VERSION ""

NS_ :

BS_:

BU_: WCM4 WCM3 WCM2 WCM VPM VLM VKM VICM VECM VDM VCU_RTOS_ETH VCU_ENTRY_ETH VCU_AGVM_ETH VCU UVM UPM TIM TEST_TOOL_1 TCP_ETH TCP TCM TCCM SRR_SRR_ETH SRR_SRR SRR_SLR_ETH SRR_SLR SRR_RR SRR_RF_ETH SRR_RF SRR_LR_CR SRR_LF_ETH SRR_LF SIB SDM SCL SBZA_R SBZA_L SBM SAM_RR SAM_RF SAM_LR SAM_LF SAM_BH SADS RadioLow_ETH RadioLow RSI_RTOS_ETH RSI RDCM PTM PLCM PFCM PDR_ETH PDR PCM PA ODS2 ODS NVM MTCM_R MTCM_L MSM_RR MSM_P MSM_LR MSM_D MSB2 MSB1 MRCM_R MRCM_L MFC LRR_RR_ETH LRR_LR_ETH LRR_CF_ETH LRR LRL_CF_ETH LIB_48V LIB1 IPC_INT IPC_GP IPC ICS_Info ICCM HVAC_FP_R HVAC_FP_F HUD_CAN HDLM FPI_RTOS_ETH FPI FOPM FCM_LC FCM EPSb EPS_1 EPSRAb EPSRAa EPS EOCM_HC_Superset EOCM_HCP2 EOCM ELM ECP_X1 ECP_S2 ECP_S ECP_MC ECP_H3 ECP_H2 ECP_H1 ECP_E ECM EBCM DMS DEFC DCM CSM_ETH CSM_AV CSM CGM_OTA_ETH CGM BSM_MH BSM_HEV BSM BCM ARS ARB APA AOS AMP ALC AHS AHL_AFL ADIMb ADIMa ACP2_MCU

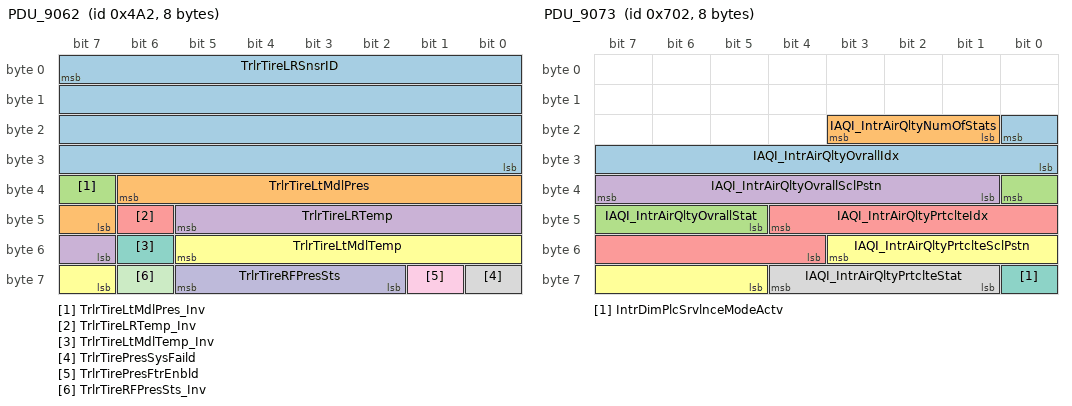
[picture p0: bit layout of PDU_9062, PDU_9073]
BO_ 1186 PDU_9062: 8 CGM
 SG_ TrlrTireLRSnsrID : 7|32@0+ (1,0) [0|4.29497e+009] "" CSM,CSM_AV,VCU
 SG_ TrlrTireLtMdlPres : 38|8@0+ (4,0) [0|1020] "kPaG" VKM,CSM,CSM_AV,VCU
 SG_ TrlrTireLtMdlPres_Inv : 39|1@0+ (1,0) [0|1] "" VKM,CSM,CSM_AV,VCU
 SG_ TrlrTireLRTemp : 45|7@0+ (1,-20) [-20|107] "degC" CSM,CSM_AV,VCU
 SG_ TrlrTireLRTemp_Inv : 46|1@0+ (1,0) [0|1] "" CSM,CSM_AV,VCU
 SG_ TrlrTireLtMdlTemp : 53|7@0+ (1,-20) [-20|107] "degC" CSM,CSM_AV,VCU
 SG_ TrlrTireLtMdlTemp_Inv : 54|1@0+ (1,0) [0|1] "" CSM,CSM_AV,VCU
 SG_ TrlrTirePresSysFaild : 56|1@0+ (1,0) [0|1] "" CSM,CSM_AV,VCU
 SG_ TrlrTirePresFtrEnbld : 57|1@0+ (1,0) [0|1] "" CSM,CSM_AV,VCU
 SG_ TrlrTireRFPresSts : 61|4@0+ (1,0) [0|8] "" VKM,CSM,CSM_AV,VCU
 SG_ TrlrTireRFPresSts_Inv : 62|1@0+ (1,0) [0|1] "" VKM,CSM,CSM_AV,VCU

BO_ 1889 PDU_9063: 8 CGM
 SG_ WlkAwyLckCstAvlFlg1 : 0|1@0+ (1,0) [0|1] "" RadioLow,CSM,CSM_AV,VCU
 SG_ VehLctrLghtsCstAvlFlg7 : 1|1@0+ (1,0) [0|1] "" RadioLow,CSM,CSM_AV,VCU
 SG_ VehLctrLghtsCstAvlFlg6 : 2|1@0+ (1,0) [0|1] "" RadioLow,CSM,CSM_AV,VCU
 SG_ VehLctrLghtsCstAvlFlg5 : 3|1@0+ (1,0) [0|1] "" RadioLow,CSM,CSM_AV,VCU
 SG_ VehLctrLghtsCstAvlFlg4 : 4|1@0+ (1,0) [0|1] "" RadioLow,CSM,CSM_AV,VCU
 SG_ VehLctrLghtsCstAvlFlg3 : 5|1@0+ (1,0) [0|1] "" RadioLow,CSM,CSM_AV,VCU
 SG_ VehLctrLghtsCstAvlFlg2 : 6|1@0+ (1,0) [0|1] "" RadioLow,CSM,CSM_AV,VCU
 SG_ VehLctrLghtsCstAvlFlg1 : 7|1@0+ (1,0) [0|1] "" RadioLow,CSM,CSM_AV,VCU
 SG_ AmbtLgtGblPrxmtyEnCstAvlFlg2 : 8|1@0+ (1,0) [0|1] "" VCU
 SG_ AmbtLgtGblPrxmtyEnCstAvlFlg1 : 9|1@0+ (1,0) [0|1] "" VCU
 SG_ WlkAwyLckCstAvlFlg7 : 10|1@0+ (1,0) [0|1] "" RadioLow,CSM,CSM_AV,VCU
 SG_ WlkAwyLckCstAvlFlg6 : 11|1@0+ (1,0) [0|1] "" RadioLow,CSM,CSM_AV,VCU
 SG_ WlkAwyLckCstAvlFlg5 : 12|1@0+ (1,0) [0|1] "" RadioLow,CSM,CSM_AV,VCU
 SG_ WlkAwyLckCstAvlFlg4 : 13|1@0+ (1,0) [0|1] "" RadioLow,CSM,CSM_AV,VCU
 SG_ WlkAwyLckCstAvlFlg3 : 14|1@0+ (1,0) [0|1] "" RadioLow,CSM,CSM_AV,VCU
 SG_ WlkAwyLckCstAvlFlg2 : 15|1@0+ (1,0) [0|1] "" RadioLow,CSM,CSM_AV,VCU
 SG_ Aux1AmbtColrCtlCstAvlFlg33 : 16|1@0+ (1,0) [0|1] "" VCU
 SG_ Aux1AmbtColrCtlCstAvlFlg32 : 17|1@0+ (1,0) [0|1] "" VCU
 SG_ AmbtLgtGblPrxmtyEnCstSetAval : 18|1@0+ (1,0) [0|1] "" VCU
 SG_ AmbtLgtGblPrxmtyEnCstAvlFlg7 : 19|1@0+ (1,0) [0|1] "" VCU
 SG_ AmbtLgtGblPrxmtyEnCstAvlFlg6 : 20|1@0+ (1,0) [0|1] "" VCU
 SG_ AmbtLgtGblPrxmtyEnCstAvlFlg5 : 21|1@0+ (1,0) [0|1] "" VCU
 SG_ AmbtLgtGblPrxmtyEnCstAvlFlg4 : 22|1@0+ (1,0) [0|1] "" VCU
 SG_ AmbtLgtGblPrxmtyEnCstAvlFlg3 : 23|1@0+ (1,0) [0|1] "" VCU
 SG_ Aux1AmbtColrCtlCstAvlFlg41 : 24|1@0+ (1,0) [0|1] "" VCU
 SG_ Aux1AmbtColrCtlCstAvlFlg40 : 25|1@0+ (1,0) [0|1] "" VCU
 SG_ Aux1AmbtColrCtlCstAvlFlg39 : 26|1@0+ (1,0) [0|1] "" VCU
 SG_ Aux1AmbtColrCtlCstAvlFlg38 : 27|1@0+ (1,0) [0|1] "" VCU
 SG_ Aux1AmbtColrCtlCstAvlFlg37 : 28|1@0+ (1,0) [0|1] "" VCU
 SG_ Aux1AmbtColrCtlCstAvlFlg36 : 29|1@0+ (1,0) [0|1] "" VCU
 SG_ Aux1AmbtColrCtlCstAvlFlg35 : 30|1@0+ (1,0) [0|1] "" VCU
 SG_ Aux1AmbtColrCtlCstAvlFlg34 : 31|1@0+ (1,0) [0|1] "" VCU
 SG_ Aux1AmbtColrCtlCstAvlFlg49 : 32|1@0+ (1,0) [0|1] "" VCU
 SG_ Aux1AmbtColrCtlCstAvlFlg48 : 33|1@0+ (1,0) [0|1] "" VCU
 SG_ Aux1AmbtColrCtlCstAvlFlg47 : 34|1@0+ (1,0) [0|1] "" VCU
 SG_ Aux1AmbtColrCtlCstAvlFlg46 : 35|1@0+ (1,0) [0|1] "" VCU
 SG_ Aux1AmbtColrCtlCstAvlFlg45 : 36|1@0+ (1,0) [0|1] "" VCU
 SG_ Aux1AmbtColrCtlCstAvlFlg44 : 37|1@0+ (1,0) [0|1] "" VCU
 SG_ Aux1AmbtColrCtlCstAvlFlg43 : 38|1@0+ (1,0) [0|1] "" VCU
 SG_ Aux1AmbtColrCtlCstAvlFlg42 : 39|1@0+ (1,0) [0|1] "" VCU
 SG_ Aux1AmbtColrCtlCstAvlFlg57 : 40|1@0+ (1,0) [0|1] "" VCU
 SG_ Aux1AmbtColrCtlCstAvlFlg56 : 41|1@0+ (1,0) [0|1] "" VCU
 SG_ Aux1AmbtColrCtlCstAvlFlg55 : 42|1@0+ (1,0) [0|1] "" VCU
 SG_ Aux1AmbtColrCtlCstAvlFlg54 : 43|1@0+ (1,0) [0|1] "" VCU
 SG_ Aux1AmbtColrCtlCstAvlFlg53 : 44|1@0+ (1,0) [0|1] "" VCU
 SG_ Aux1AmbtColrCtlCstAvlFlg52 : 45|1@0+ (1,0) [0|1] "" VCU
 SG_ Aux1AmbtColrCtlCstAvlFlg51 : 46|1@0+ (1,0) [0|1] "" VCU
 SG_ Aux1AmbtColrCtlCstAvlFlg50 : 47|1@0+ (1,0) [0|1] "" VCU
 SG_ Aux1AmbtColrCtlCstAvlFlg65 : 48|1@0+ (1,0) [0|1] "" VCU
 SG_ Aux1AmbtColrCtlCstAvlFlg64 : 49|1@0+ (1,0) [0|1] "" VCU
 SG_ Aux1AmbtColrCtlCstAvlFlg63 : 50|1@0+ (1,0) [0|1] "" VCU
 SG_ Aux1AmbtColrCtlCstAvlFlg62 : 51|1@0+ (1,0) [0|1] "" VCU
 SG_ Aux1AmbtColrCtlCstAvlFlg61 : 52|1@0+ (1,0) [0|1] "" VCU
 SG_ Aux1AmbtColrCtlCstAvlFlg60 : 53|1@0+ (1,0) [0|1] "" VCU
 SG_ Aux1AmbtColrCtlCstAvlFlg59 : 54|1@0+ (1,0) [0|1] "" VCU
 SG_ Aux1AmbtColrCtlCstAvlFlg58 : 55|1@0+ (1,0) [0|1] "" VCU
 SG_ Aux1AmbtColrCtlCstAvlFlg73 : 56|1@0+ (1,0) [0|1] "" VCU
 SG_ Aux1AmbtColrCtlCstAvlFlg72 : 57|1@0+ (1,0) [0|1] "" VCU
 SG_ Aux1AmbtColrCtlCstAvlFlg71 : 58|1@0+ (1,0) [0|1] "" VCU
 SG_ Aux1AmbtColrCtlCstAvlFlg70 : 59|1@0+ (1,0) [0|1] "" VCU
 SG_ Aux1AmbtColrCtlCstAvlFlg69 : 60|1@0+ (1,0) [0|1] "" VCU
 SG_ Aux1AmbtColrCtlCstAvlFlg68 : 61|1@0+ (1,0) [0|1] "" VCU
 SG_ Aux1AmbtColrCtlCstAvlFlg67 : 62|1@0+ (1,0) [0|1] "" VCU
 SG_ Aux1AmbtColrCtlCstAvlFlg66 : 63|1@0+ (1,0) [0|1] "" VCU

BO_ 1810 PDU_9064: 2 CGM
 SG_ VehIdNmDig1 : 7|8@0+ (1,0) [0|255] "" FPI,RSI,RadioLow,TCP,CSM,CSM_AV,VCU

BO_ 1880 PDU_9065: 8 CGM
 SG_ TrlrTireLtMdlSnsrID : 7|32@0+ (1,0) [0|4.29497e+009] "" CSM,CSM_AV,VCU
 SG_ TrlrTireRFSnsrID : 39|32@0+ (1,0) [0|4.29497e+009] "" CSM,CSM_AV,VCU

BO_ 1185 PDU_9066: 8 CGM
 SG_ TrlrTireRRSnsrID : 7|32@0+ (1,0) [0|4.29497e+009] "" CSM,CSM_AV,VCU
 SG_ TrlrTireRtMdlSnsrID : 39|32@0+ (1,0) [0|4.29497e+009] "" CSM,CSM_AV,VCU

BO_ 1881 PDU_9067: 8 CGM
 SG_ TrlrTireRFPres : 6|8@0+ (4,0) [0|1020] "kPaG" VKM,CSM,CSM_AV,VCU
 SG_ TrlrTireRFPres_Inv : 7|1@0+ (1,0) [0|1] "" VKM,CSM,CSM_AV,VCU
 SG_ TrlrTireRRPres : 13|8@0+ (4,0) [0|1020] "kPaG" VKM,CSM,CSM_AV,VCU
 SG_ TrlrTireRRPres_Inv : 14|1@0+ (1,0) [0|1] "" VKM,CSM,CSM_AV,VCU
 SG_ TrlrTireRtMdlPres : 20|8@0+ (4,0) [0|1020] "kPaG" VKM,CSM,CSM_AV,VCU
 SG_ TrlrTireRtMdlPres_Inv : 21|1@0+ (1,0) [0|1] "" VKM,CSM,CSM_AV,VCU
 SG_ TrlrTireRFTemp : 27|7@0+ (1,-20) [-20|107] "degC" CSM,CSM_AV,VCU
 SG_ TrlrTireRFTemp_Inv : 28|1@0+ (1,0) [0|1] "" CSM,CSM_AV,VCU
 SG_ TrlrTireRRTemp : 35|7@0+ (1,-20) [-20|107] "degC" CSM,CSM_AV,VCU
 SG_ TrlrTireRRTemp_Inv : 36|1@0+ (1,0) [0|1] "" CSM,CSM_AV,VCU
 SG_ TrlrTireRtMdlTemp : 43|7@0+ (1,-20) [-20|107] "degC" CSM,CSM_AV,VCU
 SG_ TrlrTireRtMdlTemp_Inv : 44|1@0+ (1,0) [0|1] "" CSM,CSM_AV,VCU
 SG_ TrlrTireRRPresSts : 51|4@0+ (1,0) [0|8] "" VKM,CSM,CSM_AV,VCU
 SG_ TrlrTireRRPresSts_Inv : 52|1@0+ (1,0) [0|1] "" VKM,CSM,CSM_AV,VCU
 SG_ Aux1AmbtColrCtlCstAvlFlg86 : 56|1@0+ (1,0) [0|1] "" VCU
 SG_ Aux1AmbtColrCtlCstAvlFlg85 : 57|1@0+ (1,0) [0|1] "" VCU
 SG_ Aux1AmbtColrCtlCstAvlFlg84 : 58|1@0+ (1,0) [0|1] "" VCU
 SG_ TrlrTireRtMdlPresSts : 62|4@0+ (1,0) [0|8] "" VKM,CSM,CSM_AV,VCU
 SG_ TrlrTireRtMdlPresSts_Inv : 63|1@0+ (1,0) [0|1] "" VKM,CSM,CSM_AV,VCU

BO_ 1184 PDU_9068: 8 CGM
 SG_ VCCLS_CrgLmpHtchAval : 0|1@0+ (1,0) [0|1] "" VCU
 SG_ VCCLS_CrgLmpCurrSeltnVal : 2|2@0+ (1,0) [0|2] "" VCU
 SG_ VCCLS_CrgLmpAval : 3|1@0+ (1,0) [0|1] "" VCU
 SG_ VCCLS_CrgBedLmpCurrSeltnVal : 5|2@0+ (1,0) [0|2] "" VCU
 SG_ VCCLS_CrgBedLmpAval : 6|1@0+ (1,0) [0|1] "" VCU
 SG_ VCCLS_AllCrgLmpUsrCtlAllwd : 7|1@0+ (1,0) [0|1] "" VCU
 SG_ VCDLS_DomeDftCurrSeltnVal : 9|2@0+ (1,0) [0|2] "" VCU
 SG_ VCDLS_DomeDftAval : 10|1@0+ (1,0) [0|1] "" VCU
 SG_ VCCLS_CrgMirLmpCurrSeltnVal : 12|2@0+ (1,0) [0|2] "" VCU
 SG_ VCCLS_CrgMirLmpAval : 13|1@0+ (1,0) [0|1] "" VCU
 SG_ VCCLS_CrgLmpHtchCurrSeltnVal : 15|2@0+ (1,0) [0|2] "" VCU
 SG_ VCCSLS_CtlAval : 16|1@0+ (1,0) [0|1] "" VCU
 SG_ VCAHBS_UsrCtlAllwd : 17|1@0+ (1,0) [0|1] "" VCU
 SG_ VCAHBS_CurrSeltnVal : 19|2@0+ (1,0) [0|2] "" VCU
 SG_ VCAHBS_CtlAval : 20|1@0+ (1,0) [0|1] "" VCU
 SG_ VCDLS_DomeLgtCurrSeltnVal : 22|2@0+ (1,0) [0|2] "" VCU
 SG_ VCDLS_DomeLgtAval : 23|1@0+ (1,0) [0|1] "" VCU
 SG_ VCFLRS_CtlAval : 24|1@0+ (1,0) [0|1] "" VCU
 SG_ VCFLFS_UsrCtlAllwd : 25|1@0+ (1,0) [0|1] "" VCU
 SG_ VCFLFS_CurrSeltnVal : 27|2@0+ (1,0) [0|2] "" VCU
 SG_ VCFLFS_CtlAval : 28|1@0+ (1,0) [0|1] "" VCU
 SG_ VCCSLS_MsmtchIndOn : 29|1@0+ (1,0) [0|1] "" VCU
 SG_ VCCSLS_CurrSeltnVal : 31|2@0+ (1,0) [0|2] "" VCU
 SG_ RrBlw2Cmd : 33|10@0+ (0.09765,0) [0|99.8959] "%" VCU
 SG_ VCPWLS_CurrSeltnVal : 35|2@0+ (1,0) [0|2] "" VCU
 SG_ VCPWLS_CtlAval : 36|1@0+ (1,0) [0|1] "" VCU
 SG_ VCFLRS_UsrCtlAllwd : 37|1@0+ (1,0) [0|1] "" VCU
 SG_ VCFLRS_CurrSeltnVal : 39|2@0+ (1,0) [0|2] "" VCU
 SG_ CbnAirClnFltrtnCstCurrSetVal : 49|3@0+ (1,0) [0|2] "" VCU
 SG_ AutoNckScrfCstCurrSetVal : 52|3@0+ (1,0) [0|3] "" VCU
 SG_ AutoAirOtltAmgCstCurrSetVal : 55|3@0+ (1,0) [0|2] "" VCU
 SG_ FrtClsrAccssVirtCtlAval : 58|1@0+ (1,0) [0|1] "" VCU
 SG_ FrtClsrAccssVirtCtlAllwd : 59|1@0+ (1,0) [0|1] "" VCU
 SG_ DlvryModeWrnIndReq : 62|3@0+ (1,0) [0|4] "" VCU

BO_ 1412 PDU_9069: 8 CGM
 SG_ IHVSLR_HtdCushBckLvl2 : 0|1@0+ (1,0) [0|1] "" HVAC_FP_R,VCU
 SG_ IHVSLR_HtdCushBckLvl1 : 1|1@0+ (1,0) [0|1] "" HVAC_FP_R,VCU
 SG_ IHVSLR_HtdCushBckAuto : 2|1@0+ (1,0) [0|1] "" HVAC_FP_R,VCU
 SG_ IHVSLR_HtdBckMd : 3|1@0+ (1,0) [0|1] "" HVAC_FP_R,VCU
 SG_ IHVSLR_HtdBckLvl3 : 4|1@0+ (1,0) [0|1] "" HVAC_FP_R,VCU
 SG_ IHVSLR_HtdBckLvl2 : 5|1@0+ (1,0) [0|1] "" HVAC_FP_R,VCU
 SG_ IHVSLR_HtdBckLvl1 : 6|1@0+ (1,0) [0|1] "" HVAC_FP_R,VCU
 SG_ IHVSLR_HtdBckAuto : 7|1@0+ (1,0) [0|1] "" HVAC_FP_R,VCU
 SG_ IHVSRR_HtdBckAuto : 8|1@0+ (1,0) [0|1] "" HVAC_FP_R,VCU
 SG_ IHVSLR_VntMd : 9|1@0+ (1,0) [0|1] "" HVAC_FP_R,VCU
 SG_ IHVSLR_VntLvl3 : 10|1@0+ (1,0) [0|1] "" HVAC_FP_R,VCU
 SG_ IHVSLR_VntLvl2 : 11|1@0+ (1,0) [0|1] "" HVAC_FP_R,VCU
 SG_ IHVSLR_VntLvl1 : 12|1@0+ (1,0) [0|1] "" HVAC_FP_R,VCU
 SG_ IHVSLR_VntAuto : 13|1@0+ (1,0) [0|1] "" HVAC_FP_R,VCU
 SG_ IHVSLR_HtdCushBckMd : 14|1@0+ (1,0) [0|1] "" HVAC_FP_R,VCU
 SG_ IHVSLR_HtdCushBckLvl3 : 15|1@0+ (1,0) [0|1] "" HVAC_FP_R,VCU
 SG_ IHVSRR_HtdCushBckLvl3 : 16|1@0+ (1,0) [0|1] "" HVAC_FP_R,VCU
 SG_ IHVSRR_HtdCushBckLvl2 : 17|1@0+ (1,0) [0|1] "" HVAC_FP_R,VCU
 SG_ IHVSRR_HtdCushBckLvl1 : 18|1@0+ (1,0) [0|1] "" HVAC_FP_R,VCU
 SG_ IHVSRR_HtdCushBckAuto : 19|1@0+ (1,0) [0|1] "" HVAC_FP_R,VCU
 SG_ IHVSRR_HtdBckMd : 20|1@0+ (1,0) [0|1] "" HVAC_FP_R,VCU
 SG_ IHVSRR_HtdBckLvl3 : 21|1@0+ (1,0) [0|1] "" HVAC_FP_R,VCU
 SG_ IHVSRR_HtdBckLvl2 : 22|1@0+ (1,0) [0|1] "" HVAC_FP_R,VCU
 SG_ IHVSRR_HtdBckLvl1 : 23|1@0+ (1,0) [0|1] "" HVAC_FP_R,VCU
 SG_ BatSvrMdSevLvl : 25|8@0+ (1,0) [0|255] "" RadioLow,TCP,CSM,CSM_AV,VCU
 SG_ IHVSRR_VntMd : 26|1@0+ (1,0) [0|1] "" HVAC_FP_R,VCU
 SG_ IHVSRR_VntLvl3 : 27|1@0+ (1,0) [0|1] "" HVAC_FP_R,VCU
 SG_ IHVSRR_VntLvl2 : 28|1@0+ (1,0) [0|1] "" HVAC_FP_R,VCU
 SG_ IHVSRR_VntLvl1 : 29|1@0+ (1,0) [0|1] "" HVAC_FP_R,VCU
 SG_ IHVSRR_VntAuto : 30|1@0+ (1,0) [0|1] "" HVAC_FP_R,VCU
 SG_ IHVSRR_HtdCushBckMd : 31|1@0+ (1,0) [0|1] "" HVAC_FP_R,VCU
 SG_ ClmCtlCbnAirCondCustLdEstd : 33|7@0+ (1,0) [0|127] "%" IPC,IPC_INT,VCU
 SG_ IndAirDstFL : 42|4@0+ (1,0) [0|9] "" HVAC_FP_F,HVAC_FP_R,RadioLow,CSM,CSM_AV,IPC,IPC_INT,VCU
 SG_ DrHndlLFAuthReqd : 48|1@0+ (1,0) [0|1] "" VKM
 SG_ AirDflctrIndReq : 50|2@0+ (1,0) [0|2] "" IPC,IPC_INT,VCU
 SG_ IndAirDstFR : 54|4@0+ (1,0) [0|9] "" HVAC_FP_F,HVAC_FP_R,RadioLow,CSM,CSM_AV,VCU
 SG_ HVACUsrCtlIntrctnDispReqd : 59|1@0+ (1,0) [0|1] "" RadioLow,CSM,CSM_AV,VCU
 SG_ FrtClsrRelAuthReqd : 60|1@0+ (1,0) [0|1] "" VKM
 SG_ DrHndlRRAuthReqd : 61|1@0+ (1,0) [0|1] "" VKM
 SG_ DrHndlRFAuthReqd : 62|1@0+ (1,0) [0|1] "" VKM
 SG_ DrHndlLRAuthReqd : 63|1@0+ (1,0) [0|1] "" VKM

BO_ 1413 PDU_9070: 8 CGM
 SG_ IndTmpStngLvlFR : 0|7@0+ (1,0) [0|127] "" HVAC_FP_F,RadioLow,CSM,CSM_AV,VCU
 SG_ IndTmpStngLvlFL : 7|7@0+ (1,0) [0|127] "" HVAC_FP_F,RadioLow,TCP,CSM,CSM_AV,VCU
 SG_ IndTmpStngLvlRL : 9|7@0+ (1,0) [0|127] "" HVAC_FP_F,HVAC_FP_R,RadioLow,CSM,CSM_AV,VCU
 SG_ IndTmpStngLvlRR : 18|7@0+ (1,0) [0|127] "" HVAC_FP_F,HVAC_FP_R,RadioLow,CSM,CSM_AV,VCU
 SG_ IndAirDstRL : 27|4@0+ (1,0) [0|8] "" HVAC_FP_F,HVAC_FP_R,RadioLow,CSM,CSM_AV,VCU
 SG_ IndBlwStngLvlFrt : 35|4@0+ (1,0) [0|15] "" HVAC_FP_F,RadioLow,CSM,CSM_AV,VCU
 SG_ IndAirDstRR : 39|4@0+ (1,0) [0|8] "" HVAC_FP_F,HVAC_FP_R,RadioLow,CSM,CSM_AV,VCU
 SG_ IndBlwStngStRr : 41|2@0+ (1,0) [0|2] "" HVAC_FP_F,HVAC_FP_R,RadioLow,CSM,CSM_AV,VCU
 SG_ IndBlwStngStFrt : 43|2@0+ (1,0) [0|2] "" HVAC_FP_F,RadioLow,CSM,CSM_AV,VCU
 SG_ IndBlwStngLvlRr : 47|4@0+ (1,0) [0|15] "" HVAC_FP_F,HVAC_FP_R,RadioLow,CSM,CSM_AV,VCU
 SG_ IndHtdFrtWshldSet : 48|1@0+ (1,0) [0|1] "" HVAC_FP_F,RadioLow,CSM,CSM_AV,VCU
 SG_ IndFrtHVAC_On : 49|1@0+ (1,0) [0|1] "" HVAC_FP_F,RadioLow,CSM,CSM_AV,VCU
 SG_ IndRecircStng : 51|2@0+ (1,0) [0|2] "" HVAC_FP_F,RadioLow,CSM,CSM_AV,VCU
 SG_ IndCompStng : 53|2@0+ (1,0) [0|3] "" HVAC_FP_F,RadioLow,CSM,CSM_AV,IPC,IPC_INT,VCU
 SG_ IndSYNC_Rr : 59|1@0+ (1,0) [0|1] "" HVAC_FP_F,HVAC_FP_R,RadioLow,CSM,CSM_AV,VCU
 SG_ IndSYNC_All : 60|1@0+ (1,0) [0|1] "" HVAC_FP_F,HVAC_FP_R,RadioLow,CSM,CSM_AV,VCU
 SG_ IndRrWndDfgStng : 61|1@0+ (1,0) [0|1] "" HVAC_FP_F,RadioLow,CSM,CSM_AV,IPC,IPC_INT,VCU
 SG_ IndRrHVAC_On : 62|1@0+ (1,0) [0|1] "" HVAC_FP_F,HVAC_FP_R,RadioLow,CSM,CSM_AV,VCU
 SG_ IndRrHVAC_Lckd : 63|1@0+ (1,0) [0|1] "" HVAC_FP_F,HVAC_FP_R,RadioLow,CSM,CSM_AV,VCU

BO_ 1414 PDU_9071: 8 CGM
 SG_ IndTmpStngStRL : 1|3@0+ (1,0) [0|4] "" HVAC_FP_F,HVAC_FP_R,RadioLow,CSM,CSM_AV,VCU
 SG_ IndTmpStngStFR : 4|3@0+ (1,0) [0|4] "" HVAC_FP_F,RadioLow,CSM,CSM_AV,VCU
 SG_ IndTmpStngStFL : 7|3@0+ (1,0) [0|4] "" HVAC_FP_F,RadioLow,TCP,CSM,CSM_AV,VCU
 SG_ PwrRrClsrCstCurrSetVal : 8|3@0+ (1,0) [0|7] "" RadioLow,VKM,CSM,CSM_AV,VCU
 SG_ PFASndSeltnCstCurrSetVal : 11|3@0+ (1,0) [0|7] "" CSM,CSM_AV,VCU
 SG_ IndTmpStngStRR : 14|3@0+ (1,0) [0|4] "" HVAC_FP_F,HVAC_FP_R,RadioLow,CSM,CSM_AV,VCU
 SG_ ManlPrkLmpChmEvtSt : 17|2@0+ (1,0) [0|2] "" IPC,IPC_INT,VCU
 SG_ LDCLDlydLkChmEvSt : 19|2@0+ (1,0) [0|2] "" IPC,IPC_INT,VCU
 SG_ KeyInRmdrChmEvntSt : 21|2@0+ (1,0) [0|2] "" IPC,IPC_INT,VCU
 SG_ PwrRrClsrNtfnChmEvntStat : 25|2@0+ (1,0) [0|2] "" CSM,CSM_AV,IPC,IPC_INT,VCU
 SG_ PwrRrClsrNormOpChmEvntStat : 27|2@0+ (1,0) [0|2] "" CSM,CSM_AV,IPC,IPC_INT,VCU
 SG_ OneSidedPrkLmpActvnChmEvtSt : 29|2@0+ (1,0) [0|2] "" IPC,IPC_INT,VCU
 SG_ NoRtDetWrngChmEvSt : 31|2@0+ (1,0) [0|2] "" IPC,IPC_INT,VCU
 SG_ RetainedACCpwrStatus : 32|1@0+ (1,0) [0|1] "" TCP
 SG_ PMMiRAPStatus : 33|1@0+ (1,0) [0|1] "" WCM,WCM2,WCM3,WCM4
 SG_ ShfttoPrkChmEvntSt : 35|2@0+ (1,0) [0|2] "" IPC,IPC_INT,VCU
 SG_ RemLtInVhWrngChmEvSt : 37|2@0+ (1,0) [0|2] "" IPC,IPC_INT,VCU
 SG_ PwrRrClsrObstclChmEvntStat : 39|2@0+ (1,0) [0|2] "" CSM,CSM_AV,IPC,IPC_INT,VCU
 SG_ PFASndSeltnCstSetAval : 40|1@0+ (1,0) [0|1] "" CSM,CSM_AV,VCU
 SG_ PFASndSeltnCstAvlFlg7 : 41|1@0+ (1,0) [0|1] "" CSM,CSM_AV,VCU
 SG_ PFASndSeltnCstAvlFlg6 : 42|1@0+ (1,0) [0|1] "" CSM,CSM_AV,VCU
 SG_ PFASndSeltnCstAvlFlg5 : 43|1@0+ (1,0) [0|1] "" CSM,CSM_AV,VCU
 SG_ PFASndSeltnCstAvlFlg4 : 44|1@0+ (1,0) [0|1] "" CSM,CSM_AV,VCU
 SG_ PFASndSeltnCstAvlFlg3 : 45|1@0+ (1,0) [0|1] "" CSM,CSM_AV,VCU
 SG_ PFASndSeltnCstAvlFlg2 : 46|1@0+ (1,0) [0|1] "" CSM,CSM_AV,VCU
 SG_ PFASndSeltnCstAvlFlg1 : 47|1@0+ (1,0) [0|1] "" CSM,CSM_AV,VCU
 SG_ PwrRrClsrCstSetAval : 48|1@0+ (1,0) [0|1] "" RadioLow,CSM,CSM_AV,VCU
 SG_ PwrRrClsrCstAvlFlg7 : 49|1@0+ (1,0) [0|1] "" RadioLow,CSM,CSM_AV,VCU
 SG_ PwrRrClsrCstAvlFlg6 : 50|1@0+ (1,0) [0|1] "" RadioLow,CSM,CSM_AV,VCU
 SG_ PwrRrClsrCstAvlFlg5 : 51|1@0+ (1,0) [0|1] "" RadioLow,CSM,CSM_AV,VCU
 SG_ PwrRrClsrCstAvlFlg4 : 52|1@0+ (1,0) [0|1] "" RadioLow,CSM,CSM_AV,VCU
 SG_ PwrRrClsrCstAvlFlg3 : 53|1@0+ (1,0) [0|1] "" RadioLow,CSM,CSM_AV,VCU
 SG_ PwrRrClsrCstAvlFlg2 : 54|1@0+ (1,0) [0|1] "" RadioLow,CSM,CSM_AV,VCU
 SG_ PwrRrClsrCstAvlFlg1 : 55|1@0+ (1,0) [0|1] "" RadioLow,CSM,CSM_AV,VCU
 SG_ StBltShfIntlkCstAvlFlg7 : 56|1@0+ (1,0) [0|1] "" RadioLow,CSM,CSM_AV,VCU
 SG_ StBltShfIntlkCstAvlFlg6 : 57|1@0+ (1,0) [0|1] "" RadioLow,CSM,CSM_AV,VCU
 SG_ StBltShfIntlkCstAvlFlg5 : 58|1@0+ (1,0) [0|1] "" RadioLow,CSM,CSM_AV,VCU
 SG_ StBltShfIntlkCstAvlFlg4 : 59|1@0+ (1,0) [0|1] "" RadioLow,CSM,CSM_AV,VCU
 SG_ StBltShfIntlkCstAvlFlg3 : 60|1@0+ (1,0) [0|1] "" RadioLow,CSM,CSM_AV,VCU
 SG_ StBltShfIntlkCstAvlFlg2 : 61|1@0+ (1,0) [0|1] "" RadioLow,CSM,CSM_AV,VCU
 SG_ StBltShfIntlkCstAvlFlg1 : 62|1@0+ (1,0) [0|1] "" RadioLow,CSM,CSM_AV,VCU
 SG_ RrClsrRelAuthReqd : 63|1@0+ (1,0) [0|1] "" VKM

BO_ 1272 PDU_9072: 8 CGM
 SG_ IndInzrStat : 2|3@0+ (1,0) [0|4] "" HVAC_FP_F,RadioLow,CSM,CSM_AV,VCU
 SG_ ConThftAlrmTrg : 7|5@0+ (1,0) [0|20] "" TCP,VKM
 SG_ ClmCtlBatSvrIndOn : 8|1@0+ (1,0) [0|1] "" IPC,IPC_INT,VCU
 SG_ AutoLgtsInActvIndOn : 9|1@0+ (1,0) [0|1] "" CSM,CSM_AV,IPC,IPC_INT,VCU
 SG_ AutoLgtsActvIndOn : 10|1@0+ (1,0) [0|1] "" CSM,CSM_AV,IPC,IPC_INT,VCU
 SG_ ACCmpsrOprtng : 11|1@0+ (1,0) [0|1] "" TCP
 SG_ HtdStrgWhlInd_HVAC_FP_F : 13|2@0+ (1,0) [0|3] "" HVAC_FP_F
 SG_ HtdFrntWSSt : 15|2@0+ (1,0) [0|2] "" IPC,IPC_INT,VCU
 SG_ ConThftSrvcIO : 16|1@0+ (1,0) [0|1] "" TCP,CSM,CSM_AV,IPC,IPC_INT,VCU
 SG_ ConThftAttmpdIO : 17|1@0+ (1,0) [0|1] "" TCP,CSM,CSM_AV,IPC,IPC_INT,VCU
 SG_ CnvtBkWndNotNormzIO : 18|1@0+ (1,0) [0|1] "" IPC,IPC_INT,VCU
 SG_ CmpSftTopMotBfrOpTrnkIO : 19|1@0+ (1,0) [0|1] "" CSM,CSM_AV,IPC,IPC_INT,VCU
 SG_ CmbdDrHndlActvRF : 20|1@0+ (1,0) [0|1] "" CSM,CSM_AV,VCU
 SG_ CmbdDrHndlActvLF : 21|1@0+ (1,0) [0|1] "" CSM,CSM_AV,VCU
 SG_ DrIntHndlActnStatLF : 24|1@0+ (1,0) [0|1] "" RadioLow,CSM,CSM_AV,VCU
 SG_ DrExtHndlActnStatRR : 25|1@0+ (1,0) [0|1] "" RadioLow,CSM,CSM_AV,VCU
 SG_ DrExtHndlActnStatRF : 26|1@0+ (1,0) [0|1] "" RadioLow,CSM,CSM_AV,VCU
 SG_ DrExtHndlActnStatLR : 27|1@0+ (1,0) [0|1] "" RadioLow,CSM,CSM_AV,VCU
 SG_ DrExtHndlActnStatLF : 28|1@0+ (1,0) [0|1] "" RadioLow,CSM,CSM_AV,VCU
 SG_ DlydAccTmrActv : 29|1@0+ (1,0) [0|1] "" WCM,WCM2,WCM3,WCM4
 SG_ CrgLghtEnbldIO : 30|1@0+ (1,0) [0|1] "" IPC,IPC_INT,VCU
 SG_ CrgLghtDsbldIO : 31|1@0+ (1,0) [0|1] "" IPC,IPC_INT,VCU
 SG_ FrtClmAppFltDtnActv : 32|1@0+ (1,0) [0|1] "" RadioLow,CSM,CSM_AV,VCU
 SG_ FobProgMdStatCmplt : 33|1@0+ (1,0) [0|1] "" IPC,IPC_INT,VCU
 SG_ FobPrevLrndIndOn : 34|1@0+ (1,0) [0|1] "" IPC,IPC_INT,VCU
 SG_ FobPogLimRchdIndOn : 35|1@0+ (1,0) [0|1] "" IPC,IPC_INT,VCU
 SG_ EntrFobProgIndOn : 36|1@0+ (1,0) [0|1] "" IPC,IPC_INT,VCU
 SG_ DrIntHndlActnStatRR : 37|1@0+ (1,0) [0|1] "" RadioLow,CSM,CSM_AV,VCU
 SG_ DrIntHndlActnStatRF : 38|1@0+ (1,0) [0|1] "" RadioLow,CSM,CSM_AV,VCU
 SG_ DrIntHndlActnStatLR : 39|1@0+ (1,0) [0|1] "" RadioLow,CSM,CSM_AV,VCU
 SG_ HtdFrtWshldUnvIndOn : 40|1@0+ (1,0) [0|1] "" IPC,IPC_INT,VCU
 SG_ HiBmIO : 43|1@0+ (1,0) [0|1] "" CSM,CSM_AV,IPC,IPC_INT,VCU
 SG_ HazSwAtvIO : 44|1@0+ (1,0) [0|1] "" TCP,CSM,CSM_AV,IPC,IPC_INT,VCU
 SG_ HVAC_StngsCtrlAvlbl : 45|1@0+ (1,0) [0|1] "" HVAC_FP_F,HVAC_FP_R,RadioLow,CSM,CSM_AV,VCU
 SG_ FrtSnshdNormzRqrdIO : 46|1@0+ (1,0) [0|1] "" IPC,IPC_INT,VCU
 SG_ FrtCmptServIndOn : 47|1@0+ (1,0) [0|1] "" IPC,IPC_INT,VCU
 SG_ IntrSnsDsbld : 48|1@0+ (1,0) [0|1] "" IPC,IPC_INT,VCU
 SG_ InrTlgtOpnIndOn : 49|1@0+ (1,0) [0|1] "" IPC,IPC_INT,VCU
 SG_ IndTmpUnts : 50|1@0+ (1,0) [0|1] "" HVAC_FP_F,HVAC_FP_R,RadioLow,CSM,CSM_AV,VCU
 SG_ IndIntrAirQltyDispActv : 52|1@0+ (1,0) [0|1] "" RadioLow,CSM,CSM_AV,VCU
 SG_ KeyInWrnIO : 63|1@0+ (1,0) [0|1] "" VKM,IPC,IPC_INT,VCU

BO_ 1794 PDU_9073: 8 CGM
 SG_ IAQI_IntrAirQltyOvrallIdx : 16|9@0+ (1,0) [0|511] "" RadioLow,CSM,CSM_AV,VCU
 SG_ IAQI_IntrAirQltyNumOfStats : 19|3@0+ (1,2) [2|9] "" RadioLow,CSM,CSM_AV,VCU
 SG_ IAQI_IntrAirQltyOvrallStat : 32|4@0+ (1,0) [0|9] "" RadioLow,CSM,CSM_AV,VCU
 SG_ IAQI_IntrAirQltyOvrallSclPstn : 39|7@0+ (1,0) [0|127] "" RadioLow,CSM,CSM_AV,VCU
 SG_ IAQI_IntrAirQltyPrtclteIdx : 44|9@0+ (1,0) [0|511] "" RadioLow,CSM,CSM_AV,VCU
 SG_ IAQI_IntrAirQltyPrtclteSclPstn : 51|7@0+ (1,0) [0|127] "" RadioLow,CSM,CSM_AV,VCU
 SG_ IntrDimPlcSrvlnceModeActv : 56|1@0+ (1,0) [0|1] "" VCU
 SG_ IAQI_IntrAirQltyPrtclteStat : 60|4@0+ (1,0) [0|9] "" RadioLow,CSM,CSM_AV,VCU

BO_ 1271 PDU_9074: 8 CGM
 SG_ TDRCADD_LKAstAlrtsEvnts : 0|1@0+ (1,0) [0|1] "" RadioLow,TCP,CSM,CSM_AV,VCU
 SG_ TDRCADD_LDWEvnts : 1|1@0+ (1,0) [0|1] "" RadioLow,TCP,CSM,CSM_AV,VCU
 SG_ TDRCADD_FCMBrEvts : 2|1@0+ (1,0) [0|1] "" RadioLow,TCP,CSM,CSM_AV,VCU
 SG_ TDRCADD_FCImntAlrts : 3|1@0+ (1,0) [0|1] "" RadioLow,TCP,CSM,CSM_AV,VCU
 SG_ TDRCADD_FCHdwyAlrt : 4|1@0+ (1,0) [0|1] "" RadioLow,TCP,CSM,CSM_AV,VCU
 SG_ TDRCADD_DrwDrvAlrt : 5|1@0+ (1,0) [0|1] "" RadioLow,TCP,CSM,CSM_AV,VCU
 SG_ TDRCADD_DistDrvn : 6|1@0+ (1,0) [0|1] "" RadioLow,TCP,CSM,CSM_AV,VCU
 SG_ TDRCADD_ABSAtvEvt : 7|1@0+ (1,0) [0|1] "" RadioLow,TCP,CSM,CSM_AV,VCU
 SG_ TDRCADD_WOTEvnts : 8|1@0+ (1,0) [0|1] "" RadioLow,TCP,CSM,CSM_AV,VCU
 SG_ TDRCADD_UnbckldDistDrvn : 9|1@0+ (1,0) [0|1] "" RadioLow,TCP,CSM,CSM_AV,VCU
 SG_ TDRCADD_TrCtrlEvnts : 10|1@0+ (1,0) [0|1] "" RadioLow,TCP,CSM,CSM_AV,VCU
 SG_ TDRCADD_StCtrlEvnts : 11|1@0+ (1,0) [0|1] "" RadioLow,TCP,CSM,CSM_AV,VCU
 SG_ TDRCADD_RCMBrEvts : 12|1@0+ (1,0) [0|1] "" RadioLow,TCP,CSM,CSM_AV,VCU
 SG_ TDRCADD_OvrSpdDistDrvn : 13|1@0+ (1,0) [0|1] "" RadioLow,TCP,CSM,CSM_AV,VCU
 SG_ TDRCADD_OvSpdEvnt : 14|1@0+ (1,0) [0|1] "" RadioLow,TCP,CSM,CSM_AV,VCU
 SG_ TDRCADD_MaxSpd : 15|1@0+ (1,0) [0|1] "" RadioLow,TCP,CSM,CSM_AV,VCU
 SG_ RemCtrlFobNumForProg : 18|4@0+ (1,0) [0|15] "" CSM,CSM_AV,IPC,IPC_INT,VCU
 SG_ LstKyFbFnctnReq : 23|5@0+ (1,0) [0|30] "" RadioLow,CSM,CSM_AV,VCU
 SG_ SnrfPstnSts : 26|3@0+ (1,0) [0|4] "" AMP,TCP,VKM
 SG_ TeenDrvRsp : 30|4@0+ (1,0) [0|9] "" RadioLow,TCP,CSM,CSM_AV,VCU
 SG_ NghtSchmAtv : 32|1@0+ (1,0) [0|1] "" FPI,MFC,RSI,RadioLow,TCP,CSM,CSM_AV,IPC,IPC_INT,VCU
 SG_ TireLkDtnEnblSts : 34|2@0+ (1,0) [0|2] "" TCP,VCU
 SG_ RrClsrLckSts : 36|2@0+ (1,0) [0|2] "" TCP
 SG_ StrtModeElecSeltnIndReq : 39|3@0+ (1,0) [0|4] "" IPC,IPC_INT,VCU
 SG_ RrDrUnlckIO : 40|1@0+ (1,0) [0|1] "" IPC,IPC_INT,VCU
 SG_ RnSnsOffIO : 41|1@0+ (1,0) [0|1] "" CSM,CSM_AV,IPC,IPC_INT,VCU
 SG_ RnSnsActIO : 42|1@0+ (1,0) [0|1] "" CSM,CSM_AV,IPC,IPC_INT,VCU
 SG_ RmtPRNDLDispFltIndOn : 43|1@0+ (1,0) [0|1] "" IPC,IPC_INT,VCU
 SG_ RmtCtlFobBatLoIndOn : 44|1@0+ (1,0) [0|1] "" VKM,IPC,IPC_INT,VCU
 SG_ PwrLftgtUnvIndOn : 45|1@0+ (1,0) [0|1] "" IPC,IPC_INT,VCU
 SG_ PwrLftgtOffIndOn : 46|1@0+ (1,0) [0|1] "" IPC,IPC_INT,VCU
 SG_ PrkLmpIO : 47|1@0+ (1,0) [0|1] "" CSM,CSM_AV,IPC,IPC_INT,VCU
 SG_ ShftrLckdBcklDrvrStBltIndOn : 48|1@0+ (1,0) [0|1] "" IPC,IPC_INT,VCU
 SG_ ServPwrLftgtIndOn : 49|1@0+ (1,0) [0|1] "" IPC,IPC_INT,VCU
 SG_ ServKylsStSysIO : 50|1@0+ (1,0) [0|1] "" TCP,IPC,IPC_INT,VCU
 SG_ ServHtdStrgWhlIndOn : 51|1@0+ (1,0) [0|1] "" IPC,IPC_INT,VCU
 SG_ ServHdlmpsIndOn : 52|1@0+ (1,0) [0|1] "" IPC,IPC_INT,VCU
 SG_ ServDrLtchSysIO : 53|1@0+ (1,0) [0|1] "" IPC,IPC_INT,VCU
 SG_ RrStRmndrIndOn : 54|1@0+ (1,0) [0|1] "" IPC,IPC_INT,VCU
 SG_ RrSnshdNormzRqrdIO : 55|1@0+ (1,0) [0|1] "" IPC,IPC_INT,VCU
 SG_ MechShftrLckdHldBrkToOvrrdIndOn : 56|1@0+ (1,0) [0|1] "" IPC,IPC_INT,VCU
 SG_ HdOpnShftrLckdOvrrdCmpltIndOn : 57|1@0+ (1,0) [0|1] "" IPC,IPC_INT,VCU
 SG_ TeenDrvFtrAvl : 59|1@0+ (1,0) [0|1] "" RadioLow,TCP,CSM,CSM_AV,VCU
 SG_ StNtLtchdThrdRowIO : 60|1@0+ (1,0) [0|1] "" IPC,IPC_INT,VCU
 SG_ SnrfNormzRqrdIO : 61|1@0+ (1,0) [0|1] "" TCP,IPC,IPC_INT,VCU
 SG_ ShftrUnlckdBrktoShfIndOn : 62|1@0+ (1,0) [0|1] "" IPC,IPC_INT,VCU
 SG_ ShftrLckdBcklPsngrStBltIndOn : 63|1@0+ (1,0) [0|1] "" IPC,IPC_INT,VCU

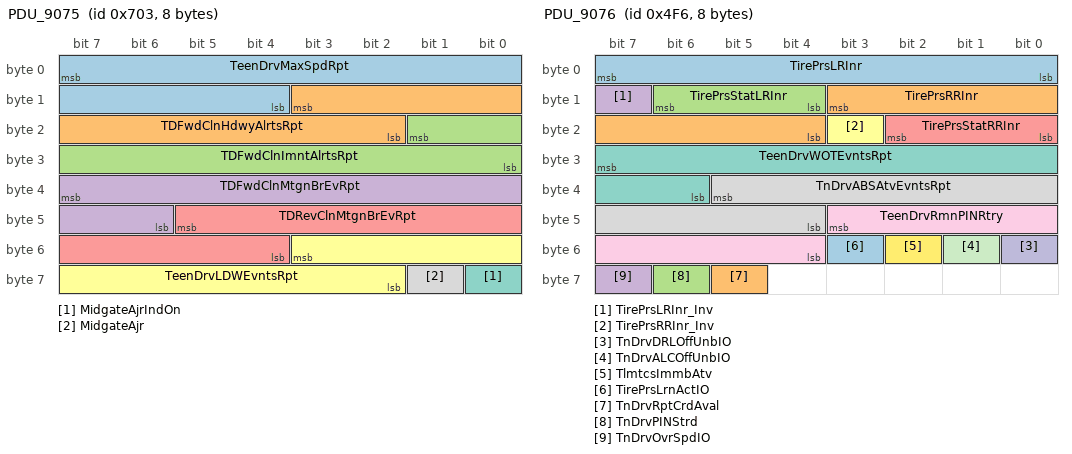
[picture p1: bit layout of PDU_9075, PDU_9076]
BO_ 1795 PDU_9075: 8 CGM
 SG_ TeenDrvMaxSpdRpt : 7|12@0+ (0.0625,0) [0|255.938] "km/h" RadioLow,TCP,CSM,CSM_AV,VCU
 SG_ TDFwdClnHdwyAlrtsRpt : 11|10@0+ (1,0) [0|1023] "Counts" RadioLow,TCP,CSM,CSM_AV,VCU
 SG_ TDFwdClnImntAlrtsRpt : 17|10@0+ (1,0) [0|1023] "Counts" RadioLow,TCP,CSM,CSM_AV,VCU
 SG_ TDFwdClnMtgnBrEvRpt : 39|10@0+ (1,0) [0|1023] "Counts" RadioLow,TCP,CSM,CSM_AV,VCU
 SG_ TDRevClnMtgnBrEvRpt : 45|10@0+ (1,0) [0|1023] "Counts" RadioLow,TCP,CSM,CSM_AV,VCU
 SG_ TeenDrvLDWEvntsRpt : 51|10@0+ (1,0) [0|1023] "Counts" RadioLow,TCP,CSM,CSM_AV,VCU
 SG_ MidgateAjrIndOn : 56|1@0+ (1,0) [0|1] "" IPC,IPC_INT,VCU
 SG_ MidgateAjr : 57|1@0+ (1,0) [0|1] "" IPC,IPC_INT,VCU

BO_ 1270 PDU_9076: 8 CGM
 SG_ TirePrsLRInr : 7|8@0+ (4,0) [0|1020] "kPaG" TCP,CSM,CSM_AV,IPC,IPC_INT,VCU
 SG_ TirePrsRRInr : 11|8@0+ (4,0) [0|1020] "kPaG" TCP,CSM,CSM_AV,IPC,IPC_INT,VCU
 SG_ TirePrsStatLRInr : 14|3@0+ (1,0) [0|5] "" TCP,CSM,CSM_AV,IPC,IPC_INT,VCU
 SG_ TirePrsLRInr_Inv : 15|1@0+ (1,0) [0|1] "" TCP,CSM,CSM_AV,IPC,IPC_INT,VCU
 SG_ TirePrsStatRRInr : 18|3@0+ (1,0) [0|5] "" TCP,CSM,CSM_AV,IPC,IPC_INT,VCU
 SG_ TirePrsRRInr_Inv : 19|1@0+ (1,0) [0|1] "" TCP,CSM,CSM_AV,IPC,IPC_INT,VCU
 SG_ TeenDrvWOTEvntsRpt : 31|10@0+ (1,0) [0|1023] "Counts" RadioLow,TCP,CSM,CSM_AV,VCU
 SG_ TnDrvABSAtvEvntsRpt : 37|10@0+ (1,0) [0|1023] "Counts" RadioLow,TCP,CSM,CSM_AV,VCU
 SG_ TeenDrvRmnPINRtry : 43|8@0+ (1,0) [0|255] "msec" RadioLow,CSM,CSM_AV,VCU
 SG_ TnDrvDRLOffUnbIO : 48|1@0+ (1,0) [0|1] "" TCP,IPC,IPC_INT,VCU
 SG_ TnDrvALCOffUnbIO : 49|1@0+ (1,0) [0|1] "" TCP,IPC,IPC_INT,VCU
 SG_ TlmtcsImmbAtv : 50|1@0+ (1,0) [0|1] "" TCP
 SG_ TirePrsLrnActIO : 51|1@0+ (1,0) [0|1] "" CSM,CSM_AV,IPC,IPC_INT,VCU
 SG_ TnDrvRptCrdAval : 61|1@0+ (1,0) [0|1] "" RadioLow,CSM,CSM_AV,VCU
 SG_ TnDrvPINStrd : 62|1@0+ (1,0) [0|1] "" RadioLow,TCP,CSM,CSM_AV,VCU
 SG_ TnDrvOvrSpdIO : 63|1@0+ (1,0) [0|1] "" TCP,IPC,IPC_INT,VCU

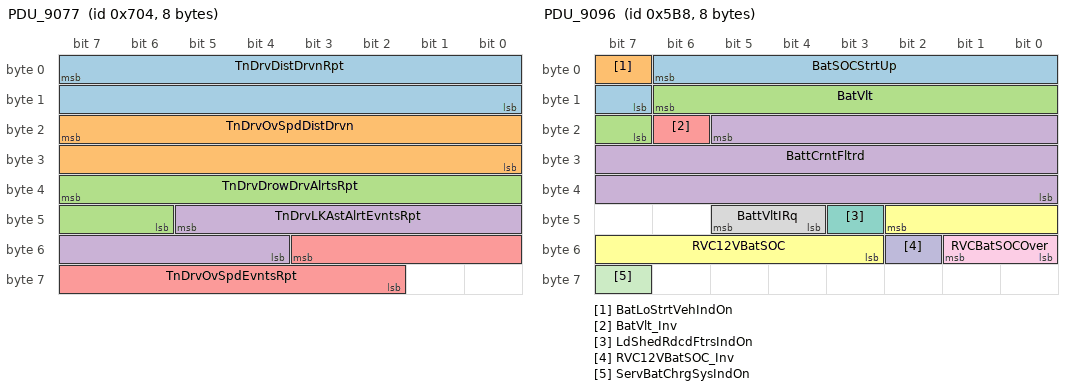
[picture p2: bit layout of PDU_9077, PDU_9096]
BO_ 1796 PDU_9077: 8 CGM
 SG_ TnDrvDistDrvnRpt : 7|16@0+ (1,0) [0|65535] "km" RadioLow,TCP,CSM,CSM_AV,VCU
 SG_ TnDrvOvSpdDistDrvn : 23|16@0+ (1,0) [0|65535] "km" RadioLow,TCP,CSM,CSM_AV,VCU
 SG_ TnDrvDrowDrvAlrtsRpt : 39|10@0+ (1,0) [0|1023] "Counts" RadioLow,TCP,CSM,CSM_AV,VCU
 SG_ TnDrvLKAstAlrtEvntsRpt : 45|10@0+ (1,0) [0|1023] "" RadioLow,TCP,CSM,CSM_AV,VCU
 SG_ TnDrvOvSpdEvntsRpt : 51|10@0+ (1,0) [0|1023] "Counts" RadioLow,TCP,CSM,CSM_AV,VCU

BO_ 1269 PDU_9078: 8 CGM
 SG_ TnDrvUnbckldDistDrvn : 7|16@0+ (1,0) [0|65535] "km" RadioLow,TCP,CSM,CSM_AV,VCU
 SG_ TnDrvStblCtrlEvntsRpt : 23|10@0+ (1,0) [0|1023] "Counts" RadioLow,TCP,CSM,CSM_AV,VCU
 SG_ TnDrvTrCtrlEvntsRpt : 29|10@0+ (1,0) [0|1023] "Counts" RadioLow,TCP,CSM,CSM_AV,VCU
 SG_ ValetMdResponse : 32|2@0+ (1,0) [0|3] "" RadioLow,TCP,CSM,CSM_AV,VCU
 SG_ VTDDrvIndReq : 35|3@0+ (1,0) [0|6] "" IPC,IPC_INT,VCU
 SG_ TrnspModeActvIndOn : 40|1@0+ (1,0) [0|1] "" IPC,IPC_INT,VCU
 SG_ TrlrLtngSeqStat : 41|1@0+ (1,0) [0|1] "" RadioLow,TCP,CSM,CSM_AV,VCU
 SG_ TrPrsMntrSysFld : 42|1@0+ (1,0) [0|1] "" RadioLow,CSM,CSM_AV,IPC,IPC_INT,VCU
 SG_ TPMTrLrnMdCmplt : 43|1@0+ (1,0) [0|1] "" RadioLow,CSM,CSM_AV,IPC,IPC_INT,VCU
 SG_ TrPrsMntrTrLdStat : 45|2@0+ (1,0) [0|3] "" RadioLow,CSM,CSM_AV,IPC,IPC_INT,VCU
 SG_ ValetModeActive : 46|1@0+ (1,0) [0|1] "" PDR,RadioLow,TCP,CSM,CSM_AV,IPC,IPC_INT,VCU
 SG_ WndNormzRF : 48|1@0+ (1,0) [0|1] "" CSM,CSM_AV,VCU
 SG_ WndNormzLR : 49|1@0+ (1,0) [0|1] "" CSM,CSM_AV,VCU
 SG_ WndNormzLF : 50|1@0+ (1,0) [0|1] "" CSM,CSM_AV,VCU
 SG_ VTDDrvMsgIO : 51|1@0+ (1,0) [0|1] "" IPC,IPC_INT,VCU
 SG_ TxLrnFldIO : 52|1@0+ (1,0) [0|1] "" IPC,IPC_INT,VCU
 SG_ TxBkUpLctIO : 53|1@0+ (1,0) [0|1] "" IPC,IPC_INT,VCU
 SG_ TurnWprIntIO : 54|1@0+ (1,0) [0|1] "" CSM,CSM_AV,IPC,IPC_INT,VCU
 SG_ TrnspModeInactiveIndOn : 55|1@0+ (1,0) [0|1] "" IPC,IPC_INT,VCU
 SG_ InfoAnm1Req : 57|2@0+ (1,0) [0|2] "" VCU
 SG_ BlkhdDrAjr : 58|1@0+ (1,0) [0|1] "" IPC,IPC_INT,VCU
 SG_ WndNtNrmzdIORR : 59|1@0+ (1,0) [0|1] "" IPC,IPC_INT,VCU
 SG_ WndNtNrmzdIOLR : 60|1@0+ (1,0) [0|1] "" IPC,IPC_INT,VCU
 SG_ WndNtNrmzdIODrv : 61|1@0+ (1,0) [0|1] "" IPC,IPC_INT,VCU
 SG_ WndNtNrmzdIOCoDrv : 62|1@0+ (1,0) [0|1] "" IPC,IPC_INT,VCU
 SG_ WndNormzRR : 63|1@0+ (1,0) [0|1] "" CSM,CSM_AV,VCU

BO_ 1492 PDU_9079: 8 CGM
 SG_ ACCCSV_Aux1Colr : 0|7@0+ (1,0) [0|127] "" RadioLow,CSM,CSM_AV,VCU
 SG_ ACCCSV_Aux1Brghtns : 3|3@0+ (1,0) [0|7] "" RadioLow,CSM,CSM_AV,VCU
 SG_ ACCCSV_Aux1Anm : 7|4@0+ (1,0) [0|15] "" RadioLow,CSM,CSM_AV,VCU
 SG_ ACCCSV_IntrAnm : 9|4@0+ (1,0) [0|15] "" RadioLow,CSM,CSM_AV,VCU
 SG_ ACCCSV_IntrColr : 18|7@0+ (1,0) [0|127] "" RadioLow,CSM,CSM_AV,VCU
 SG_ ACCCSV_IntrBrghtns : 21|3@0+ (1,0) [0|7] "" RadioLow,CSM,CSM_AV,VCU
 SG_ AutDrvLckCstCurSetVal : 24|3@0+ (1,0) [0|7] "" RadioLow,CSM,CSM_AV,VCU
 SG_ AirQltySnsCstCrStVal : 27|3@0+ (1,0) [0|7] "" RadioLow,CSM,CSM_AV,VCU
 SG_ AutoAirDstCstCrStVal : 34|3@0+ (1,0) [0|7] "" RadioLow,CSM,CSM_AV,VCU
 SG_ AutMirFldCstCurSetVal : 37|3@0+ (1,0) [0|7] "" RadioLow,CSM,CSM_AV,VCU
 SG_ AutoFanCstCrStVal : 41|3@0+ (1,0) [0|7] "" RadioLow,CSM,CSM_AV,VCU
 SG_ AutoDfgCstCrStVal : 44|3@0+ (1,0) [0|7] "" RadioLow,CSM,CSM_AV,VCU
 SG_ AutoCoolStCstCrStVal : 47|3@0+ (1,0) [0|7] "" RadioLow,CSM,CSM_AV,VCU
 SG_ AirQltySnsCstStAvl : 48|1@0+ (1,0) [0|1] "" RadioLow,CSM,CSM_AV,VCU
 SG_ AutoRrWpCstCurSetVal : 51|3@0+ (1,0) [0|7] "" RadioLow,CSM,CSM_AV,VCU
 SG_ AutoHtdStCstCrStVal : 54|3@0+ (1,0) [0|7] "" RadioLow,CSM,CSM_AV,VCU
 SG_ AutoRrWpCstStAvl : 56|1@0+ (1,0) [0|1] "" RadioLow,CSM,CSM_AV,VCU
 SG_ AutoHtdStCstStAvl : 57|1@0+ (1,0) [0|1] "" RadioLow,CSM,CSM_AV,VCU
 SG_ AutoFanCstStAvl : 58|1@0+ (1,0) [0|1] "" RadioLow,CSM,CSM_AV,VCU
 SG_ AutoDfgCstStAvl : 59|1@0+ (1,0) [0|1] "" RadioLow,CSM,CSM_AV,VCU
 SG_ AutoCoolStCstStAvl : 60|1@0+ (1,0) [0|1] "" RadioLow,CSM,CSM_AV,VCU
 SG_ AutoAirDstCstStAvl : 61|1@0+ (1,0) [0|1] "" RadioLow,CSM,CSM_AV,VCU
 SG_ AutMirFldCstStAvl : 62|1@0+ (1,0) [0|1] "" RadioLow,CSM,CSM_AV,VCU
 SG_ AutDrvLckCstStAvl : 63|1@0+ (1,0) [0|1] "" RadioLow,CSM,CSM_AV,VCU

BO_ 1493 PDU_9080: 8 CGM
 SG_ RmtReFlshElecPwrRdnes : 7|8@0+ (0.025,0) [0|6.375] "AmpHr" RadioLow,TCP,CSM,CSM_AV,VCU
 SG_ PlltnCtrlCstCrStVal : 9|3@0+ (1,0) [0|7] "" RadioLow,CSM,CSM_AV,VCU
 SG_ OpDrAtLOCstCurSetVal : 12|3@0+ (1,0) [0|7] "" RadioLow,CSM,CSM_AV,VCU
 SG_ LDCLCstCurSetVal : 15|3@0+ (1,0) [0|7] "" RadioLow,CSM,CSM_AV,VCU
 SG_ RemLftVehRmndrCstCurSetVal : 16|3@0+ (1,0) [0|7] "" RadioLow,CSM,CSM_AV,VCU
 SG_ RemInVehRmndrCstCurSetVal : 19|3@0+ (1,0) [0|7] "" RadioLow,CSM,CSM_AV,VCU
 SG_ PsvUnlckCstCurSetVal : 22|3@0+ (1,0) [0|7] "" RadioLow,CSM,CSM_AV,VCU
 SG_ RlkRtUlkDrCstCrSetVal : 26|3@0+ (1,0) [0|7] "" RadioLow,CSM,CSM_AV,VCU
 SG_ RevTltMirCstCurSetVal : 29|3@0+ (1,0) [0|7] "" RadioLow,CSM,CSM_AV,VCU
 SG_ RmtStrtHtdStCstCrStVal : 33|3@0+ (1,0) [0|7] "" RadioLow,CSM,CSM_AV,VCU
 SG_ RmtStrtCoolStCstCrStVal : 36|3@0+ (1,0) [0|7] "" RadioLow,CSM,CSM_AV,VCU
 SG_ RmtSnrfOpCstCurrSetVal : 39|3@0+ (1,0) [0|7] "" RadioLow,VKM,CSM,CSM_AV,VCU
 SG_ RrAirHandlingDrActrPwrReq : 40|2@0+ (1,0) [0|2] "" HVAC_FP_R,VCU
 SG_ RnSnsCstCurSetVal : 43|3@0+ (1,0) [0|7] "" RadioLow,CSM,CSM_AV,VCU
 SG_ RmtWndOpCstCurSetVal : 46|3@0+ (1,0) [0|7] "" RadioLow,VKM,CSM,CSM_AV,VCU
 SG_ RevTltMirCstStAvl : 48|1@0+ (1,0) [0|1] "" RadioLow,CSM,CSM_AV,VCU
 SG_ RemLftVehRmndrCstStAvl : 49|1@0+ (1,0) [0|1] "" RadioLow,CSM,CSM_AV,VCU
 SG_ RemInVehRmndrCstStAvl : 50|1@0+ (1,0) [0|1] "" RadioLow,CSM,CSM_AV,VCU
 SG_ PsvUnlckCstStAvl : 51|1@0+ (1,0) [0|1] "" RadioLow,CSM,CSM_AV,VCU
 SG_ PlltnCtrlCstStAvl : 52|1@0+ (1,0) [0|1] "" RadioLow,CSM,CSM_AV,VCU
 SG_ OpDrAtLOCstStAvl : 53|1@0+ (1,0) [0|1] "" RadioLow,CSM,CSM_AV,VCU
 SG_ LDCLCstStAvl : 54|1@0+ (1,0) [0|1] "" RadioLow,CSM,CSM_AV,VCU
 SG_ RnSnsCstStAvl : 58|1@0+ (1,0) [0|1] "" RadioLow,CSM,CSM_AV,VCU
 SG_ RmtWndOpCstStAvl : 59|1@0+ (1,0) [0|1] "" RadioLow,CSM,CSM_AV,VCU
 SG_ RmtStrtHtdStCstStAvl : 60|1@0+ (1,0) [0|1] "" RadioLow,CSM,CSM_AV,VCU
 SG_ RmtStrtCoolStCstStAvl : 61|1@0+ (1,0) [0|1] "" RadioLow,CSM,CSM_AV,VCU
 SG_ RmtSnrfOpCstSetAval : 62|1@0+ (1,0) [0|1] "" RadioLow,CSM,CSM_AV,VCU
 SG_ RlkRtUlkDrCstStAvl : 63|1@0+ (1,0) [0|1] "" RadioLow,CSM,CSM_AV,VCU

BO_ 1494 PDU_9081: 8 CGM
 SG_ TDOSWCCSV_DspVal : 4|12@0+ (0.0625,0) [0|255.938] "km/h" RadioLow,TCP,CSM,CSM_AV,VCU
 SG_ TDOSWCCSV_CrSetVal : 7|3@0+ (1,0) [0|7] "" RadioLow,TCP,CSM,CSM_AV,IPC,IPC_INT,VCU
 SG_ TDSLCCSV_CrSetVal : 8|3@0+ (1,0) [0|7] "" RadioLow,TCP,CSM,CSM_AV,VCU
 SG_ TDSLCCSV_DspVal : 21|8@0+ (2,0) [0|510] "km/h" RadioLow,TCP,CSM,CSM_AV,VCU
 SG_ RrStRmndrEnblDsblCstCurrSetVal : 26|3@0+ (1,0) [0|7] "" RadioLow,CSM,CSM_AV,VCU
 SG_ RrDfgStUpCstCrStVal : 29|3@0+ (1,0) [0|7] "" RadioLow,CSM,CSM_AV,VCU
 SG_ RtUlkLtFbCstCurSetVal : 33|3@0+ (1,0) [0|7] "" RadioLow,CSM,CSM_AV,VCU
 SG_ RtLkFdbkCstCurSetVal : 36|3@0+ (1,0) [0|7] "" RadioLow,CSM,CSM_AV,VCU
 SG_ RrZnStUpCstCrStVal : 39|3@0+ (1,0) [0|7] "" RadioLow,CSM,CSM_AV,VCU
 SG_ WlkAwyLckCstCurSetVal : 40|3@0+ (1,0) [0|7] "" RadioLow,CSM,CSM_AV,VCU
 SG_ VehLctrLghtsCstCurSetVal : 43|3@0+ (1,0) [0|7] "" RadioLow,CSM,CSM_AV,VCU
 SG_ SelUlkCstCurSetVal : 46|3@0+ (1,0) [0|7] "" RadioLow,VKM,CSM,CSM_AV,VCU
 SG_ SelUlkCstStAvl : 48|1@0+ (1,0) [0|1] "" RadioLow,CSM,CSM_AV,VCU
 SG_ RtUlkLtFbCstStAvl : 49|1@0+ (1,0) [0|1] "" RadioLow,CSM,CSM_AV,VCU
 SG_ RtLkFdbkCstStAvl : 50|1@0+ (1,0) [0|1] "" RadioLow,CSM,CSM_AV,VCU
 SG_ RrZnStUpCstStAvl : 51|1@0+ (1,0) [0|1] "" RadioLow,CSM,CSM_AV,VCU
 SG_ RrStRmndrEnblDsblCstSetAval : 52|1@0+ (1,0) [0|1] "" RadioLow,CSM,CSM_AV,VCU
 SG_ RrDfgStUpCstStAvl : 53|1@0+ (1,0) [0|1] "" RadioLow,CSM,CSM_AV,VCU
 SG_ WlkAwyLckCstStAvl : 60|1@0+ (1,0) [0|1] "" RadioLow,CSM,CSM_AV,VCU
 SG_ VehLctrLghtsCstStAvl : 61|1@0+ (1,0) [0|1] "" RadioLow,CSM,CSM_AV,VCU
 SG_ TnDrvSpdLmtCstStAvl : 62|1@0+ (1,0) [0|1] "" RadioLow,TCP,CSM,CSM_AV,VCU
 SG_ TnDrvOvSpdWrnCstStAvl : 63|1@0+ (1,0) [0|1] "" RadioLow,TCP,CSM,CSM_AV,VCU

BO_ 1495 PDU_9082: 8 CGM
 SG_ IHVSLF_HtdCushBckLvl2 : 0|1@0+ (1,0) [0|1] "" HVAC_FP_F,IPC,IPC_INT,VCU
 SG_ IHVSLF_HtdCushBckLvl1 : 1|1@0+ (1,0) [0|1] "" HVAC_FP_F,IPC,IPC_INT,VCU
 SG_ IHVSLF_HtdCushBckAuto : 2|1@0+ (1,0) [0|1] "" HVAC_FP_F,IPC,IPC_INT,VCU
 SG_ IHVSLF_HtdBckMd : 3|1@0+ (1,0) [0|1] "" HVAC_FP_F,IPC,IPC_INT,VCU
 SG_ IHVSLF_HtdBckLvl3 : 4|1@0+ (1,0) [0|1] "" HVAC_FP_F,IPC,IPC_INT,VCU
 SG_ IHVSLF_HtdBckLvl2 : 5|1@0+ (1,0) [0|1] "" HVAC_FP_F,IPC,IPC_INT,VCU
 SG_ IHVSLF_HtdBckLvl1 : 6|1@0+ (1,0) [0|1] "" HVAC_FP_F,IPC,IPC_INT,VCU
 SG_ IHVSLF_HtdBckAuto : 7|1@0+ (1,0) [0|1] "" HVAC_FP_F,IPC,IPC_INT,VCU
 SG_ IHVSRF_HtdBckAuto : 8|1@0+ (1,0) [0|1] "" HVAC_FP_F,IPC,IPC_INT,VCU
 SG_ IHVSLF_VntMd : 9|1@0+ (1,0) [0|1] "" HVAC_FP_F,IPC,IPC_INT,VCU
 SG_ IHVSLF_VntLvl3 : 10|1@0+ (1,0) [0|1] "" HVAC_FP_F,IPC,IPC_INT,VCU
 SG_ IHVSLF_VntLvl2 : 11|1@0+ (1,0) [0|1] "" HVAC_FP_F,IPC,IPC_INT,VCU
 SG_ IHVSLF_VntLvl1 : 12|1@0+ (1,0) [0|1] "" HVAC_FP_F,IPC,IPC_INT,VCU
 SG_ IHVSLF_VntAuto : 13|1@0+ (1,0) [0|1] "" HVAC_FP_F,IPC,IPC_INT,VCU
 SG_ IHVSLF_HtdCushBckMd : 14|1@0+ (1,0) [0|1] "" HVAC_FP_F,IPC,IPC_INT,VCU
 SG_ IHVSLF_HtdCushBckLvl3 : 15|1@0+ (1,0) [0|1] "" HVAC_FP_F,IPC,IPC_INT,VCU
 SG_ IHVSRF_HtdCushBckLvl3 : 16|1@0+ (1,0) [0|1] "" HVAC_FP_F,IPC,IPC_INT,VCU
 SG_ IHVSRF_HtdCushBckLvl2 : 17|1@0+ (1,0) [0|1] "" HVAC_FP_F,IPC,IPC_INT,VCU
 SG_ IHVSRF_HtdCushBckLvl1 : 18|1@0+ (1,0) [0|1] "" HVAC_FP_F,IPC,IPC_INT,VCU
 SG_ IHVSRF_HtdCushBckAuto : 19|1@0+ (1,0) [0|1] "" HVAC_FP_F,IPC,IPC_INT,VCU
 SG_ IHVSRF_HtdBckMd : 20|1@0+ (1,0) [0|1] "" HVAC_FP_F,IPC,IPC_INT,VCU
 SG_ IHVSRF_HtdBckLvl3 : 21|1@0+ (1,0) [0|1] "" HVAC_FP_F,IPC,IPC_INT,VCU
 SG_ IHVSRF_HtdBckLvl2 : 22|1@0+ (1,0) [0|1] "" HVAC_FP_F,IPC,IPC_INT,VCU
 SG_ IHVSRF_HtdBckLvl1 : 23|1@0+ (1,0) [0|1] "" HVAC_FP_F,IPC,IPC_INT,VCU
 SG_ IntDimSeldClrTypStVal : 25|5@0+ (1,0) [0|31] "" RadioLow,CSM,CSM_AV,VCU
 SG_ IHVSRF_VntMd : 26|1@0+ (1,0) [0|1] "" HVAC_FP_F,IPC,IPC_INT,VCU
 SG_ IHVSRF_VntLvl3 : 27|1@0+ (1,0) [0|1] "" HVAC_FP_F,IPC,IPC_INT,VCU
 SG_ IHVSRF_VntLvl2 : 28|1@0+ (1,0) [0|1] "" HVAC_FP_F,IPC,IPC_INT,VCU
 SG_ IHVSRF_VntLvl1 : 29|1@0+ (1,0) [0|1] "" HVAC_FP_F,IPC,IPC_INT,VCU
 SG_ IHVSRF_VntAuto : 30|1@0+ (1,0) [0|1] "" HVAC_FP_F,IPC,IPC_INT,VCU
 SG_ IHVSRF_HtdCushBckMd : 31|1@0+ (1,0) [0|1] "" HVAC_FP_F,IPC,IPC_INT,VCU
 SG_ AutUnlckCstCurSetVal : 32|3@0+ (1,0) [0|7] "" RadioLow,CSM,CSM_AV,VCU
 SG_ IntDimSeldAnmTypStVal : 36|4@0+ (1,0) [0|15] "" RadioLow,CSM,CSM_AV,VCU
 SG_ ExtLghtCstCurSetVal : 42|3@0+ (1,0) [0|7] "" RadioLow,CSM,CSM_AV,VCU
 SG_ DaytimeTlLghtsCstCurSetVal : 45|3@0+ (1,0) [0|7] "" RadioLow,CSM,CSM_AV,VCU
 SG_ CurbVwFtrActvReq : 49|2@0+ (1,0) [0|2] "" CSM,CSM_AV,VCU
 SG_ IonzrCtrlCstCrStVal : 52|3@0+ (1,0) [0|7] "" RadioLow,CSM,CSM_AV,VCU
 SG_ HFRCCstCurSetVal : 55|3@0+ (1,0) [0|7] "" RadioLow,CSM,CSM_AV,VCU
 SG_ IonzrCtrlCstStAvl : 58|1@0+ (1,0) [0|1] "" RadioLow,CSM,CSM_AV,VCU
 SG_ HFRCCstStAvl : 59|1@0+ (1,0) [0|1] "" RadioLow,CSM,CSM_AV,VCU
 SG_ ExtLghtCstStAvl : 60|1@0+ (1,0) [0|1] "" RadioLow,CSM,CSM_AV,VCU
 SG_ DaytimeTlLghtsCstStAvl : 61|1@0+ (1,0) [0|1] "" RadioLow,CSM,CSM_AV,VCU
 SG_ CrsCntCncRq : 62|1@0+ (1,0) [0|1] "" CSM,CSM_AV,VCU
 SG_ AutUnlckCstStAvl : 63|1@0+ (1,0) [0|1] "" RadioLow,CSM,CSM_AV,VCU

BO_ 1177 PDU_9090: 8 CGM
 SG_ PCOSN_NtfnEvntSyncCnt : 5|8@0+ (1,0) [0|255] "" TCP
 SG_ PCOSN_NtfnDrvrStBltSts : 7|2@0+ (1,0) [0|3] "" TCP
 SG_ PCOSN_NtfnImpDeltVelTxSts : 8|2@0+ (1,0) [0|2] "" TCP
 SG_ PCOSN_NtfnFrstPsngrStOccpSts : 11|3@0+ (1,0) [0|3] "" TCP
 SG_ PCOSN_NtfnFrstPsngrStBltSts : 13|2@0+ (1,0) [0|3] "" TCP
 SG_ PCOSN_NtfnImpMaxLatDeltVel : 22|8@0- (1,0) [-128|127] "kph" TCP
 SG_ PCOSN_NtfnImpMaxLongDeltVel : 30|8@0- (1,0) [-128|127] "kph" TCP
 SG_ PCOSN_NtfnSecRowLtStOccpSts : 32|2@0+ (1,0) [0|3] "" TCP
 SG_ PCOSN_NtfnSecRowLtStBltSts : 34|2@0+ (1,0) [0|3] "" TCP
 SG_ PCOSN_NtfnSecRowCntrStOccpSts : 36|2@0+ (1,0) [0|3] "" TCP
 SG_ PCOSN_NtfnSecRowCntrStBltSts : 38|2@0+ (1,0) [0|3] "" TCP
 SG_ PCOSN_NtfnThrdRowCntrStOccpSts : 40|2@0+ (1,0) [0|3] "" TCP
 SG_ PCOSN_NtfnThrdRowCntrStBltSts : 42|2@0+ (1,0) [0|3] "" TCP
 SG_ PCOSN_NtfnSecRowRtStOccpSts : 44|2@0+ (1,0) [0|3] "" TCP
 SG_ PCOSN_NtfnSecRowRtStBltSts : 46|2@0+ (1,0) [0|3] "" TCP
 SG_ PCOSN_NtfnThrdRowRtStOccpSts : 48|2@0+ (1,0) [0|3] "" TCP
 SG_ PCOSN_NtfnThrdRowRtStBltSts : 50|2@0+ (1,0) [0|3] "" TCP
 SG_ PCOSN_NtfnThrdRowLtStOccpSts : 52|2@0+ (1,0) [0|3] "" TCP
 SG_ PCOSN_NtfnThrdRowLtStBltSts : 54|2@0+ (1,0) [0|3] "" TCP
 SG_ PCOSN_NtfnFrstRowCntrStOccpSts : 58|2@0+ (1,0) [0|3] "" TCP
 SG_ PCOSN_NtfnFrstRowCntrStBtSts : 60|2@0+ (1,0) [0|3] "" TCP
 SG_ PCOSN_NtfnDrvrStOccpSts : 62|2@0+ (1,0) [0|3] "" TCP

BO_ 1500 PDU_9094: 8 CGM
 SG_ DM1Unavailable : 0|1@0+ (1,0) [0|1] "" CSM,CSM_AV,IPC,IPC_INT,VCU
 SG_ DM1Status : 1|1@0+ (1,0) [0|1] "" AMP,PDR,CSM,CSM_AV,IPC,IPC_INT,VCU
 SG_ DM1Pending : 2|1@0+ (1,0) [0|1] "" CSM,CSM_AV,IPC,IPC_INT,VCU
 SG_ DM1Name : 7|5@0+ (1,0) [0|25] "" AMP,PDR,CSM,CSM_AV,IPC,IPC_INT,VCU
 SG_ DM2Unavailable : 8|1@0+ (1,0) [0|1] "" CSM,CSM_AV,IPC,IPC_INT,VCU
 SG_ DM2Status : 9|1@0+ (1,0) [0|1] "" AMP,PDR,CSM,CSM_AV,IPC,IPC_INT,VCU
 SG_ DM2Pending : 10|1@0+ (1,0) [0|1] "" CSM,CSM_AV,IPC,IPC_INT,VCU
 SG_ DM2Name : 15|5@0+ (1,0) [0|25] "" AMP,PDR,CSM,CSM_AV,IPC,IPC_INT,VCU
 SG_ DM3Unavailable : 16|1@0+ (1,0) [0|1] "" CSM,CSM_AV,IPC,IPC_INT,VCU
 SG_ DM3Status : 17|1@0+ (1,0) [0|1] "" AMP,PDR,CSM,CSM_AV,IPC,IPC_INT,VCU
 SG_ DM3Pending : 18|1@0+ (1,0) [0|1] "" CSM,CSM_AV,IPC,IPC_INT,VCU
 SG_ DM3Name : 23|5@0+ (1,0) [0|25] "" AMP,PDR,CSM,CSM_AV,IPC,IPC_INT,VCU
 SG_ DM4Unavailable : 24|1@0+ (1,0) [0|1] "" CSM,CSM_AV,IPC,IPC_INT,VCU
 SG_ DM4Status : 25|1@0+ (1,0) [0|1] "" AMP,PDR,CSM,CSM_AV,IPC,IPC_INT,VCU
 SG_ DM4Pending : 26|1@0+ (1,0) [0|1] "" CSM,CSM_AV,IPC,IPC_INT,VCU
 SG_ DM4Name : 31|5@0+ (1,0) [0|25] "" AMP,PDR,CSM,CSM_AV,IPC,IPC_INT,VCU
 SG_ DM5Unavailable : 32|1@0+ (1,0) [0|1] "" CSM,CSM_AV,IPC,IPC_INT,VCU
 SG_ DM5Status : 33|1@0+ (1,0) [0|1] "" AMP,PDR,CSM,CSM_AV,IPC,IPC_INT,VCU
 SG_ DM5Pending : 34|1@0+ (1,0) [0|1] "" CSM,CSM_AV,IPC,IPC_INT,VCU
 SG_ DM5Name : 39|5@0+ (1,0) [0|25] "" AMP,PDR,CSM,CSM_AV,IPC,IPC_INT,VCU
 SG_ DM6Unavailable : 40|1@0+ (1,0) [0|1] "" CSM,CSM_AV,IPC,IPC_INT,VCU
 SG_ DM6Status : 41|1@0+ (1,0) [0|1] "" AMP,PDR,CSM,CSM_AV,IPC,IPC_INT,VCU
 SG_ DM6Pending : 42|1@0+ (1,0) [0|1] "" CSM,CSM_AV,IPC,IPC_INT,VCU
 SG_ DM6Name : 47|5@0+ (1,0) [0|25] "" AMP,PDR,CSM,CSM_AV,IPC,IPC_INT,VCU
 SG_ DM7Unavailable : 48|1@0+ (1,0) [0|1] "" CSM,CSM_AV,IPC,IPC_INT,VCU
 SG_ DM7Status : 49|1@0+ (1,0) [0|1] "" AMP,PDR,CSM,CSM_AV,IPC,IPC_INT,VCU
 SG_ DM7Pending : 50|1@0+ (1,0) [0|1] "" CSM,CSM_AV,IPC,IPC_INT,VCU
 SG_ DM7Name : 55|5@0+ (1,0) [0|25] "" AMP,PDR,CSM,CSM_AV,IPC,IPC_INT,VCU
 SG_ DM8Unavailable : 56|1@0+ (1,0) [0|1] "" CSM,CSM_AV,IPC,IPC_INT,VCU
 SG_ DM8Status : 57|1@0+ (1,0) [0|1] "" AMP,PDR,CSM,CSM_AV,IPC,IPC_INT,VCU
 SG_ DM8Pending : 58|1@0+ (1,0) [0|1] "" CSM,CSM_AV,IPC,IPC_INT,VCU
 SG_ DM8Name : 63|5@0+ (1,0) [0|25] "" AMP,PDR,CSM,CSM_AV,IPC,IPC_INT,VCU

BO_ 1464 PDU_9096: 8 CGM
 SG_ BatSOCStrtUp : 6|8@0+ (0.5,0) [0|127.5] "%" TCP,CSM,CSM_AV,VCU
 SG_ BatLoStrtVehIndOn : 7|1@0+ (1,0) [0|1] "" TCP,IPC,IPC_INT,VCU
 SG_ BatVlt : 14|8@0+ (0.1,3) [3|28.5] "volts" PDR,TCP,VKM,CSM,CSM_AV,IPC,IPC_INT,VCU
 SG_ BattCrntFltrd : 21|22@0- (0.001,0) [-2097.15|2097.15] "Amps" TCP,CSM,CSM_AV,VCU
 SG_ BatVlt_Inv : 22|1@0+ (1,0) [0|1] "" PDR,TCP,CSM,CSM_AV,IPC,IPC_INT,VCU
 SG_ RVC12VBatSOC : 42|8@0+ (0.5,0) [0|127.5] "%" TCP,VKM,CSM,CSM_AV,VCU
 SG_ LdShedRdcdFtrsIndOn : 43|1@0+ (1,0) [0|1] "" IPC,IPC_INT,VCU
 SG_ BattVltIRq : 45|2@0+ (1,0) [0|3] "" TCP,CSM,CSM_AV,IPC,IPC_INT,VCU
 SG_ RVCBatSOCOver : 49|2@0+ (1,0) [0|3] "" CSM,CSM_AV,VCU
 SG_ RVC12VBatSOC_Inv : 50|1@0+ (1,0) [0|1] "" TCP,CSM,CSM_AV,VCU
 SG_ ServBatChrgSysIndOn : 63|1@0+ (1,0) [0|1] "" TCP,IPC,IPC_INT,VCU

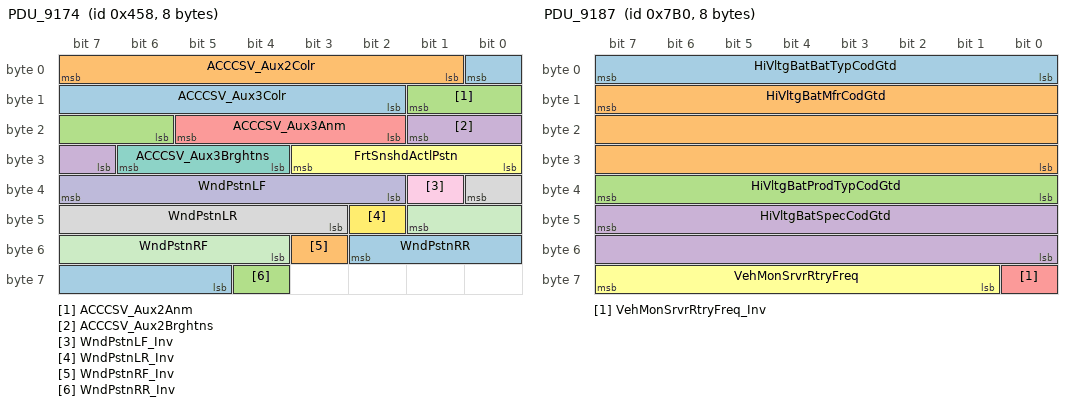
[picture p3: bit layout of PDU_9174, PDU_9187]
BO_ 1112 PDU_9174: 8 CGM
 SG_ ACCCSV_Aux3Colr : 0|7@0+ (1,0) [0|127] "" VCU
 SG_ ACCCSV_Aux2Colr : 7|7@0+ (1,0) [0|127] "" VCU
 SG_ ACCCSV_Aux2Anm : 9|4@0+ (1,0) [0|15] "" VCU
 SG_ ACCCSV_Aux2Brghtns : 17|3@0+ (1,0) [0|4] "" VCU
 SG_ ACCCSV_Aux3Anm : 21|4@0+ (1,0) [0|15] "" VCU
 SG_ FrtSnshdActlPstn : 27|4@0+ (1,0) [0|12] "" VCU
 SG_ ACCCSV_Aux3Brghtns : 30|3@0+ (1,0) [0|4] "" VCU
 SG_ WndPstnLR : 32|6@0+ (1.5873,0) [0|100] "%" VCU
 SG_ WndPstnLF_Inv : 33|1@0+ (1,0) [0|1] "" VCU
 SG_ WndPstnLF : 39|6@0+ (1.5873,0) [0|100] "%" VCU
 SG_ WndPstnRF : 41|6@0+ (1.5873,0) [0|100] "%" VCU
 SG_ WndPstnLR_Inv : 42|1@0+ (1,0) [0|1] "" VCU
 SG_ WndPstnRR : 50|6@0+ (1.5873,0) [0|100] "%" VCU
 SG_ WndPstnRF_Inv : 51|1@0+ (1,0) [0|1] "" VCU
 SG_ WndPstnRR_Inv : 60|1@0+ (1,0) [0|1] "" VCU

BO_ 1968 PDU_9187: 8 CGM
 SG_ HiVltgBatBatTypCodGtd : 7|8@0+ (1,0) [0|255] "" TCP
 SG_ HiVltgBatMfrCodGtd : 15|24@0+ (1,0) [0|16777215] "" TCP
 SG_ HiVltgBatProdTypCodGtd : 39|8@0+ (1,0) [0|255] "" TCP
 SG_ HiVltgBatSpecCodGtd : 47|16@0+ (1,0) [0|65535] "" TCP
 SG_ VehMonSrvrRtryFreq_Inv : 56|1@0+ (1,0) [0|1] "" TCP
 SG_ VehMonSrvrRtryFreq : 63|7@0+ (1,0) [0|127] "Seconds" TCP

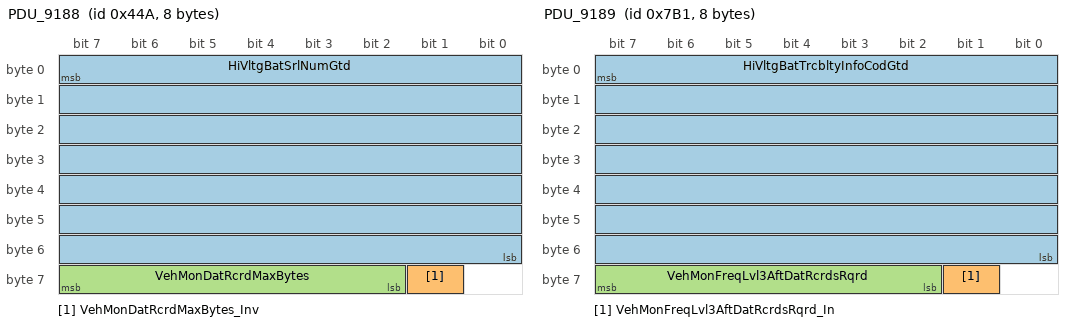
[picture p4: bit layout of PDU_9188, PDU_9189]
BO_ 1098 PDU_9188: 8 CGM
 SG_ HiVltgBatSrlNumGtd : 7|56@0+ (1,0) [0|7.205759403792794e+16] "" TCP
 SG_ VehMonDatRcrdMaxBytes_Inv : 57|1@0+ (1,0) [0|1] "" TCP
 SG_ VehMonDatRcrdMaxBytes : 63|6@0+ (50,0) [0|3150] "" TCP

BO_ 1969 PDU_9189: 8 CGM
 SG_ HiVltgBatTrcbltyInfoCodGtd : 7|56@0+ (1,0) [0|7.205759403792794e+16] "" TCP
 SG_ VehMonFreqLvl3AftDatRcrdsRqrd_In : 57|1@0+ (1,0) [0|1] "" TCP
 SG_ VehMonFreqLvl3AftDatRcrdsRqrd : 63|6@0+ (1,0) [0|63] "Seconds" TCP

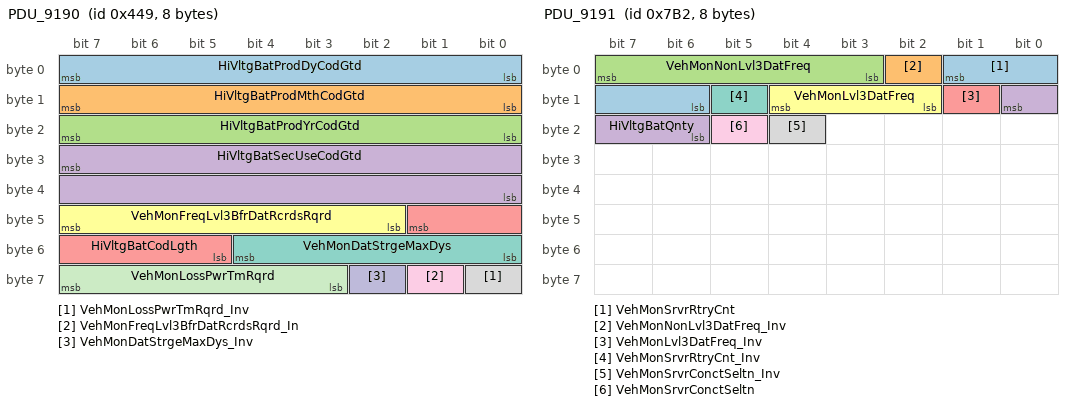
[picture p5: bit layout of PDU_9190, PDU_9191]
BO_ 1097 PDU_9190: 8 CGM
 SG_ HiVltgBatProdDyCodGtd : 7|8@0+ (1,0) [0|255] "" TCP
 SG_ HiVltgBatProdMthCodGtd : 15|8@0+ (1,0) [0|255] "" TCP
 SG_ HiVltgBatProdYrCodGtd : 23|8@0+ (1,0) [0|255] "" TCP
 SG_ HiVltgBatSecUseCodGtd : 31|16@0+ (1,0) [0|65535] "" TCP
 SG_ HiVltgBatCodLgth : 41|5@0+ (1,0) [0|31] "" TCP
 SG_ VehMonFreqLvl3BfrDatRcrdsRqrd : 47|6@0+ (1,0) [0|63] "Seconds" TCP
 SG_ VehMonDatStrgeMaxDys : 52|5@0+ (1,0) [0|31] "" TCP
 SG_ VehMonLossPwrTmRqrd_Inv : 56|1@0+ (1,0) [0|1] "" TCP
 SG_ VehMonFreqLvl3BfrDatRcrdsRqrd_In : 57|1@0+ (1,0) [0|1] "" TCP
 SG_ VehMonDatStrgeMaxDys_Inv : 58|1@0+ (1,0) [0|1] "" TCP
 SG_ VehMonLossPwrTmRqrd : 63|5@0+ (1,0) [0|31] "Minutes" TCP

BO_ 1970 PDU_9191: 8 CGM
 SG_ VehMonSrvrRtryCnt : 1|4@0+ (1,0) [0|15] "" TCP
 SG_ VehMonNonLvl3DatFreq_Inv : 2|1@0+ (1,0) [0|1] "" TCP
 SG_ VehMonNonLvl3DatFreq : 7|5@0+ (1,0) [0|31] "Seconds" TCP
 SG_ HiVltgBatQnty : 8|3@0+ (1,0) [0|7] "" TCP
 SG_ VehMonLvl3DatFreq_Inv : 9|1@0+ (1,0) [0|1] "" TCP
 SG_ VehMonLvl3DatFreq : 12|3@0+ (1,0) [0|7] "Seconds" TCP
 SG_ VehMonSrvrRtryCnt_Inv : 13|1@0+ (1,0) [0|1] "" TCP
 SG_ VehMonSrvrConctSeltn_Inv : 20|1@0+ (1,0) [0|1] "" TCP
 SG_ VehMonSrvrConctSeltn : 21|1@0+ (1,0) [0|1] "" TCP

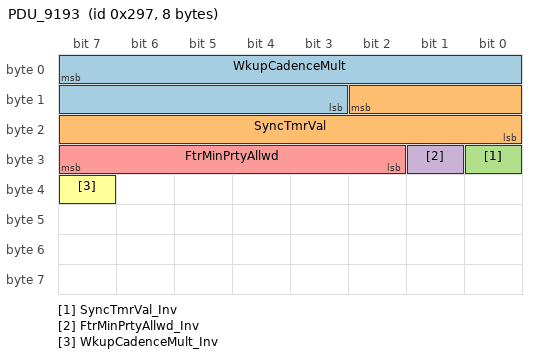
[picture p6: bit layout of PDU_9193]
BO_ 663 PDU_9193: 8 CGM
 SG_ WkupCadenceMult : 7|13@0+ (1,0) [0|8191] "min" VCU
 SG_ SyncTmrVal : 10|11@0+ (1,0) [0|2047] "Sec" VCU
 SG_ SyncTmrVal_Inv : 24|1@0+ (1,0) [0|1] "" VCU
 SG_ FtrMinPrtyAllwd_Inv : 25|1@0+ (1,0) [0|1] "" FPI,RSI,VCU
 SG_ FtrMinPrtyAllwd : 31|6@0+ (1,0) [0|63] "" FPI,RSI,VCU
 SG_ WkupCadenceMult_Inv : 39|1@0+ (1,0) [0|1] "" VCU

BA_DEF_ SG_  "SignalType" STRING ;
BA_DEF_ SG_  "SignalLongName" STRING ;
BA_DEF_ BO_  "GenMsgCycleTime" INT 0 10000;
BA_DEF_ BO_  "GenMsgSendType" ENUM "cyclicX","spontanX","cyclicIfActiveX","spontanWithDelay","cyclicAndSpontanX","cyclicAndSpontanWithDelay","spontanWithRepetition","cyclicIfActiveAndSpontanWD";
BA_DEF_DEF_  "SignalType" "";
BA_DEF_DEF_  "SignalLongName" "";
BA_DEF_DEF_  "GenMsgCycleTime" 0;
BA_DEF_DEF_  "GenMsgSendType" "cyclicX";
BA_ "GenMsgCycleTime" BO_ 1186 1000;
BA_ "GenMsgCycleTime" BO_ 1889 1000;
BA_ "GenMsgCycleTime" BO_ 1810 1000;
BA_ "GenMsgCycleTime" BO_ 1880 1000;
BA_ "GenMsgCycleTime" BO_ 1185 1000;
BA_ "GenMsgCycleTime" BO_ 1881 1000;
BA_ "GenMsgCycleTime" BO_ 1184 1000;
BA_ "GenMsgCycleTime" BO_ 1412 1000;
BA_ "GenMsgCycleTime" BO_ 1413 1000;
BA_ "GenMsgCycleTime" BO_ 1414 1000;
BA_ "GenMsgCycleTime" BO_ 1272 1000;
BA_ "GenMsgCycleTime" BO_ 1794 1000;
BA_ "GenMsgCycleTime" BO_ 1271 1000;
BA_ "GenMsgCycleTime" BO_ 1795 1000;
BA_ "GenMsgCycleTime" BO_ 1270 1000;
BA_ "GenMsgCycleTime" BO_ 1796 1000;
BA_ "GenMsgCycleTime" BO_ 1269 1000;
BA_ "GenMsgCycleTime" BO_ 1492 1000;
BA_ "GenMsgCycleTime" BO_ 1493 1000;
BA_ "GenMsgCycleTime" BO_ 1494 1000;
BA_ "GenMsgCycleTime" BO_ 1495 1000;
BA_ "GenMsgCycleTime" BO_ 1177 1000;
BA_ "GenMsgCycleTime" BO_ 1500 1000;
BA_ "GenMsgCycleTime" BO_ 1464 1000;
BA_ "GenMsgCycleTime" BO_ 1112 1000;
BA_ "GenMsgCycleTime" BO_ 1968 1000;
BA_ "GenMsgCycleTime" BO_ 1098 1000;
BA_ "GenMsgCycleTime" BO_ 1969 1000;
BA_ "GenMsgCycleTime" BO_ 1097 1000;
BA_ "GenMsgCycleTime" BO_ 1970 1000;
BA_ "GenMsgCycleTime" BO_ 663 100;
BA_ "SignalLongName" SG_ 1186 TrlrTireLRSnsrID "Trailer Tire Left Rear Sensor Identifier";
BA_ "SignalLongName" SG_ 1186 TrlrTireLtMdlPres "Trailer Tire Left Middle Pressure";
BA_ "SignalType" SG_ 1186 TrlrTireLtMdlPres_Inv "ENM";
BA_ "SignalLongName" SG_ 1186 TrlrTireLtMdlPres_Inv "Trailer Tire Left Middle Pressure Invalid";
BA_ "SignalLongName" SG_ 1186 TrlrTireLRTemp "Trailer Tire Left Rear Temperature";
BA_ "SignalType" SG_ 1186 TrlrTireLRTemp_Inv "ENM";
BA_ "SignalLongName" SG_ 1186 TrlrTireLRTemp_Inv "Trailer Tire Left Rear Temperature Invalid";
BA_ "SignalLongName" SG_ 1186 TrlrTireLtMdlTemp "Trailer Tire Left Middle Temperature";
BA_ "SignalType" SG_ 1186 TrlrTireLtMdlTemp_Inv "ENM";
BA_ "SignalLongName" SG_ 1186 TrlrTireLtMdlTemp_Inv "Trailer Tire Left Middle Temperature Invalid";
BA_ "SignalType" SG_ 1186 TrlrTirePresSysFaild "ENM";
BA_ "SignalLongName" SG_ 1186 TrlrTirePresSysFaild "Trailer Tire Pressure System Failed";
BA_ "SignalType" SG_ 1186 TrlrTirePresFtrEnbld "ENM";
BA_ "SignalLongName" SG_ 1186 TrlrTirePresFtrEnbld "Trailer Tire Pressure Feature Enabled";
BA_ "SignalType" SG_ 1186 TrlrTireRFPresSts "ENM";
BA_ "SignalLongName" SG_ 1186 TrlrTireRFPresSts "Trailer Tire Right Front Pressure Status";
BA_ "SignalType" SG_ 1186 TrlrTireRFPresSts_Inv "ENM";
BA_ "SignalLongName" SG_ 1186 TrlrTireRFPresSts_Inv "Trailer Tire Right Front Pressure Status Invalid";
BA_ "SignalType" SG_ 1889 WlkAwyLckCstAvlFlg1 "ENM";
BA_ "SignalLongName" SG_ 1889 WlkAwyLckCstAvlFlg1 "WalkAwayLockingCustomizationAvailabilityFlag1";
BA_ "SignalType" SG_ 1889 VehLctrLghtsCstAvlFlg7 "ENM";
BA_ "SignalLongName" SG_ 1889 VehLctrLghtsCstAvlFlg7 "VehicleLocatorLightsCustomizationAvailabilityFlag7";
BA_ "SignalType" SG_ 1889 VehLctrLghtsCstAvlFlg6 "ENM";
BA_ "SignalLongName" SG_ 1889 VehLctrLghtsCstAvlFlg6 "VehicleLocatorLightsCustomizationAvailabilityFlag6";
BA_ "SignalType" SG_ 1889 VehLctrLghtsCstAvlFlg5 "ENM";
BA_ "SignalLongName" SG_ 1889 VehLctrLghtsCstAvlFlg5 "VehicleLocatorLightsCustomizationAvailabilityFlag5";
BA_ "SignalType" SG_ 1889 VehLctrLghtsCstAvlFlg4 "ENM";
BA_ "SignalLongName" SG_ 1889 VehLctrLghtsCstAvlFlg4 "VehicleLocatorLightsCustomizationAvailabilityFlag4";
BA_ "SignalType" SG_ 1889 VehLctrLghtsCstAvlFlg3 "ENM";
BA_ "SignalLongName" SG_ 1889 VehLctrLghtsCstAvlFlg3 "VehicleLocatorLightsCustomizationAvailabilityFlag3";
BA_ "SignalType" SG_ 1889 VehLctrLghtsCstAvlFlg2 "ENM";
BA_ "SignalLongName" SG_ 1889 VehLctrLghtsCstAvlFlg2 "VehicleLocatorLightsCustomizationAvailabilityFlag2";
BA_ "SignalType" SG_ 1889 VehLctrLghtsCstAvlFlg1 "ENM";
BA_ "SignalLongName" SG_ 1889 VehLctrLghtsCstAvlFlg1 "VehicleLocatorLightsCustomizationAvailabilityFlag1";
BA_ "SignalType" SG_ 1889 AmbtLgtGblPrxmtyEnCstAvlFlg2 "ENM";
BA_ "SignalLongName" SG_ 1889 AmbtLgtGblPrxmtyEnCstAvlFlg2 "Ambient Light Global Proximity Enable Customization Availability Flag 2";
BA_ "SignalType" SG_ 1889 AmbtLgtGblPrxmtyEnCstAvlFlg1 "ENM";
BA_ "SignalLongName" SG_ 1889 AmbtLgtGblPrxmtyEnCstAvlFlg1 "Ambient Light Global Proximity Enable Customization Availability Flag 1";
BA_ "SignalType" SG_ 1889 WlkAwyLckCstAvlFlg7 "ENM";
BA_ "SignalLongName" SG_ 1889 WlkAwyLckCstAvlFlg7 "WalkAwayLockingCustomizationAvailabilityFlag7";
BA_ "SignalType" SG_ 1889 WlkAwyLckCstAvlFlg6 "ENM";
BA_ "SignalLongName" SG_ 1889 WlkAwyLckCstAvlFlg6 "WalkAwayLockingCustomizationAvailabilityFlag6";
BA_ "SignalType" SG_ 1889 WlkAwyLckCstAvlFlg5 "ENM";
BA_ "SignalLongName" SG_ 1889 WlkAwyLckCstAvlFlg5 "WalkAwayLockingCustomizationAvailabilityFlag5";
BA_ "SignalType" SG_ 1889 WlkAwyLckCstAvlFlg4 "ENM";
BA_ "SignalLongName" SG_ 1889 WlkAwyLckCstAvlFlg4 "WalkAwayLockingCustomizationAvailabilityFlag4";
BA_ "SignalType" SG_ 1889 WlkAwyLckCstAvlFlg3 "ENM";
BA_ "SignalLongName" SG_ 1889 WlkAwyLckCstAvlFlg3 "WalkAwayLockingCustomizationAvailabilityFlag3";
BA_ "SignalType" SG_ 1889 WlkAwyLckCstAvlFlg2 "ENM";
BA_ "SignalLongName" SG_ 1889 WlkAwyLckCstAvlFlg2 "WalkAwayLockingCustomizationAvailabilityFlag2";
BA_ "SignalType" SG_ 1889 Aux1AmbtColrCtlCstAvlFlg33 "ENM";
BA_ "SignalLongName" SG_ 1889 Aux1AmbtColrCtlCstAvlFlg33 "Auxiliary 1 Ambient Color Control Customization Availability Flag 33";
BA_ "SignalType" SG_ 1889 Aux1AmbtColrCtlCstAvlFlg32 "ENM";
BA_ "SignalLongName" SG_ 1889 Aux1AmbtColrCtlCstAvlFlg32 "Auxiliary 1 Ambient Color Control Customization Availability Flag 32";
BA_ "SignalType" SG_ 1889 AmbtLgtGblPrxmtyEnCstSetAval "ENM";
BA_ "SignalLongName" SG_ 1889 AmbtLgtGblPrxmtyEnCstSetAval "Ambient Light Global Proximity Enable Customization Setting Available";
BA_ "SignalType" SG_ 1889 AmbtLgtGblPrxmtyEnCstAvlFlg7 "ENM";
BA_ "SignalLongName" SG_ 1889 AmbtLgtGblPrxmtyEnCstAvlFlg7 "Ambient Light Global Proximity Enable Customization Availability Flag 7";
BA_ "SignalType" SG_ 1889 AmbtLgtGblPrxmtyEnCstAvlFlg6 "ENM";
BA_ "SignalLongName" SG_ 1889 AmbtLgtGblPrxmtyEnCstAvlFlg6 "Ambient Light Global Proximity Enable Customization Availability Flag 6";
BA_ "SignalType" SG_ 1889 AmbtLgtGblPrxmtyEnCstAvlFlg5 "ENM";
BA_ "SignalLongName" SG_ 1889 AmbtLgtGblPrxmtyEnCstAvlFlg5 "Ambient Light Global Proximity Enable Customization Availability Flag 5";
BA_ "SignalType" SG_ 1889 AmbtLgtGblPrxmtyEnCstAvlFlg4 "ENM";
BA_ "SignalLongName" SG_ 1889 AmbtLgtGblPrxmtyEnCstAvlFlg4 "Ambient Light Global Proximity Enable Customization Availability Flag 4";
BA_ "SignalType" SG_ 1889 AmbtLgtGblPrxmtyEnCstAvlFlg3 "ENM";
BA_ "SignalLongName" SG_ 1889 AmbtLgtGblPrxmtyEnCstAvlFlg3 "Ambient Light Global Proximity Enable Customization Availability Flag 3";
BA_ "SignalType" SG_ 1889 Aux1AmbtColrCtlCstAvlFlg41 "ENM";
BA_ "SignalLongName" SG_ 1889 Aux1AmbtColrCtlCstAvlFlg41 "Auxiliary 1 Ambient Color Control Customization Availability Flag 41";
BA_ "SignalType" SG_ 1889 Aux1AmbtColrCtlCstAvlFlg40 "ENM";
BA_ "SignalLongName" SG_ 1889 Aux1AmbtColrCtlCstAvlFlg40 "Auxiliary 1 Ambient Color Control Customization Availability Flag 40";
BA_ "SignalType" SG_ 1889 Aux1AmbtColrCtlCstAvlFlg39 "ENM";
BA_ "SignalLongName" SG_ 1889 Aux1AmbtColrCtlCstAvlFlg39 "Auxiliary 1 Ambient Color Control Customization Availability Flag 39";
BA_ "SignalType" SG_ 1889 Aux1AmbtColrCtlCstAvlFlg38 "ENM";
BA_ "SignalLongName" SG_ 1889 Aux1AmbtColrCtlCstAvlFlg38 "Auxiliary 1 Ambient Color Control Customization Availability Flag 38";
BA_ "SignalType" SG_ 1889 Aux1AmbtColrCtlCstAvlFlg37 "ENM";
BA_ "SignalLongName" SG_ 1889 Aux1AmbtColrCtlCstAvlFlg37 "Auxiliary 1 Ambient Color Control Customization Availability Flag 37";
BA_ "SignalType" SG_ 1889 Aux1AmbtColrCtlCstAvlFlg36 "ENM";
BA_ "SignalLongName" SG_ 1889 Aux1AmbtColrCtlCstAvlFlg36 "Auxiliary 1 Ambient Color Control Customization Availability Flag 36";
BA_ "SignalType" SG_ 1889 Aux1AmbtColrCtlCstAvlFlg35 "ENM";
BA_ "SignalLongName" SG_ 1889 Aux1AmbtColrCtlCstAvlFlg35 "Auxiliary 1 Ambient Color Control Customization Availability Flag 35";
BA_ "SignalType" SG_ 1889 Aux1AmbtColrCtlCstAvlFlg34 "ENM";
BA_ "SignalLongName" SG_ 1889 Aux1AmbtColrCtlCstAvlFlg34 "Auxiliary 1 Ambient Color Control Customization Availability Flag 34";
BA_ "SignalType" SG_ 1889 Aux1AmbtColrCtlCstAvlFlg49 "ENM";
BA_ "SignalLongName" SG_ 1889 Aux1AmbtColrCtlCstAvlFlg49 "Auxiliary 1 Ambient Color Control Customization Availability Flag 49";
BA_ "SignalType" SG_ 1889 Aux1AmbtColrCtlCstAvlFlg48 "ENM";
BA_ "SignalLongName" SG_ 1889 Aux1AmbtColrCtlCstAvlFlg48 "Auxiliary 1 Ambient Color Control Customization Availability Flag 48";
BA_ "SignalType" SG_ 1889 Aux1AmbtColrCtlCstAvlFlg47 "ENM";
BA_ "SignalLongName" SG_ 1889 Aux1AmbtColrCtlCstAvlFlg47 "Auxiliary 1 Ambient Color Control Customization Availability Flag 47";
BA_ "SignalType" SG_ 1889 Aux1AmbtColrCtlCstAvlFlg46 "ENM";
BA_ "SignalLongName" SG_ 1889 Aux1AmbtColrCtlCstAvlFlg46 "Auxiliary 1 Ambient Color Control Customization Availability Flag 46";
BA_ "SignalType" SG_ 1889 Aux1AmbtColrCtlCstAvlFlg45 "ENM";
BA_ "SignalLongName" SG_ 1889 Aux1AmbtColrCtlCstAvlFlg45 "Auxiliary 1 Ambient Color Control Customization Availability Flag 45";
BA_ "SignalType" SG_ 1889 Aux1AmbtColrCtlCstAvlFlg44 "ENM";
BA_ "SignalLongName" SG_ 1889 Aux1AmbtColrCtlCstAvlFlg44 "Auxiliary 1 Ambient Color Control Customization Availability Flag 44";
BA_ "SignalType" SG_ 1889 Aux1AmbtColrCtlCstAvlFlg43 "ENM";
BA_ "SignalLongName" SG_ 1889 Aux1AmbtColrCtlCstAvlFlg43 "Auxiliary 1 Ambient Color Control Customization Availability Flag 43";
BA_ "SignalType" SG_ 1889 Aux1AmbtColrCtlCstAvlFlg42 "ENM";
BA_ "SignalLongName" SG_ 1889 Aux1AmbtColrCtlCstAvlFlg42 "Auxiliary 1 Ambient Color Control Customization Availability Flag 42";
BA_ "SignalType" SG_ 1889 Aux1AmbtColrCtlCstAvlFlg57 "ENM";
BA_ "SignalLongName" SG_ 1889 Aux1AmbtColrCtlCstAvlFlg57 "Auxiliary 1 Ambient Color Control Customization Availability Flag 57";
BA_ "SignalType" SG_ 1889 Aux1AmbtColrCtlCstAvlFlg56 "ENM";
BA_ "SignalLongName" SG_ 1889 Aux1AmbtColrCtlCstAvlFlg56 "Auxiliary 1 Ambient Color Control Customization Availability Flag 56";
BA_ "SignalType" SG_ 1889 Aux1AmbtColrCtlCstAvlFlg55 "ENM";
BA_ "SignalLongName" SG_ 1889 Aux1AmbtColrCtlCstAvlFlg55 "Auxiliary 1 Ambient Color Control Customization Availability Flag 55";
BA_ "SignalType" SG_ 1889 Aux1AmbtColrCtlCstAvlFlg54 "ENM";
BA_ "SignalLongName" SG_ 1889 Aux1AmbtColrCtlCstAvlFlg54 "Auxiliary 1 Ambient Color Control Customization Availability Flag 54";
BA_ "SignalType" SG_ 1889 Aux1AmbtColrCtlCstAvlFlg53 "ENM";
BA_ "SignalLongName" SG_ 1889 Aux1AmbtColrCtlCstAvlFlg53 "Auxiliary 1 Ambient Color Control Customization Availability Flag 53";
BA_ "SignalType" SG_ 1889 Aux1AmbtColrCtlCstAvlFlg52 "ENM";
BA_ "SignalLongName" SG_ 1889 Aux1AmbtColrCtlCstAvlFlg52 "Auxiliary 1 Ambient Color Control Customization Availability Flag 52";
BA_ "SignalType" SG_ 1889 Aux1AmbtColrCtlCstAvlFlg51 "ENM";
BA_ "SignalLongName" SG_ 1889 Aux1AmbtColrCtlCstAvlFlg51 "Auxiliary 1 Ambient Color Control Customization Availability Flag 51";
BA_ "SignalType" SG_ 1889 Aux1AmbtColrCtlCstAvlFlg50 "ENM";
BA_ "SignalLongName" SG_ 1889 Aux1AmbtColrCtlCstAvlFlg50 "Auxiliary 1 Ambient Color Control Customization Availability Flag 50";
BA_ "SignalType" SG_ 1889 Aux1AmbtColrCtlCstAvlFlg65 "ENM";
BA_ "SignalLongName" SG_ 1889 Aux1AmbtColrCtlCstAvlFlg65 "Auxiliary 1 Ambient Color Control Customization Availability Flag 65";
BA_ "SignalType" SG_ 1889 Aux1AmbtColrCtlCstAvlFlg64 "ENM";
BA_ "SignalLongName" SG_ 1889 Aux1AmbtColrCtlCstAvlFlg64 "Auxiliary 1 Ambient Color Control Customization Availability Flag 64";
BA_ "SignalType" SG_ 1889 Aux1AmbtColrCtlCstAvlFlg63 "ENM";
BA_ "SignalLongName" SG_ 1889 Aux1AmbtColrCtlCstAvlFlg63 "Auxiliary 1 Ambient Color Control Customization Availability Flag 63";
BA_ "SignalType" SG_ 1889 Aux1AmbtColrCtlCstAvlFlg62 "ENM";
BA_ "SignalLongName" SG_ 1889 Aux1AmbtColrCtlCstAvlFlg62 "Auxiliary 1 Ambient Color Control Customization Availability Flag 62";
BA_ "SignalType" SG_ 1889 Aux1AmbtColrCtlCstAvlFlg61 "ENM";
BA_ "SignalLongName" SG_ 1889 Aux1AmbtColrCtlCstAvlFlg61 "Auxiliary 1 Ambient Color Control Customization Availability Flag 61";
BA_ "SignalType" SG_ 1889 Aux1AmbtColrCtlCstAvlFlg60 "ENM";
BA_ "SignalLongName" SG_ 1889 Aux1AmbtColrCtlCstAvlFlg60 "Auxiliary 1 Ambient Color Control Customization Availability Flag 60";
BA_ "SignalType" SG_ 1889 Aux1AmbtColrCtlCstAvlFlg59 "ENM";
BA_ "SignalLongName" SG_ 1889 Aux1AmbtColrCtlCstAvlFlg59 "Auxiliary 1 Ambient Color Control Customization Availability Flag 59";
BA_ "SignalType" SG_ 1889 Aux1AmbtColrCtlCstAvlFlg58 "ENM";
BA_ "SignalLongName" SG_ 1889 Aux1AmbtColrCtlCstAvlFlg58 "Auxiliary 1 Ambient Color Control Customization Availability Flag 58";
BA_ "SignalType" SG_ 1889 Aux1AmbtColrCtlCstAvlFlg73 "ENM";
BA_ "SignalLongName" SG_ 1889 Aux1AmbtColrCtlCstAvlFlg73 "Auxiliary 1 Ambient Color Control Customization Availability Flag 73";
BA_ "SignalType" SG_ 1889 Aux1AmbtColrCtlCstAvlFlg72 "ENM";
BA_ "SignalLongName" SG_ 1889 Aux1AmbtColrCtlCstAvlFlg72 "Auxiliary 1 Ambient Color Control Customization Availability Flag 72";
BA_ "SignalType" SG_ 1889 Aux1AmbtColrCtlCstAvlFlg71 "ENM";
BA_ "SignalLongName" SG_ 1889 Aux1AmbtColrCtlCstAvlFlg71 "Auxiliary 1 Ambient Color Control Customization Availability Flag 71";
BA_ "SignalType" SG_ 1889 Aux1AmbtColrCtlCstAvlFlg70 "ENM";
BA_ "SignalLongName" SG_ 1889 Aux1AmbtColrCtlCstAvlFlg70 "Auxiliary 1 Ambient Color Control Customization Availability Flag 70";
BA_ "SignalType" SG_ 1889 Aux1AmbtColrCtlCstAvlFlg69 "ENM";
BA_ "SignalLongName" SG_ 1889 Aux1AmbtColrCtlCstAvlFlg69 "Auxiliary 1 Ambient Color Control Customization Availability Flag 69";
BA_ "SignalType" SG_ 1889 Aux1AmbtColrCtlCstAvlFlg68 "ENM";
BA_ "SignalLongName" SG_ 1889 Aux1AmbtColrCtlCstAvlFlg68 "Auxiliary 1 Ambient Color Control Customization Availability Flag 68";
BA_ "SignalType" SG_ 1889 Aux1AmbtColrCtlCstAvlFlg67 "ENM";
BA_ "SignalLongName" SG_ 1889 Aux1AmbtColrCtlCstAvlFlg67 "Auxiliary 1 Ambient Color Control Customization Availability Flag 67";
BA_ "SignalType" SG_ 1889 Aux1AmbtColrCtlCstAvlFlg66 "ENM";
BA_ "SignalLongName" SG_ 1889 Aux1AmbtColrCtlCstAvlFlg66 "Auxiliary 1 Ambient Color Control Customization Availability Flag 66";
BA_ "SignalLongName" SG_ 1810 VehIdNmDig1 "Vehicle Identification Number Digit 1";
BA_ "SignalLongName" SG_ 1880 TrlrTireLtMdlSnsrID "Trailer Tire Left Middle Sensor Identifier";
BA_ "SignalLongName" SG_ 1880 TrlrTireRFSnsrID "Trailer Tire Right Front Sensor Identifier";
BA_ "SignalLongName" SG_ 1185 TrlrTireRRSnsrID "Trailer Tire Right Rear Sensor Identifier";
BA_ "SignalLongName" SG_ 1185 TrlrTireRtMdlSnsrID "Trailer Tire Right Middle Sensor Identifier";
BA_ "SignalLongName" SG_ 1881 TrlrTireRFPres "Trailer Tire Right Front Pressure";
BA_ "SignalType" SG_ 1881 TrlrTireRFPres_Inv "ENM";
BA_ "SignalLongName" SG_ 1881 TrlrTireRFPres_Inv "Trailer Tire Right Front Pressure Invalid";
BA_ "SignalLongName" SG_ 1881 TrlrTireRRPres "Trailer Tire Right Rear Pressure";
BA_ "SignalType" SG_ 1881 TrlrTireRRPres_Inv "ENM";
BA_ "SignalLongName" SG_ 1881 TrlrTireRRPres_Inv "Trailer Tire Right Rear Pressure Invalid";
BA_ "SignalLongName" SG_ 1881 TrlrTireRtMdlPres "Trailer Tire Right Middle Pressure";
BA_ "SignalType" SG_ 1881 TrlrTireRtMdlPres_Inv "ENM";
BA_ "SignalLongName" SG_ 1881 TrlrTireRtMdlPres_Inv "Trailer Tire Right Middle Pressure Invalid";
BA_ "SignalLongName" SG_ 1881 TrlrTireRFTemp "Trailer Tire Right Front Temperature";
BA_ "SignalType" SG_ 1881 TrlrTireRFTemp_Inv "ENM";
BA_ "SignalLongName" SG_ 1881 TrlrTireRFTemp_Inv "Trailer Tire Right Front Temperature Invalid";
BA_ "SignalLongName" SG_ 1881 TrlrTireRRTemp "Trailer Tire Right Rear Temperature";
BA_ "SignalType" SG_ 1881 TrlrTireRRTemp_Inv "ENM";
BA_ "SignalLongName" SG_ 1881 TrlrTireRRTemp_Inv "Trailer Tire Right Rear Temperature Invalid";
BA_ "SignalLongName" SG_ 1881 TrlrTireRtMdlTemp "Trailer Tire Right Middle Temperature";
BA_ "SignalType" SG_ 1881 TrlrTireRtMdlTemp_Inv "ENM";
BA_ "SignalLongName" SG_ 1881 TrlrTireRtMdlTemp_Inv "Trailer Tire Right Middle Temperature Invalid";
BA_ "SignalType" SG_ 1881 TrlrTireRRPresSts "ENM";
BA_ "SignalLongName" SG_ 1881 TrlrTireRRPresSts "Trailer Tire Right Rear Pressure Status";
BA_ "SignalType" SG_ 1881 TrlrTireRRPresSts_Inv "ENM";
BA_ "SignalLongName" SG_ 1881 TrlrTireRRPresSts_Inv "Trailer Tire Right Rear Pressure Status Invalid";
BA_ "SignalType" SG_ 1881 Aux1AmbtColrCtlCstAvlFlg86 "ENM";
BA_ "SignalLongName" SG_ 1881 Aux1AmbtColrCtlCstAvlFlg86 "Auxiliary 1 Ambient Color Control Customization Availability Flag 86";
BA_ "SignalType" SG_ 1881 Aux1AmbtColrCtlCstAvlFlg85 "ENM";
BA_ "SignalLongName" SG_ 1881 Aux1AmbtColrCtlCstAvlFlg85 "Auxiliary 1 Ambient Color Control Customization Availability Flag 85";
BA_ "SignalType" SG_ 1881 Aux1AmbtColrCtlCstAvlFlg84 "ENM";
BA_ "SignalLongName" SG_ 1881 Aux1AmbtColrCtlCstAvlFlg84 "Auxiliary 1 Ambient Color Control Customization Availability Flag 84";
BA_ "SignalType" SG_ 1881 TrlrTireRtMdlPresSts "ENM";
BA_ "SignalLongName" SG_ 1881 TrlrTireRtMdlPresSts "Trailer Tire Right Middle Pressure Status";
BA_ "SignalType" SG_ 1881 TrlrTireRtMdlPresSts_Inv "ENM";
BA_ "SignalLongName" SG_ 1881 TrlrTireRtMdlPresSts_Inv "Trailer Tire Right Middle Pressure Status Invalid";
BA_ "SignalType" SG_ 1184 VCCLS_CrgLmpHtchAval "ENM";
BA_ "SignalLongName" SG_ 1184 VCCLS_CrgLmpHtchAval "Virtual Control Cargo Lamp Status : Cargo Lamp Hitch Available";
BA_ "SignalType" SG_ 1184 VCCLS_CrgLmpCurrSeltnVal "ENM";
BA_ "SignalLongName" SG_ 1184 VCCLS_CrgLmpCurrSeltnVal "Virtual Control Cargo Lamp Status : Cargo Lamp Current Selection Value";
BA_ "SignalType" SG_ 1184 VCCLS_CrgLmpAval "ENM";
BA_ "SignalLongName" SG_ 1184 VCCLS_CrgLmpAval "Virtual Control Cargo Lamp Status : Cargo Lamp Available";
BA_ "SignalType" SG_ 1184 VCCLS_CrgBedLmpCurrSeltnVal "ENM";
BA_ "SignalLongName" SG_ 1184 VCCLS_CrgBedLmpCurrSeltnVal "Virtual Control Cargo Lamp Status : Cargo Bed Lamp Current Selection Value";
BA_ "SignalType" SG_ 1184 VCCLS_CrgBedLmpAval "ENM";
BA_ "SignalLongName" SG_ 1184 VCCLS_CrgBedLmpAval "Virtual Control Cargo Lamp Status : Cargo Bed Lamp Available";
BA_ "SignalType" SG_ 1184 VCCLS_AllCrgLmpUsrCtlAllwd "ENM";
BA_ "SignalLongName" SG_ 1184 VCCLS_AllCrgLmpUsrCtlAllwd "Virtual Control Cargo Lamp Status : All Cargo Lamps User Control Allowed";
BA_ "SignalType" SG_ 1184 VCDLS_DomeDftCurrSeltnVal "ENM";
BA_ "SignalLongName" SG_ 1184 VCDLS_DomeDftCurrSeltnVal "Virtual Control Dome Light Status : Dome Defeat Current Selection Value";
BA_ "SignalType" SG_ 1184 VCDLS_DomeDftAval "ENM";
BA_ "SignalLongName" SG_ 1184 VCDLS_DomeDftAval "Virtual Control Dome Light Status : Dome Defeat Available";
BA_ "SignalType" SG_ 1184 VCCLS_CrgMirLmpCurrSeltnVal "ENM";
BA_ "SignalLongName" SG_ 1184 VCCLS_CrgMirLmpCurrSeltnVal "Virtual Control Cargo Lamp Status : Cargo Mirrors Lamp Current Selection Value";
BA_ "SignalType" SG_ 1184 VCCLS_CrgMirLmpAval "ENM";
BA_ "SignalLongName" SG_ 1184 VCCLS_CrgMirLmpAval "Virtual Control Cargo Lamp Status : Cargo Mirrors Lamp Available";
BA_ "SignalType" SG_ 1184 VCCLS_CrgLmpHtchCurrSeltnVal "ENM";
BA_ "SignalLongName" SG_ 1184 VCCLS_CrgLmpHtchCurrSeltnVal "Virtual Control Cargo Lamp Status : Cargo Lamp Hitch Current Selection Value";
BA_ "SignalType" SG_ 1184 VCCSLS_CtlAval "ENM";
BA_ "SignalLongName" SG_ 1184 VCCSLS_CtlAval "Virtual Control Child Safety Lock Status : Control Available";
BA_ "SignalType" SG_ 1184 VCAHBS_UsrCtlAllwd "ENM";
BA_ "SignalLongName" SG_ 1184 VCAHBS_UsrCtlAllwd "Virtual Control Auto High Beam Status : User Control Allowed";
BA_ "SignalType" SG_ 1184 VCAHBS_CurrSeltnVal "ENM";
BA_ "SignalLongName" SG_ 1184 VCAHBS_CurrSeltnVal "Virtual Control Auto High Beam Status : Current Selection Value";
BA_ "SignalType" SG_ 1184 VCAHBS_CtlAval "ENM";
BA_ "SignalLongName" SG_ 1184 VCAHBS_CtlAval "Virtual Control Auto High Beam Status : Control Available";
BA_ "SignalType" SG_ 1184 VCDLS_DomeLgtCurrSeltnVal "ENM";
BA_ "SignalLongName" SG_ 1184 VCDLS_DomeLgtCurrSeltnVal "Virtual Control Dome Light Status : Dome Light Current Selection Value";
BA_ "SignalType" SG_ 1184 VCDLS_DomeLgtAval "ENM";
BA_ "SignalLongName" SG_ 1184 VCDLS_DomeLgtAval "Virtual Control Dome Light Status : Dome Light Available";
BA_ "SignalType" SG_ 1184 VCFLRS_CtlAval "ENM";
BA_ "SignalLongName" SG_ 1184 VCFLRS_CtlAval "Virtual Control Fog Lamps Rear Status : Control Available";
BA_ "SignalType" SG_ 1184 VCFLFS_UsrCtlAllwd "ENM";
BA_ "SignalLongName" SG_ 1184 VCFLFS_UsrCtlAllwd "Virtual Control Fog Lamps Front Status : User Control Allowed";
BA_ "SignalType" SG_ 1184 VCFLFS_CurrSeltnVal "ENM";
BA_ "SignalLongName" SG_ 1184 VCFLFS_CurrSeltnVal "Virtual Control Fog Lamps Front Status : Current Selection Value";
BA_ "SignalType" SG_ 1184 VCFLFS_CtlAval "ENM";
BA_ "SignalLongName" SG_ 1184 VCFLFS_CtlAval "Virtual Control Fog Lamps Front Status : Control Available";
BA_ "SignalType" SG_ 1184 VCCSLS_MsmtchIndOn "ENM";
BA_ "SignalLongName" SG_ 1184 VCCSLS_MsmtchIndOn "Virtual Control Child Safety Lock Status : Mismatch Indication On";
BA_ "SignalType" SG_ 1184 VCCSLS_CurrSeltnVal "ENM";
BA_ "SignalLongName" SG_ 1184 VCCSLS_CurrSeltnVal "Virtual Control Child Safety Lock Status : Current Selection Value";
BA_ "SignalLongName" SG_ 1184 RrBlw2Cmd "Rear Blower 2 Command";
BA_ "SignalType" SG_ 1184 VCPWLS_CurrSeltnVal "ENM";
BA_ "SignalLongName" SG_ 1184 VCPWLS_CurrSeltnVal "Virtual Control Power Window Lockout Status : Current Selection Value";
BA_ "SignalType" SG_ 1184 VCPWLS_CtlAval "ENM";
BA_ "SignalLongName" SG_ 1184 VCPWLS_CtlAval "Virtual Control Power Window Lockout Status : Control Available";
BA_ "SignalType" SG_ 1184 VCFLRS_UsrCtlAllwd "ENM";
BA_ "SignalLongName" SG_ 1184 VCFLRS_UsrCtlAllwd "Virtual Control Fog Lamps Rear Status : User Control Allowed";
BA_ "SignalType" SG_ 1184 VCFLRS_CurrSeltnVal "ENM";
BA_ "SignalLongName" SG_ 1184 VCFLRS_CurrSeltnVal "Virtual Control Fog Lamps Rear Status : Current Selection Value";
BA_ "SignalType" SG_ 1184 CbnAirClnFltrtnCstCurrSetVal "ENM";
BA_ "SignalLongName" SG_ 1184 CbnAirClnFltrtnCstCurrSetVal "Cabin Air Clean Filtration Customization Current Setting Value";
BA_ "SignalType" SG_ 1184 AutoNckScrfCstCurrSetVal "ENM";
BA_ "SignalLongName" SG_ 1184 AutoNckScrfCstCurrSetVal "Automatic Neck Scarf Customization Current Setting Value";
BA_ "SignalType" SG_ 1184 AutoAirOtltAmgCstCurrSetVal "ENM";
BA_ "SignalLongName" SG_ 1184 AutoAirOtltAmgCstCurrSetVal "Automatic Air Outlet Aiming Customization Current Setting Value";
BA_ "SignalType" SG_ 1184 FrtClsrAccssVirtCtlAval "ENM";
BA_ "SignalLongName" SG_ 1184 FrtClsrAccssVirtCtlAval "Front Closure Access Virtual Control Available";
BA_ "SignalType" SG_ 1184 FrtClsrAccssVirtCtlAllwd "ENM";
BA_ "SignalLongName" SG_ 1184 FrtClsrAccssVirtCtlAllwd "Front Closure Access Virtual Control Allowed";
BA_ "SignalType" SG_ 1184 DlvryModeWrnIndReq "ENM";
BA_ "SignalLongName" SG_ 1184 DlvryModeWrnIndReq "Delivery Mode Warning Indication Request";
BA_ "SignalType" SG_ 1412 IHVSLR_HtdCushBckLvl2 "ENM";
BA_ "SignalLongName" SG_ 1412 IHVSLR_HtdCushBckLvl2 "Indication Heated Vented Seat Left Rear : Heated Cushion and Back Level 2";
BA_ "SignalType" SG_ 1412 IHVSLR_HtdCushBckLvl1 "ENM";
BA_ "SignalLongName" SG_ 1412 IHVSLR_HtdCushBckLvl1 "Indication Heated Vented Seat Left Rear : Heated Cushion and Back Level 1";
BA_ "SignalType" SG_ 1412 IHVSLR_HtdCushBckAuto "ENM";
BA_ "SignalLongName" SG_ 1412 IHVSLR_HtdCushBckAuto "Indication Heated Vented Seat Left Rear : Heated Cushion and Back Auto";
BA_ "SignalType" SG_ 1412 IHVSLR_HtdBckMd "ENM";
BA_ "SignalLongName" SG_ 1412 IHVSLR_HtdBckMd "Indication Heated Vented Seat Left Rear : Heated Back Mode";
BA_ "SignalType" SG_ 1412 IHVSLR_HtdBckLvl3 "ENM";
BA_ "SignalLongName" SG_ 1412 IHVSLR_HtdBckLvl3 "Indication Heated Vented Seat Left Rear : Heated Back Level 3";
BA_ "SignalType" SG_ 1412 IHVSLR_HtdBckLvl2 "ENM";
BA_ "SignalLongName" SG_ 1412 IHVSLR_HtdBckLvl2 "Indication Heated Vented Seat Left Rear : Heated Back Level 2";
BA_ "SignalType" SG_ 1412 IHVSLR_HtdBckLvl1 "ENM";
BA_ "SignalLongName" SG_ 1412 IHVSLR_HtdBckLvl1 "Indication Heated Vented Seat Left Rear : Heated Back Level 1";
BA_ "SignalType" SG_ 1412 IHVSLR_HtdBckAuto "ENM";
BA_ "SignalLongName" SG_ 1412 IHVSLR_HtdBckAuto "Indication Heated Vented Seat Left Rear : Heated Back Auto";
BA_ "SignalType" SG_ 1412 IHVSRR_HtdBckAuto "ENM";
BA_ "SignalLongName" SG_ 1412 IHVSRR_HtdBckAuto "Indication Heated Vented Seat Right Rear : Heated Back Auto";
BA_ "SignalType" SG_ 1412 IHVSLR_VntMd "ENM";
BA_ "SignalLongName" SG_ 1412 IHVSLR_VntMd "Indication Heated Vented Seat Left Rear : Vented Mode";
BA_ "SignalType" SG_ 1412 IHVSLR_VntLvl3 "ENM";
BA_ "SignalLongName" SG_ 1412 IHVSLR_VntLvl3 "Indication Heated Vented Seat Left Rear : Vented Level 3";
BA_ "SignalType" SG_ 1412 IHVSLR_VntLvl2 "ENM";
BA_ "SignalLongName" SG_ 1412 IHVSLR_VntLvl2 "Indication Heated Vented Seat Left Rear : Vented Level 2";
BA_ "SignalType" SG_ 1412 IHVSLR_VntLvl1 "ENM";
BA_ "SignalLongName" SG_ 1412 IHVSLR_VntLvl1 "Indication Heated Vented Seat Left Rear : Vented Level 1";
BA_ "SignalType" SG_ 1412 IHVSLR_VntAuto "ENM";
BA_ "SignalLongName" SG_ 1412 IHVSLR_VntAuto "Indication Heated Vented Seat Left Rear : Vented Auto";
BA_ "SignalType" SG_ 1412 IHVSLR_HtdCushBckMd "ENM";
BA_ "SignalLongName" SG_ 1412 IHVSLR_HtdCushBckMd "Indication Heated Vented Seat Left Rear : Heated Cushion and Back Mode";
BA_ "SignalType" SG_ 1412 IHVSLR_HtdCushBckLvl3 "ENM";
BA_ "SignalLongName" SG_ 1412 IHVSLR_HtdCushBckLvl3 "Indication Heated Vented Seat Left Rear : Heated Cushion and Back Level 3";
BA_ "SignalType" SG_ 1412 IHVSRR_HtdCushBckLvl3 "ENM";
BA_ "SignalLongName" SG_ 1412 IHVSRR_HtdCushBckLvl3 "Indication Heated Vented Seat Right Rear : Heated Cushion and Back Level 3";
BA_ "SignalType" SG_ 1412 IHVSRR_HtdCushBckLvl2 "ENM";
BA_ "SignalLongName" SG_ 1412 IHVSRR_HtdCushBckLvl2 "Indication Heated Vented Seat Right Rear : Heated Cushion and Back Level 2";
BA_ "SignalType" SG_ 1412 IHVSRR_HtdCushBckLvl1 "ENM";
BA_ "SignalLongName" SG_ 1412 IHVSRR_HtdCushBckLvl1 "Indication Heated Vented Seat Right Rear : Heated Cushion and Back Level 1";
BA_ "SignalType" SG_ 1412 IHVSRR_HtdCushBckAuto "ENM";
BA_ "SignalLongName" SG_ 1412 IHVSRR_HtdCushBckAuto "Indication Heated Vented Seat Right Rear : Heated Cushion and Back Auto";
BA_ "SignalType" SG_ 1412 IHVSRR_HtdBckMd "ENM";
BA_ "SignalLongName" SG_ 1412 IHVSRR_HtdBckMd "Indication Heated Vented Seat Right Rear : Heated Back Mode";
BA_ "SignalType" SG_ 1412 IHVSRR_HtdBckLvl3 "ENM";
BA_ "SignalLongName" SG_ 1412 IHVSRR_HtdBckLvl3 "Indication Heated Vented Seat Right Rear : Heated Back Level 3";
BA_ "SignalType" SG_ 1412 IHVSRR_HtdBckLvl2 "ENM";
BA_ "SignalLongName" SG_ 1412 IHVSRR_HtdBckLvl2 "Indication Heated Vented Seat Right Rear : Heated Back Level 2";
BA_ "SignalType" SG_ 1412 IHVSRR_HtdBckLvl1 "ENM";
BA_ "SignalLongName" SG_ 1412 IHVSRR_HtdBckLvl1 "Indication Heated Vented Seat Right Rear : Heated Back Level 1";
BA_ "SignalLongName" SG_ 1412 BatSvrMdSevLvl "Battery Saver Mode Severity Level";
BA_ "SignalType" SG_ 1412 IHVSRR_VntMd "ENM";
BA_ "SignalLongName" SG_ 1412 IHVSRR_VntMd "Indication Heated Vented Seat Right Rear : Vented Mode";
BA_ "SignalType" SG_ 1412 IHVSRR_VntLvl3 "ENM";
BA_ "SignalLongName" SG_ 1412 IHVSRR_VntLvl3 "Indication Heated Vented Seat Right Rear : Vented Level 3";
BA_ "SignalType" SG_ 1412 IHVSRR_VntLvl2 "ENM";
BA_ "SignalLongName" SG_ 1412 IHVSRR_VntLvl2 "Indication Heated Vented Seat Right Rear : Vented Level 2";
BA_ "SignalType" SG_ 1412 IHVSRR_VntLvl1 "ENM";
BA_ "SignalLongName" SG_ 1412 IHVSRR_VntLvl1 "Indication Heated Vented Seat Right Rear : Vented Level 1";
BA_ "SignalType" SG_ 1412 IHVSRR_VntAuto "ENM";
BA_ "SignalLongName" SG_ 1412 IHVSRR_VntAuto "Indication Heated Vented Seat Right Rear : Vented Auto";
BA_ "SignalType" SG_ 1412 IHVSRR_HtdCushBckMd "ENM";
BA_ "SignalLongName" SG_ 1412 IHVSRR_HtdCushBckMd "Indication Heated Vented Seat Right Rear : Heated Cushion and Back Mode";
BA_ "SignalLongName" SG_ 1412 ClmCtlCbnAirCondCustLdEstd "Climate Control Cabin Air Conditioning Customer Load Estimated";
BA_ "SignalType" SG_ 1412 IndAirDstFL "ENM";
BA_ "SignalLongName" SG_ 1412 IndAirDstFL "Indication Air Distribution Front Left";
BA_ "SignalType" SG_ 1412 DrHndlLFAuthReqd "ENM";
BA_ "SignalLongName" SG_ 1412 DrHndlLFAuthReqd "Door Handle Left Front Authentication Requested";
BA_ "SignalType" SG_ 1412 AirDflctrIndReq "ENM";
BA_ "SignalLongName" SG_ 1412 AirDflctrIndReq "Air Deflector Indication Request";
BA_ "SignalType" SG_ 1412 IndAirDstFR "ENM";
BA_ "SignalLongName" SG_ 1412 IndAirDstFR "Indication Air Distribution Front Right";
BA_ "SignalType" SG_ 1412 HVACUsrCtlIntrctnDispReqd "ENM";
BA_ "SignalLongName" SG_ 1412 HVACUsrCtlIntrctnDispReqd "HVAC User Controls Interaction Display Requested";
BA_ "SignalType" SG_ 1412 FrtClsrRelAuthReqd "ENM";
BA_ "SignalLongName" SG_ 1412 FrtClsrRelAuthReqd "Front Closure Release Authentication Requested";
BA_ "SignalType" SG_ 1412 DrHndlRRAuthReqd "ENM";
BA_ "SignalLongName" SG_ 1412 DrHndlRRAuthReqd "Door Handle Right Rear Authentication Requested";
BA_ "SignalType" SG_ 1412 DrHndlRFAuthReqd "ENM";
BA_ "SignalLongName" SG_ 1412 DrHndlRFAuthReqd "Door Handle Right Front Authentication Requested";
BA_ "SignalType" SG_ 1412 DrHndlLRAuthReqd "ENM";
BA_ "SignalLongName" SG_ 1412 DrHndlLRAuthReqd "Door Handle Left Rear Authentication Requested";
BA_ "SignalLongName" SG_ 1413 IndTmpStngLvlFR "Indication Temperature Setting Level Front Right";
BA_ "SignalLongName" SG_ 1413 IndTmpStngLvlFL "Indication Temperature Setting Level Front Left";
BA_ "SignalLongName" SG_ 1413 IndTmpStngLvlRL "Indication Temperature Setting Level Rear Left";
BA_ "SignalLongName" SG_ 1413 IndTmpStngLvlRR "Indication Temperature Setting Level Rear Right";
BA_ "SignalType" SG_ 1413 IndAirDstRL "ENM";
BA_ "SignalLongName" SG_ 1413 IndAirDstRL "Indication Air Distribution Rear Left";
BA_ "SignalLongName" SG_ 1413 IndBlwStngLvlFrt "Indication Blower Setting Level Front";
BA_ "SignalType" SG_ 1413 IndAirDstRR "ENM";
BA_ "SignalLongName" SG_ 1413 IndAirDstRR "Indication Air Distribution Rear Right";
BA_ "SignalType" SG_ 1413 IndBlwStngStRr "ENM";
BA_ "SignalLongName" SG_ 1413 IndBlwStngStRr "Indication Blower Setting State Rear";
BA_ "SignalType" SG_ 1413 IndBlwStngStFrt "ENM";
BA_ "SignalLongName" SG_ 1413 IndBlwStngStFrt "Indication Blower Setting State Front";
BA_ "SignalLongName" SG_ 1413 IndBlwStngLvlRr "Indication Blower Setting Level Rear";
BA_ "SignalType" SG_ 1413 IndHtdFrtWshldSet "ENM";
BA_ "SignalLongName" SG_ 1413 IndHtdFrtWshldSet "Indication Heated Front Windshield Setting";
BA_ "SignalType" SG_ 1413 IndFrtHVAC_On "ENM";
BA_ "SignalLongName" SG_ 1413 IndFrtHVAC_On "Indication Front HVAC On";
BA_ "SignalType" SG_ 1413 IndRecircStng "ENM";
BA_ "SignalLongName" SG_ 1413 IndRecircStng "Indication Recirculation Setting";
BA_ "SignalType" SG_ 1413 IndCompStng "ENM";
BA_ "SignalLongName" SG_ 1413 IndCompStng "Indication Compressor Setting";
BA_ "SignalType" SG_ 1413 IndSYNC_Rr "ENM";
BA_ "SignalLongName" SG_ 1413 IndSYNC_Rr "Indication SYNC Rear";
BA_ "SignalType" SG_ 1413 IndSYNC_All "ENM";
BA_ "SignalLongName" SG_ 1413 IndSYNC_All "Indication SYNC All";
BA_ "SignalType" SG_ 1413 IndRrWndDfgStng "ENM";
BA_ "SignalLongName" SG_ 1413 IndRrWndDfgStng "Indication Rear Window Defog Setting";
BA_ "SignalType" SG_ 1413 IndRrHVAC_On "ENM";
BA_ "SignalLongName" SG_ 1413 IndRrHVAC_On "Indication Rear HVAC On";
BA_ "SignalType" SG_ 1413 IndRrHVAC_Lckd "ENM";
BA_ "SignalLongName" SG_ 1413 IndRrHVAC_Lckd "Indication Rear HVAC Locked";
BA_ "SignalType" SG_ 1414 IndTmpStngStRL "ENM";
BA_ "SignalLongName" SG_ 1414 IndTmpStngStRL "Indication Temperature Setting State Rear Left";
BA_ "SignalType" SG_ 1414 IndTmpStngStFR "ENM";
BA_ "SignalLongName" SG_ 1414 IndTmpStngStFR "Indication Temperature Setting State Front Right";
BA_ "SignalType" SG_ 1414 IndTmpStngStFL "ENM";
BA_ "SignalLongName" SG_ 1414 IndTmpStngStFL "Indication Temperature Setting State Front Left";
BA_ "SignalType" SG_ 1414 PwrRrClsrCstCurrSetVal "ENM";
BA_ "SignalLongName" SG_ 1414 PwrRrClsrCstCurrSetVal "Power Rear Closure Customization Current Setting Value";
BA_ "SignalType" SG_ 1414 PFASndSeltnCstCurrSetVal "ENM";
BA_ "SignalLongName" SG_ 1414 PFASndSeltnCstCurrSetVal "Pedestrian Friendly Alert Sound Selection Customization Current Setting Value";
BA_ "SignalType" SG_ 1414 IndTmpStngStRR "ENM";
BA_ "SignalLongName" SG_ 1414 IndTmpStngStRR "Indication Temperature Setting State Rear Right";
BA_ "SignalType" SG_ 1414 ManlPrkLmpChmEvtSt "ENM";
BA_ "SignalLongName" SG_ 1414 ManlPrkLmpChmEvtSt "Manual Parklamps On ChimeEventState";
BA_ "SignalType" SG_ 1414 LDCLDlydLkChmEvSt "ENM";
BA_ "SignalLongName" SG_ 1414 LDCLDlydLkChmEvSt "Last Door Closed Locking Delayed Locking Chime Event State";
BA_ "SignalType" SG_ 1414 KeyInRmdrChmEvntSt "ENM";
BA_ "SignalLongName" SG_ 1414 KeyInRmdrChmEvntSt "Key In Reminder Chime Event State";
BA_ "SignalType" SG_ 1414 PwrRrClsrNtfnChmEvntStat "ENM";
BA_ "SignalLongName" SG_ 1414 PwrRrClsrNtfnChmEvntStat "Power Rear Closure Notification Chime Event State";
BA_ "SignalType" SG_ 1414 PwrRrClsrNormOpChmEvntStat "ENM";
BA_ "SignalLongName" SG_ 1414 PwrRrClsrNormOpChmEvntStat "Power Rear Closure Normal Operation Chime Event State";
BA_ "SignalType" SG_ 1414 OneSidedPrkLmpActvnChmEvtSt "ENM";
BA_ "SignalLongName" SG_ 1414 OneSidedPrkLmpActvnChmEvtSt "OneSidedParkLampActivationChimeEventState";
BA_ "SignalType" SG_ 1414 NoRtDetWrngChmEvSt "ENM";
BA_ "SignalLongName" SG_ 1414 NoRtDetWrngChmEvSt "No Remote Detected Warning Chime Event State";
BA_ "SignalType" SG_ 1414 RetainedACCpwrStatus "ENM";
BA_ "SignalLongName" SG_ 1414 RetainedACCpwrStatus "Retained Accesory Power Signal Group : Retained Accessory Power Status";
BA_ "SignalType" SG_ 1414 PMMiRAPStatus "ENM";
BA_ "SignalLongName" SG_ 1414 PMMiRAPStatus "Retained Accesory Power Signal Group : PMM iRAP Status";
BA_ "SignalType" SG_ 1414 ShfttoPrkChmEvntSt "ENM";
BA_ "SignalLongName" SG_ 1414 ShfttoPrkChmEvntSt "Shift To Park Chime Event State";
BA_ "SignalType" SG_ 1414 RemLtInVhWrngChmEvSt "ENM";
BA_ "SignalLongName" SG_ 1414 RemLtInVhWrngChmEvSt "Remote Left In Vehicle Warning Chime Event State";
BA_ "SignalType" SG_ 1414 PwrRrClsrObstclChmEvntStat "ENM";
BA_ "SignalLongName" SG_ 1414 PwrRrClsrObstclChmEvntStat "Power Rear Closure Obstacle Chime Event State";
BA_ "SignalType" SG_ 1414 PFASndSeltnCstSetAval "ENM";
BA_ "SignalLongName" SG_ 1414 PFASndSeltnCstSetAval "Pedestrian Friendly Alert Sound Selection Customization Setting Available";
BA_ "SignalType" SG_ 1414 PFASndSeltnCstAvlFlg7 "ENM";
BA_ "SignalLongName" SG_ 1414 PFASndSeltnCstAvlFlg7 "Pedestrian Friendly Alert Sound Selection Customization Availability Flag 7";
BA_ "SignalType" SG_ 1414 PFASndSeltnCstAvlFlg6 "ENM";
BA_ "SignalLongName" SG_ 1414 PFASndSeltnCstAvlFlg6 "Pedestrian Friendly Alert Sound Selection Customization Availability Flag 6";
BA_ "SignalType" SG_ 1414 PFASndSeltnCstAvlFlg5 "ENM";
BA_ "SignalLongName" SG_ 1414 PFASndSeltnCstAvlFlg5 "Pedestrian Friendly Alert Sound Selection Customization Availability Flag 5";
BA_ "SignalType" SG_ 1414 PFASndSeltnCstAvlFlg4 "ENM";
BA_ "SignalLongName" SG_ 1414 PFASndSeltnCstAvlFlg4 "Pedestrian Friendly Alert Sound Selection Customization Availability Flag 4";
BA_ "SignalType" SG_ 1414 PFASndSeltnCstAvlFlg3 "ENM";
BA_ "SignalLongName" SG_ 1414 PFASndSeltnCstAvlFlg3 "Pedestrian Friendly Alert Sound Selection Customization Availability Flag 3";
BA_ "SignalType" SG_ 1414 PFASndSeltnCstAvlFlg2 "ENM";
BA_ "SignalLongName" SG_ 1414 PFASndSeltnCstAvlFlg2 "Pedestrian Friendly Alert Sound Selection Customization Availability Flag 2";
BA_ "SignalType" SG_ 1414 PFASndSeltnCstAvlFlg1 "ENM";
BA_ "SignalLongName" SG_ 1414 PFASndSeltnCstAvlFlg1 "Pedestrian Friendly Alert Sound Selection Customization Availability Flag 1";
BA_ "SignalType" SG_ 1414 PwrRrClsrCstSetAval "ENM";
BA_ "SignalLongName" SG_ 1414 PwrRrClsrCstSetAval "Power Rear Closure Customization Setting Available";
BA_ "SignalType" SG_ 1414 PwrRrClsrCstAvlFlg7 "ENM";
BA_ "SignalLongName" SG_ 1414 PwrRrClsrCstAvlFlg7 "Power Rear Closure Customization Availability Flag 7";
BA_ "SignalType" SG_ 1414 PwrRrClsrCstAvlFlg6 "ENM";
BA_ "SignalLongName" SG_ 1414 PwrRrClsrCstAvlFlg6 "Power Rear Closure Customization Availability Flag 6";
BA_ "SignalType" SG_ 1414 PwrRrClsrCstAvlFlg5 "ENM";
BA_ "SignalLongName" SG_ 1414 PwrRrClsrCstAvlFlg5 "Power Rear Closure Customization Availability Flag 5";
BA_ "SignalType" SG_ 1414 PwrRrClsrCstAvlFlg4 "ENM";
BA_ "SignalLongName" SG_ 1414 PwrRrClsrCstAvlFlg4 "Power Rear Closure Customization Availability Flag 4";
BA_ "SignalType" SG_ 1414 PwrRrClsrCstAvlFlg3 "ENM";
BA_ "SignalLongName" SG_ 1414 PwrRrClsrCstAvlFlg3 "Power Rear Closure Customization Availability Flag 3";
BA_ "SignalType" SG_ 1414 PwrRrClsrCstAvlFlg2 "ENM";
BA_ "SignalLongName" SG_ 1414 PwrRrClsrCstAvlFlg2 "Power Rear Closure Customization Availability Flag 2";
BA_ "SignalType" SG_ 1414 PwrRrClsrCstAvlFlg1 "ENM";
BA_ "SignalLongName" SG_ 1414 PwrRrClsrCstAvlFlg1 "Power Rear Closure Customization Availability Flag 1";
BA_ "SignalType" SG_ 1414 StBltShfIntlkCstAvlFlg7 "ENM";
BA_ "SignalLongName" SG_ 1414 StBltShfIntlkCstAvlFlg7 "Seat Belt Shift Interlock Customization Availability Flag7";
BA_ "SignalType" SG_ 1414 StBltShfIntlkCstAvlFlg6 "ENM";
BA_ "SignalLongName" SG_ 1414 StBltShfIntlkCstAvlFlg6 "Seat Belt Shift Interlock Customization Availability Flag6";
BA_ "SignalType" SG_ 1414 StBltShfIntlkCstAvlFlg5 "ENM";
BA_ "SignalLongName" SG_ 1414 StBltShfIntlkCstAvlFlg5 "Seat Belt Shift Interlock Customization Availability Flag5";
BA_ "SignalType" SG_ 1414 StBltShfIntlkCstAvlFlg4 "ENM";
BA_ "SignalLongName" SG_ 1414 StBltShfIntlkCstAvlFlg4 "Seat Belt Shift Interlock Customization Availability Flag4";
BA_ "SignalType" SG_ 1414 StBltShfIntlkCstAvlFlg3 "ENM";
BA_ "SignalLongName" SG_ 1414 StBltShfIntlkCstAvlFlg3 "Seat Belt Shift Interlock Customization Availability Flag3";
BA_ "SignalType" SG_ 1414 StBltShfIntlkCstAvlFlg2 "ENM";
BA_ "SignalLongName" SG_ 1414 StBltShfIntlkCstAvlFlg2 "Seat Belt Shift Interlock Customization Availability Flag2";
BA_ "SignalType" SG_ 1414 StBltShfIntlkCstAvlFlg1 "ENM";
BA_ "SignalLongName" SG_ 1414 StBltShfIntlkCstAvlFlg1 "Seat Belt Shift Interlock Customization Availability Flag1";
BA_ "SignalType" SG_ 1414 RrClsrRelAuthReqd "ENM";
BA_ "SignalLongName" SG_ 1414 RrClsrRelAuthReqd "Rear Closure Release Authentication Requested";
BA_ "SignalType" SG_ 1272 IndInzrStat "ENM";
BA_ "SignalLongName" SG_ 1272 IndInzrStat "Indication Ionizer Status";
BA_ "SignalType" SG_ 1272 ConThftAlrmTrg "ENM";
BA_ "SignalLongName" SG_ 1272 ConThftAlrmTrg "Content Theft Alarm Trigger";
BA_ "SignalType" SG_ 1272 ClmCtlBatSvrIndOn "ENM";
BA_ "SignalLongName" SG_ 1272 ClmCtlBatSvrIndOn "Climate Control Battery Saver Indication On";
BA_ "SignalType" SG_ 1272 AutoLgtsInActvIndOn "ENM";
BA_ "SignalLongName" SG_ 1272 AutoLgtsInActvIndOn "Automatic Lights Inactive Indication On";
BA_ "SignalType" SG_ 1272 AutoLgtsActvIndOn "ENM";
BA_ "SignalLongName" SG_ 1272 AutoLgtsActvIndOn "Automatic Lights Active Indication On";
BA_ "SignalType" SG_ 1272 ACCmpsrOprtng "ENM";
BA_ "SignalLongName" SG_ 1272 ACCmpsrOprtng "Air Conditioning Compressor Operating";
BA_ "SignalType" SG_ 1272 HtdStrgWhlInd_HVAC_FP_F "ENM";
BA_ "SignalLongName" SG_ 1272 HtdStrgWhlInd_HVAC_FP_F "Heated Steering Wheel Indication - HVAC Front Faceplate";
BA_ "SignalType" SG_ 1272 HtdFrntWSSt "ENM";
BA_ "SignalLongName" SG_ 1272 HtdFrntWSSt "Heated Front Windshield Status";
BA_ "SignalType" SG_ 1272 ConThftSrvcIO "ENM";
BA_ "SignalLongName" SG_ 1272 ConThftSrvcIO "Content Theft Service Indication On";
BA_ "SignalType" SG_ 1272 ConThftAttmpdIO "ENM";
BA_ "SignalLongName" SG_ 1272 ConThftAttmpdIO "Content Theft Attempted Indication On";
BA_ "SignalType" SG_ 1272 CnvtBkWndNotNormzIO "ENM";
BA_ "SignalLongName" SG_ 1272 CnvtBkWndNotNormzIO "Convertible Back Window Not Normalized Indication On";
BA_ "SignalType" SG_ 1272 CmpSftTopMotBfrOpTrnkIO "ENM";
BA_ "SignalLongName" SG_ 1272 CmpSftTopMotBfrOpTrnkIO "Complete Soft Top Motion Before Open Trunk Indication On";
BA_ "SignalType" SG_ 1272 CmbdDrHndlActvRF "ENM";
BA_ "SignalLongName" SG_ 1272 CmbdDrHndlActvRF "Combined Door Handle Active Right Front";
BA_ "SignalType" SG_ 1272 CmbdDrHndlActvLF "ENM";
BA_ "SignalLongName" SG_ 1272 CmbdDrHndlActvLF "Combined Door Handle Active Left Front";
BA_ "SignalType" SG_ 1272 DrIntHndlActnStatLF "ENM";
BA_ "SignalLongName" SG_ 1272 DrIntHndlActnStatLF "Left Front Door Interior Handle Actuation Status";
BA_ "SignalType" SG_ 1272 DrExtHndlActnStatRR "ENM";
BA_ "SignalLongName" SG_ 1272 DrExtHndlActnStatRR "Right Rear Door Exterior Handle Actuation Status";
BA_ "SignalType" SG_ 1272 DrExtHndlActnStatRF "ENM";
BA_ "SignalLongName" SG_ 1272 DrExtHndlActnStatRF "Right Front Door Exterior Handle Actuation Status";
BA_ "SignalType" SG_ 1272 DrExtHndlActnStatLR "ENM";
BA_ "SignalLongName" SG_ 1272 DrExtHndlActnStatLR "Left Rear Door Exterior Handle Actuation Status";
BA_ "SignalType" SG_ 1272 DrExtHndlActnStatLF "ENM";
BA_ "SignalLongName" SG_ 1272 DrExtHndlActnStatLF "Left Front Door Exterior Handle Actuation Status";
BA_ "SignalType" SG_ 1272 DlydAccTmrActv "ENM";
BA_ "SignalLongName" SG_ 1272 DlydAccTmrActv "Delayed Accessory Timer Active";
BA_ "SignalType" SG_ 1272 CrgLghtEnbldIO "ENM";
BA_ "SignalLongName" SG_ 1272 CrgLghtEnbldIO "Cargo Light Enabled Indication On";
BA_ "SignalType" SG_ 1272 CrgLghtDsbldIO "ENM";
BA_ "SignalLongName" SG_ 1272 CrgLghtDsbldIO "Cargo Light Disabled Indication On";
BA_ "SignalType" SG_ 1272 FrtClmAppFltDtnActv "ENM";
BA_ "SignalLongName" SG_ 1272 FrtClmAppFltDtnActv "Front Climate App Fault Detection Active";
BA_ "SignalType" SG_ 1272 FobProgMdStatCmplt "ENM";
BA_ "SignalLongName" SG_ 1272 FobProgMdStatCmplt "Exiting Fob Programming Indication On";
BA_ "SignalType" SG_ 1272 FobPrevLrndIndOn "ENM";
BA_ "SignalLongName" SG_ 1272 FobPrevLrndIndOn "Fob Previously Learned Indication On";
BA_ "SignalType" SG_ 1272 FobPogLimRchdIndOn "ENM";
BA_ "SignalLongName" SG_ 1272 FobPogLimRchdIndOn "Fob Programming Limit Reached Indication On";
BA_ "SignalType" SG_ 1272 EntrFobProgIndOn "ENM";
BA_ "SignalLongName" SG_ 1272 EntrFobProgIndOn "Entering Fob Programming Indication On";
BA_ "SignalType" SG_ 1272 DrIntHndlActnStatRR "ENM";
BA_ "SignalLongName" SG_ 1272 DrIntHndlActnStatRR "Right Rear Door Interior Handle Actuation Status";
BA_ "SignalType" SG_ 1272 DrIntHndlActnStatRF "ENM";
BA_ "SignalLongName" SG_ 1272 DrIntHndlActnStatRF "Right Front Door Interior Handle Actuation Status";
BA_ "SignalType" SG_ 1272 DrIntHndlActnStatLR "ENM";
BA_ "SignalLongName" SG_ 1272 DrIntHndlActnStatLR "Left Rear Door Interior Handle Actuation Status";
BA_ "SignalType" SG_ 1272 HtdFrtWshldUnvIndOn "ENM";
BA_ "SignalLongName" SG_ 1272 HtdFrtWshldUnvIndOn "Heated Front Windshield Unavailable Indication On";
BA_ "SignalType" SG_ 1272 HiBmIO "ENM";
BA_ "SignalLongName" SG_ 1272 HiBmIO "High Beam Indication On";
BA_ "SignalType" SG_ 1272 HazSwAtvIO "ENM";
BA_ "SignalLongName" SG_ 1272 HazSwAtvIO "Hazard Switch Active Indication On";
BA_ "SignalType" SG_ 1272 HVAC_StngsCtrlAvlbl "ENM";
BA_ "SignalLongName" SG_ 1272 HVAC_StngsCtrlAvlbl "HVAC Settings Controller Available";
BA_ "SignalType" SG_ 1272 FrtSnshdNormzRqrdIO "ENM";
BA_ "SignalLongName" SG_ 1272 FrtSnshdNormzRqrdIO "Front Sunshade Normalization Required Indication On";
BA_ "SignalType" SG_ 1272 FrtCmptServIndOn "ENM";
BA_ "SignalLongName" SG_ 1272 FrtCmptServIndOn "Front Storage Compartment Service Indication On";
BA_ "SignalType" SG_ 1272 IntrSnsDsbld "ENM";
BA_ "SignalLongName" SG_ 1272 IntrSnsDsbld "Intrusion Sensing Disabled";
BA_ "SignalType" SG_ 1272 InrTlgtOpnIndOn "ENM";
BA_ "SignalLongName" SG_ 1272 InrTlgtOpnIndOn "Inner Tailgate Open Indication On";
BA_ "SignalType" SG_ 1272 IndTmpUnts "ENM";
BA_ "SignalLongName" SG_ 1272 IndTmpUnts "Indication Temperature Units";
BA_ "SignalType" SG_ 1272 IndIntrAirQltyDispActv "ENM";
BA_ "SignalLongName" SG_ 1272 IndIntrAirQltyDispActv "Indication Interior Air Quality Display Active";
BA_ "SignalType" SG_ 1272 KeyInWrnIO "ENM";
BA_ "SignalLongName" SG_ 1272 KeyInWrnIO "Key In Warning Indication On";
BA_ "SignalLongName" SG_ 1794 IAQI_IntrAirQltyOvrallIdx "Interior Air Quality Indications : Interior Air Quality Overall Index";
BA_ "SignalLongName" SG_ 1794 IAQI_IntrAirQltyNumOfStats "Interior Air Quality Indications : Interior Air Quality Number Of States";
BA_ "SignalType" SG_ 1794 IAQI_IntrAirQltyOvrallStat "ENM";
BA_ "SignalLongName" SG_ 1794 IAQI_IntrAirQltyOvrallStat "Interior Air Quality Indications : Interior Air Quality Overall State";
BA_ "SignalLongName" SG_ 1794 IAQI_IntrAirQltyOvrallSclPstn "Interior Air Quality Indications : Interior Air Quality Overall Scale Position";
BA_ "SignalLongName" SG_ 1794 IAQI_IntrAirQltyPrtclteIdx "Interior Air Quality Indications : Interior Air Quality Particulate Index";
BA_ "SignalLongName" SG_ 1794 IAQI_IntrAirQltyPrtclteSclPstn "Interior Air Quality Indications : Interior Air Quality Particulate Scale Position";
BA_ "SignalType" SG_ 1794 IntrDimPlcSrvlnceModeActv "ENM";
BA_ "SignalLongName" SG_ 1794 IntrDimPlcSrvlnceModeActv "Interior Dimming Police Surveillance Mode Active";
BA_ "SignalType" SG_ 1794 IAQI_IntrAirQltyPrtclteStat "ENM";
BA_ "SignalLongName" SG_ 1794 IAQI_IntrAirQltyPrtclteStat "Interior Air Quality Indications : Interior Air Quality Particulate State";
BA_ "SignalType" SG_ 1271 TDRCADD_LKAstAlrtsEvnts "ENM";
BA_ "SignalLongName" SG_ 1271 TDRCADD_LKAstAlrtsEvnts "Teen Driver Report Card Available Display Data : Lane Keep Assist Alerts Events";
BA_ "SignalType" SG_ 1271 TDRCADD_LDWEvnts "ENM";
BA_ "SignalLongName" SG_ 1271 TDRCADD_LDWEvnts "Teen Driver Report Card Available Display Data : Lane Departure Warning Events";
BA_ "SignalType" SG_ 1271 TDRCADD_FCMBrEvts "ENM";
BA_ "SignalLongName" SG_ 1271 TDRCADD_FCMBrEvts "Teen Driver Report Card Available Display Data : Forward Collision Mitigation Braking Events";
BA_ "SignalType" SG_ 1271 TDRCADD_FCImntAlrts "ENM";
BA_ "SignalLongName" SG_ 1271 TDRCADD_FCImntAlrts "Teen Driver Report Card Available Display Data : Forward Collision Imminent Alerts";
BA_ "SignalType" SG_ 1271 TDRCADD_FCHdwyAlrt "ENM";
BA_ "SignalLongName" SG_ 1271 TDRCADD_FCHdwyAlrt "Teen Driver Report Card Available Display Data : Forward Collision Headway Alerts";
BA_ "SignalType" SG_ 1271 TDRCADD_DrwDrvAlrt "ENM";
BA_ "SignalLongName" SG_ 1271 TDRCADD_DrwDrvAlrt "Teen Driver Report Card Available Display Data : Drowsy Driver Alerts";
BA_ "SignalType" SG_ 1271 TDRCADD_DistDrvn "ENM";
BA_ "SignalLongName" SG_ 1271 TDRCADD_DistDrvn "Teen Driver Report Card Available Display Data : Distance Driven";
BA_ "SignalType" SG_ 1271 TDRCADD_ABSAtvEvt "ENM";
BA_ "SignalLongName" SG_ 1271 TDRCADD_ABSAtvEvt "Teen Driver Report Card Available Display Data : Antilock Braking System Active Events";
BA_ "SignalType" SG_ 1271 TDRCADD_WOTEvnts "ENM";
BA_ "SignalLongName" SG_ 1271 TDRCADD_WOTEvnts "Teen Driver Report Card Available Display Data : Wide Open Throttle Events";
BA_ "SignalType" SG_ 1271 TDRCADD_UnbckldDistDrvn "ENM";
BA_ "SignalLongName" SG_ 1271 TDRCADD_UnbckldDistDrvn "Teen Driver Report Card Available Display Data : Unbuckled Distance Driven";
BA_ "SignalType" SG_ 1271 TDRCADD_TrCtrlEvnts "ENM";
BA_ "SignalLongName" SG_ 1271 TDRCADD_TrCtrlEvnts "Teen Driver Report Card Available Display Data : Traction Control Events";
BA_ "SignalType" SG_ 1271 TDRCADD_StCtrlEvnts "ENM";
BA_ "SignalLongName" SG_ 1271 TDRCADD_StCtrlEvnts "Teen Driver Report Card Available Display Data : Stability Control Events";
BA_ "SignalType" SG_ 1271 TDRCADD_RCMBrEvts "ENM";
BA_ "SignalLongName" SG_ 1271 TDRCADD_RCMBrEvts "Teen Driver Report Card Available Display Data : Reverse Collision Mitigation Braking Events";
BA_ "SignalType" SG_ 1271 TDRCADD_OvrSpdDistDrvn "ENM";
BA_ "SignalLongName" SG_ 1271 TDRCADD_OvrSpdDistDrvn "Teen Driver Report Card Available Display Data : Overspeed Distance Driven";
BA_ "SignalType" SG_ 1271 TDRCADD_OvSpdEvnt "ENM";
BA_ "SignalLongName" SG_ 1271 TDRCADD_OvSpdEvnt "Teen Driver Report Card Available Display Data : Overspeed Events";
BA_ "SignalType" SG_ 1271 TDRCADD_MaxSpd "ENM";
BA_ "SignalLongName" SG_ 1271 TDRCADD_MaxSpd "Teen Driver Report Card Available Display Data : Maximum Speed";
BA_ "SignalType" SG_ 1271 RemCtrlFobNumForProg "ENM";
BA_ "SignalLongName" SG_ 1271 RemCtrlFobNumForProg "Remote Control Fob Number For Programming";
BA_ "SignalType" SG_ 1271 LstKyFbFnctnReq "ENM";
BA_ "SignalLongName" SG_ 1271 LstKyFbFnctnReq "Last Key Fob Function Request";
BA_ "SignalType" SG_ 1271 SnrfPstnSts "ENM";
BA_ "SignalLongName" SG_ 1271 SnrfPstnSts "Sunroof Position Status";
BA_ "SignalType" SG_ 1271 TeenDrvRsp "ENM";
BA_ "SignalLongName" SG_ 1271 TeenDrvRsp "Teen Driver Response";
BA_ "SignalType" SG_ 1271 NghtSchmAtv "ENM";
BA_ "SignalLongName" SG_ 1271 NghtSchmAtv "Night Scheme Active";
BA_ "SignalType" SG_ 1271 TireLkDtnEnblSts "ENM";
BA_ "SignalLongName" SG_ 1271 TireLkDtnEnblSts "Tire Leak Detection Enable Status";
BA_ "SignalType" SG_ 1271 RrClsrLckSts "ENM";
BA_ "SignalLongName" SG_ 1271 RrClsrLckSts "Rear Closure Lock Status";
BA_ "SignalType" SG_ 1271 StrtModeElecSeltnIndReq "ENM";
BA_ "SignalLongName" SG_ 1271 StrtModeElecSeltnIndReq "Start Mode Electric Selection Indication Request";
BA_ "SignalType" SG_ 1271 RrDrUnlckIO "ENM";
BA_ "SignalLongName" SG_ 1271 RrDrUnlckIO "Rear Door Unlock Indication On";
BA_ "SignalType" SG_ 1271 RnSnsOffIO "ENM";
BA_ "SignalLongName" SG_ 1271 RnSnsOffIO "Rain Sensor Off Indication On";
BA_ "SignalType" SG_ 1271 RnSnsActIO "ENM";
BA_ "SignalLongName" SG_ 1271 RnSnsActIO "Rain Sensor Active Indication On";
BA_ "SignalType" SG_ 1271 RmtPRNDLDispFltIndOn "ENM";
BA_ "SignalLongName" SG_ 1271 RmtPRNDLDispFltIndOn "Remote PRNDL Display Fault Indication On";
BA_ "SignalType" SG_ 1271 RmtCtlFobBatLoIndOn "ENM";
BA_ "SignalLongName" SG_ 1271 RmtCtlFobBatLoIndOn "Remote Control Fob Battery Low Indication On";
BA_ "SignalType" SG_ 1271 PwrLftgtUnvIndOn "ENM";
BA_ "SignalLongName" SG_ 1271 PwrLftgtUnvIndOn "Power Liftgate Unavailable Indication On";
BA_ "SignalType" SG_ 1271 PwrLftgtOffIndOn "ENM";
BA_ "SignalLongName" SG_ 1271 PwrLftgtOffIndOn "Power Liftgate Off Indication On";
BA_ "SignalType" SG_ 1271 PrkLmpIO "ENM";
BA_ "SignalLongName" SG_ 1271 PrkLmpIO "Park Lamp Indication On";
BA_ "SignalType" SG_ 1271 ShftrLckdBcklDrvrStBltIndOn "ENM";
BA_ "SignalLongName" SG_ 1271 ShftrLckdBcklDrvrStBltIndOn "Shifter Locked Buckle Driver Seatbelt Indication On";
BA_ "SignalType" SG_ 1271 ServPwrLftgtIndOn "ENM";
BA_ "SignalLongName" SG_ 1271 ServPwrLftgtIndOn "Service Power Liftgate Indication On";
BA_ "SignalType" SG_ 1271 ServKylsStSysIO "ENM";
BA_ "SignalLongName" SG_ 1271 ServKylsStSysIO "Service Keyless Start System Indication On";
BA_ "SignalType" SG_ 1271 ServHtdStrgWhlIndOn "ENM";
BA_ "SignalLongName" SG_ 1271 ServHtdStrgWhlIndOn "Service Heated Steering Wheel Indication On";
BA_ "SignalType" SG_ 1271 ServHdlmpsIndOn "ENM";
BA_ "SignalLongName" SG_ 1271 ServHdlmpsIndOn "Service Headlamps Indication On";
BA_ "SignalType" SG_ 1271 ServDrLtchSysIO "ENM";
BA_ "SignalLongName" SG_ 1271 ServDrLtchSysIO "Service Door Latch System Indication On";
BA_ "SignalType" SG_ 1271 RrStRmndrIndOn "ENM";
BA_ "SignalLongName" SG_ 1271 RrStRmndrIndOn "Rear Seat Reminder Indication On";
BA_ "SignalType" SG_ 1271 RrSnshdNormzRqrdIO "ENM";
BA_ "SignalLongName" SG_ 1271 RrSnshdNormzRqrdIO "Rear Sunshade Normalization Required Indication On";
BA_ "SignalType" SG_ 1271 MechShftrLckdHldBrkToOvrrdIndOn "ENM";
BA_ "SignalLongName" SG_ 1271 MechShftrLckdHldBrkToOvrrdIndOn "Mechanical Shifter Locked Hold Brake To Override Indication On";
BA_ "SignalType" SG_ 1271 HdOpnShftrLckdOvrrdCmpltIndOn "ENM";
BA_ "SignalLongName" SG_ 1271 HdOpnShftrLckdOvrrdCmpltIndOn "Hood Open Shifter Locked Override Complete Indication On";
BA_ "SignalType" SG_ 1271 TeenDrvFtrAvl "ENM";
BA_ "SignalLongName" SG_ 1271 TeenDrvFtrAvl "Teen Driver Feature Available";
BA_ "SignalType" SG_ 1271 StNtLtchdThrdRowIO "ENM";
BA_ "SignalLongName" SG_ 1271 StNtLtchdThrdRowIO "DEPRECATED VIP 24 - Seat Not Latched Third Row Indication On";
BA_ "SignalType" SG_ 1271 SnrfNormzRqrdIO "ENM";
BA_ "SignalLongName" SG_ 1271 SnrfNormzRqrdIO "Sunroof Normalization Required Indication On";
BA_ "SignalType" SG_ 1271 ShftrUnlckdBrktoShfIndOn "ENM";
BA_ "SignalLongName" SG_ 1271 ShftrUnlckdBrktoShfIndOn "Shifter Unlocked Brake to Shift Indication On";
BA_ "SignalType" SG_ 1271 ShftrLckdBcklPsngrStBltIndOn "ENM";
BA_ "SignalLongName" SG_ 1271 ShftrLckdBcklPsngrStBltIndOn "Shifter Locked Buckle Passenger Seatbelt Indication On";
BA_ "SignalLongName" SG_ 1795 TeenDrvMaxSpdRpt "Teen Driver Maximum Speed Report";
BA_ "SignalLongName" SG_ 1795 TDFwdClnHdwyAlrtsRpt "Teen Driver Forward Collision Headway Alerts Report";
BA_ "SignalLongName" SG_ 1795 TDFwdClnImntAlrtsRpt "Teen Driver Forward Collision Imminent Alerts Report";
BA_ "SignalLongName" SG_ 1795 TDFwdClnMtgnBrEvRpt "Teen Driver Forward Collision Mitigation Braking Events Report";
BA_ "SignalLongName" SG_ 1795 TDRevClnMtgnBrEvRpt "Teen Driver Reverse Collision Mitigation Braking Events Report";
BA_ "SignalLongName" SG_ 1795 TeenDrvLDWEvntsRpt "Teen Driver Lane Departure Warning Events Report";
BA_ "SignalType" SG_ 1795 MidgateAjrIndOn "ENM";
BA_ "SignalLongName" SG_ 1795 MidgateAjrIndOn "Midgate Ajar Indication On";
BA_ "SignalType" SG_ 1795 MidgateAjr "ENM";
BA_ "SignalLongName" SG_ 1795 MidgateAjr "Midgate Ajar";
BA_ "SignalLongName" SG_ 1270 TirePrsLRInr "Tire Pressure Left Rear Inner Information : Tire Pressure Left Rear Inner";
BA_ "SignalLongName" SG_ 1270 TirePrsRRInr "Tire Pressure Right Rear Inner Information : Tire Pressure Right Rear Inner";
BA_ "SignalType" SG_ 1270 TirePrsStatLRInr "ENM";
BA_ "SignalLongName" SG_ 1270 TirePrsStatLRInr "Tire Pressure Left Rear Inner Information : TPMS Status Left Rear Inner";
BA_ "SignalType" SG_ 1270 TirePrsLRInr_Inv "ENM";
BA_ "SignalLongName" SG_ 1270 TirePrsLRInr_Inv "Tire Pressure Left Rear Inner Information : Tire Pressure Left Rear Inner Invalid";
BA_ "SignalType" SG_ 1270 TirePrsStatRRInr "ENM";
BA_ "SignalLongName" SG_ 1270 TirePrsStatRRInr "Tire Pressure Right Rear Inner Information : TPMS Status Right Rear Inner";
BA_ "SignalType" SG_ 1270 TirePrsRRInr_Inv "ENM";
BA_ "SignalLongName" SG_ 1270 TirePrsRRInr_Inv "Tire Pressure Right Rear Inner Information : Tire Pressure Right Rear Inner Invalid";
BA_ "SignalLongName" SG_ 1270 TeenDrvWOTEvntsRpt "Teen Driver Wide Open Throttle Events Report";
BA_ "SignalLongName" SG_ 1270 TnDrvABSAtvEvntsRpt "Teen Driver Antilock Brake System Active Events Report";
BA_ "SignalLongName" SG_ 1270 TeenDrvRmnPINRtry "Teen Driver Remaining PIN Retry";
BA_ "SignalType" SG_ 1270 TnDrvDRLOffUnbIO "ENM";
BA_ "SignalLongName" SG_ 1270 TnDrvDRLOffUnbIO "Teen Driver Daytime Running Lights Off Unavailable Indication On";
BA_ "SignalType" SG_ 1270 TnDrvALCOffUnbIO "ENM";
BA_ "SignalLongName" SG_ 1270 TnDrvALCOffUnbIO "Teen Driver Automatic Light Control Off Unavailable Indication On";
BA_ "SignalType" SG_ 1270 TlmtcsImmbAtv "ENM";
BA_ "SignalLongName" SG_ 1270 TlmtcsImmbAtv "Telematics Immobilization Active";
BA_ "SignalType" SG_ 1270 TirePrsLrnActIO "ENM";
BA_ "SignalLongName" SG_ 1270 TirePrsLrnActIO "TPMS Learn Mode Active Indication On";
BA_ "SignalType" SG_ 1270 TnDrvRptCrdAval "ENM";
BA_ "SignalLongName" SG_ 1270 TnDrvRptCrdAval "Teen Driver Report Card Available";
BA_ "SignalType" SG_ 1270 TnDrvPINStrd "ENM";
BA_ "SignalLongName" SG_ 1270 TnDrvPINStrd "Teen Driver PIN Stored";
BA_ "SignalType" SG_ 1270 TnDrvOvrSpdIO "ENM";
BA_ "SignalLongName" SG_ 1270 TnDrvOvrSpdIO "Teen Driver OverSpeed Indication On";
BA_ "SignalLongName" SG_ 1796 TnDrvDistDrvnRpt "Teen Driver Distance Driven Report";
BA_ "SignalLongName" SG_ 1796 TnDrvOvSpdDistDrvn "Teen Driver Overspeed Distance Driven";
BA_ "SignalLongName" SG_ 1796 TnDrvDrowDrvAlrtsRpt "Teen Driver Drowsy Driver Alerts Report";
BA_ "SignalLongName" SG_ 1796 TnDrvLKAstAlrtEvntsRpt "Teen Driver Lane Keep Assist Alerts Events Report";
BA_ "SignalLongName" SG_ 1796 TnDrvOvSpdEvntsRpt "Teen Driver Over Speed Events Report";
BA_ "SignalLongName" SG_ 1269 TnDrvUnbckldDistDrvn "Teen Driver Unbuckled Distance Driven";
BA_ "SignalLongName" SG_ 1269 TnDrvStblCtrlEvntsRpt "Teen Driver Stability Control Events Report";
BA_ "SignalLongName" SG_ 1269 TnDrvTrCtrlEvntsRpt "Teen Driver Traction Control Events Report";
BA_ "SignalType" SG_ 1269 ValetMdResponse "ENM";
BA_ "SignalLongName" SG_ 1269 ValetMdResponse "Valet Mode Lock Information : Valet Mode Lock Response";
BA_ "SignalType" SG_ 1269 VTDDrvIndReq "ENM";
BA_ "SignalLongName" SG_ 1269 VTDDrvIndReq "VTD Driver Indication Request";
BA_ "SignalType" SG_ 1269 TrnspModeActvIndOn "ENM";
BA_ "SignalLongName" SG_ 1269 TrnspModeActvIndOn "Transport Mode Active Indication On";
BA_ "SignalType" SG_ 1269 TrlrLtngSeqStat "ENM";
BA_ "SignalLongName" SG_ 1269 TrlrLtngSeqStat "Trailer Lighting Sequence Status";
BA_ "SignalType" SG_ 1269 TrPrsMntrSysFld "ENM";
BA_ "SignalLongName" SG_ 1269 TrPrsMntrSysFld "Tire Pressure Monitoring System Failed";
BA_ "SignalType" SG_ 1269 TPMTrLrnMdCmplt "ENM";
BA_ "SignalLongName" SG_ 1269 TPMTrLrnMdCmplt "TPMS Learn Complete Status";
BA_ "SignalType" SG_ 1269 TrPrsMntrTrLdStat "ENM";
BA_ "SignalLongName" SG_ 1269 TrPrsMntrTrLdStat "Tire Pressure Monitoring Tire Loading Status";
BA_ "SignalType" SG_ 1269 ValetModeActive "ENM";
BA_ "SignalLongName" SG_ 1269 ValetModeActive "Valet Mode Lock Information : Valet Mode Active";
BA_ "SignalType" SG_ 1269 WndNormzRF "ENM";
BA_ "SignalLongName" SG_ 1269 WndNormzRF "Window Normalized Right Front";
BA_ "SignalType" SG_ 1269 WndNormzLR "ENM";
BA_ "SignalLongName" SG_ 1269 WndNormzLR "Window Normalized Left Rear";
BA_ "SignalType" SG_ 1269 WndNormzLF "ENM";
BA_ "SignalLongName" SG_ 1269 WndNormzLF "Window Normalized Left Front";
BA_ "SignalType" SG_ 1269 VTDDrvMsgIO "ENM";
BA_ "SignalLongName" SG_ 1269 VTDDrvMsgIO "VTD Driver Message Indication On";
BA_ "SignalType" SG_ 1269 TxLrnFldIO "ENM";
BA_ "SignalLongName" SG_ 1269 TxLrnFldIO "Transmitter Learn Failed Indication On";
BA_ "SignalType" SG_ 1269 TxBkUpLctIO "ENM";
BA_ "SignalLongName" SG_ 1269 TxBkUpLctIO "Transmitter Backup Location Indication On";
BA_ "SignalType" SG_ 1269 TurnWprIntIO "ENM";
BA_ "SignalLongName" SG_ 1269 TurnWprIntIO "Turn Wiper Control To Intermittent First Indication On";
BA_ "SignalType" SG_ 1269 TrnspModeInactiveIndOn "ENM";
BA_ "SignalLongName" SG_ 1269 TrnspModeInactiveIndOn "Transport Mode Inactive Indication On";
BA_ "SignalType" SG_ 1269 InfoAnm1Req "ENM";
BA_ "SignalLongName" SG_ 1269 InfoAnm1Req "Infotainment Animation 1 Request";
BA_ "SignalType" SG_ 1269 BlkhdDrAjr "ENM";
BA_ "SignalLongName" SG_ 1269 BlkhdDrAjr "Bulkhead Door Ajar";
BA_ "SignalType" SG_ 1269 WndNtNrmzdIORR "ENM";
BA_ "SignalLongName" SG_ 1269 WndNtNrmzdIORR "Window Not Normalized Indication On Right Rear";
BA_ "SignalType" SG_ 1269 WndNtNrmzdIOLR "ENM";
BA_ "SignalLongName" SG_ 1269 WndNtNrmzdIOLR "Window Not Normalized Indication On Left Rear";
BA_ "SignalType" SG_ 1269 WndNtNrmzdIODrv "ENM";
BA_ "SignalLongName" SG_ 1269 WndNtNrmzdIODrv "Window Not Normalized Indication On Driver";
BA_ "SignalType" SG_ 1269 WndNtNrmzdIOCoDrv "ENM";
BA_ "SignalLongName" SG_ 1269 WndNtNrmzdIOCoDrv "Window Not Normalized Indication On Co-Driver";
BA_ "SignalType" SG_ 1269 WndNormzRR "ENM";
BA_ "SignalLongName" SG_ 1269 WndNormzRR "Window Normalized Right Rear";
BA_ "SignalType" SG_ 1492 ACCCSV_Aux1Colr "ENM";
BA_ "SignalLongName" SG_ 1492 ACCCSV_Aux1Colr "Ambient Control Customization Current Setting Value : Auxiliary 1 Color";
BA_ "SignalType" SG_ 1492 ACCCSV_Aux1Brghtns "ENM";
BA_ "SignalLongName" SG_ 1492 ACCCSV_Aux1Brghtns "Ambient Control Customization Current Setting Value : Auxiliary 1 Brightness";
BA_ "SignalType" SG_ 1492 ACCCSV_Aux1Anm "ENM";
BA_ "SignalLongName" SG_ 1492 ACCCSV_Aux1Anm "Ambient Control Customization Current Setting Value : Auxiliary 1 Animation";
BA_ "SignalType" SG_ 1492 ACCCSV_IntrAnm "ENM";
BA_ "SignalLongName" SG_ 1492 ACCCSV_IntrAnm "Ambient Control Customization Current Setting Value : Interior Animation";
BA_ "SignalType" SG_ 1492 ACCCSV_IntrColr "ENM";
BA_ "SignalLongName" SG_ 1492 ACCCSV_IntrColr "Ambient Control Customization Current Setting Value : Interior Color";
BA_ "SignalType" SG_ 1492 ACCCSV_IntrBrghtns "ENM";
BA_ "SignalLongName" SG_ 1492 ACCCSV_IntrBrghtns "Ambient Control Customization Current Setting Value : Interior Brightness";
BA_ "SignalType" SG_ 1492 AutDrvLckCstCurSetVal "ENM";
BA_ "SignalLongName" SG_ 1492 AutDrvLckCstCurSetVal "AutomaticDriveLockingCustomizationCurrentSettingValue";
BA_ "SignalType" SG_ 1492 AirQltySnsCstCrStVal "ENM";
BA_ "SignalLongName" SG_ 1492 AirQltySnsCstCrStVal "Air Quality Sensor Customization Current Setting Value";
BA_ "SignalType" SG_ 1492 AutoAirDstCstCrStVal "ENM";
BA_ "SignalLongName" SG_ 1492 AutoAirDstCstCrStVal "Automatic Air Distribution Customization Current Setting Value";
BA_ "SignalType" SG_ 1492 AutMirFldCstCurSetVal "ENM";
BA_ "SignalLongName" SG_ 1492 AutMirFldCstCurSetVal "AutoMirrorFoldCustomizationCurrentSettingValue";
BA_ "SignalType" SG_ 1492 AutoFanCstCrStVal "ENM";
BA_ "SignalLongName" SG_ 1492 AutoFanCstCrStVal "Automatic Fan Customization Current Setting Value";
BA_ "SignalType" SG_ 1492 AutoDfgCstCrStVal "ENM";
BA_ "SignalLongName" SG_ 1492 AutoDfgCstCrStVal "Automatic Defog Customization Current Setting Value";
BA_ "SignalType" SG_ 1492 AutoCoolStCstCrStVal "ENM";
BA_ "SignalLongName" SG_ 1492 AutoCoolStCstCrStVal "Automatic Cooled Seat Customization Current Setting Value";
BA_ "SignalType" SG_ 1492 AirQltySnsCstStAvl "ENM";
BA_ "SignalLongName" SG_ 1492 AirQltySnsCstStAvl "Air Quality Sensor Customization Setting Available";
BA_ "SignalType" SG_ 1492 AutoRrWpCstCurSetVal "ENM";
BA_ "SignalLongName" SG_ 1492 AutoRrWpCstCurSetVal "AutoRearWipeCustomizationCurrentSettingValue";
BA_ "SignalType" SG_ 1492 AutoHtdStCstCrStVal "ENM";
BA_ "SignalLongName" SG_ 1492 AutoHtdStCstCrStVal "Automatic Heated Seat Customization Current Setting Value";
BA_ "SignalType" SG_ 1492 AutoRrWpCstStAvl "ENM";
BA_ "SignalLongName" SG_ 1492 AutoRrWpCstStAvl "AutoRearWipeCustomizationSettingAvailable";
BA_ "SignalType" SG_ 1492 AutoHtdStCstStAvl "ENM";
BA_ "SignalLongName" SG_ 1492 AutoHtdStCstStAvl "Automatic Heated Seat Customization Setting Available";
BA_ "SignalType" SG_ 1492 AutoFanCstStAvl "ENM";
BA_ "SignalLongName" SG_ 1492 AutoFanCstStAvl "Automatic Fan Customization Setting Available";
BA_ "SignalType" SG_ 1492 AutoDfgCstStAvl "ENM";
BA_ "SignalLongName" SG_ 1492 AutoDfgCstStAvl "Automatic Defog Customization Setting Available";
BA_ "SignalType" SG_ 1492 AutoCoolStCstStAvl "ENM";
BA_ "SignalLongName" SG_ 1492 AutoCoolStCstStAvl "Automatic Cooled Seat Customization Setting Available";
BA_ "SignalType" SG_ 1492 AutoAirDstCstStAvl "ENM";
BA_ "SignalLongName" SG_ 1492 AutoAirDstCstStAvl "Automatic Air Distribution Customization Setting Available";
BA_ "SignalType" SG_ 1492 AutMirFldCstStAvl "ENM";
BA_ "SignalLongName" SG_ 1492 AutMirFldCstStAvl "AutoMirrorFoldCustomizationSettingAvailable";
BA_ "SignalType" SG_ 1492 AutDrvLckCstStAvl "ENM";
BA_ "SignalLongName" SG_ 1492 AutDrvLckCstStAvl "AutomaticDriveLockingCustomizationSettingAvailable";
BA_ "SignalLongName" SG_ 1493 RmtReFlshElecPwrRdnes "Remote ReFlash Electic Power Readiness";
BA_ "SignalType" SG_ 1493 PlltnCtrlCstCrStVal "ENM";
BA_ "SignalLongName" SG_ 1493 PlltnCtrlCstCrStVal "Pollution Control Customization Current Setting Value";
BA_ "SignalType" SG_ 1493 OpDrAtLOCstCurSetVal "ENM";
BA_ "SignalLongName" SG_ 1493 OpDrAtLOCstCurSetVal "OpenDoorAntiLockOutCustomizationCurrentSettingValue";
BA_ "SignalType" SG_ 1493 LDCLCstCurSetVal "ENM";
BA_ "SignalLongName" SG_ 1493 LDCLCstCurSetVal "LastDoorClosedLockingCustomizationCurrentSettingValue";
BA_ "SignalType" SG_ 1493 RemLftVehRmndrCstCurSetVal "ENM";
BA_ "SignalLongName" SG_ 1493 RemLftVehRmndrCstCurSetVal "RemoteLeftVehicleReminderCustomizationCurrentSettingValue";
BA_ "SignalType" SG_ 1493 RemInVehRmndrCstCurSetVal "ENM";
BA_ "SignalLongName" SG_ 1493 RemInVehRmndrCstCurSetVal "RemoteInVehicleReminderCustomizationCurrentSettingValue";
BA_ "SignalType" SG_ 1493 PsvUnlckCstCurSetVal "ENM";
BA_ "SignalLongName" SG_ 1493 PsvUnlckCstCurSetVal "PassiveUnlockingCustomizationCurrentSettingValue";
BA_ "SignalType" SG_ 1493 RlkRtUlkDrCstCrSetVal "ENM";
BA_ "SignalLongName" SG_ 1493 RlkRtUlkDrCstCrSetVal "RelockRemoteUnlockedDoorCustomizationCurrentSettingValue";
BA_ "SignalType" SG_ 1493 RevTltMirCstCurSetVal "ENM";
BA_ "SignalLongName" SG_ 1493 RevTltMirCstCurSetVal "ReverseTiltMirrorCustomizationCurrentSettingValue";
BA_ "SignalType" SG_ 1493 RmtStrtHtdStCstCrStVal "ENM";
BA_ "SignalLongName" SG_ 1493 RmtStrtHtdStCstCrStVal "Remote Start Heated Seat Customization Current Setting Value";
BA_ "SignalType" SG_ 1493 RmtStrtCoolStCstCrStVal "ENM";
BA_ "SignalLongName" SG_ 1493 RmtStrtCoolStCstCrStVal "Remote Start Cooled Seat Customization Current Setting Value";
BA_ "SignalType" SG_ 1493 RmtSnrfOpCstCurrSetVal "ENM";
BA_ "SignalLongName" SG_ 1493 RmtSnrfOpCstCurrSetVal "Remote Sunroof Operation Customization Current Setting Value";
BA_ "SignalType" SG_ 1493 RrAirHandlingDrActrPwrReq "ENM";
BA_ "SignalLongName" SG_ 1493 RrAirHandlingDrActrPwrReq "Rear Air Handling Door Actuator Power Request";
BA_ "SignalType" SG_ 1493 RnSnsCstCurSetVal "ENM";
BA_ "SignalLongName" SG_ 1493 RnSnsCstCurSetVal "RainSenseCustomizationCurrentSettingValue";
BA_ "SignalType" SG_ 1493 RmtWndOpCstCurSetVal "ENM";
BA_ "SignalLongName" SG_ 1493 RmtWndOpCstCurSetVal "RemoteWindowOperationCustomizationCurrentSettingValue";
BA_ "SignalType" SG_ 1493 RevTltMirCstStAvl "ENM";
BA_ "SignalLongName" SG_ 1493 RevTltMirCstStAvl "ReverseTiltMirrorCustomizationSettingAvailable";
BA_ "SignalType" SG_ 1493 RemLftVehRmndrCstStAvl "ENM";
BA_ "SignalLongName" SG_ 1493 RemLftVehRmndrCstStAvl "RemoteLeftVehicleReminderCustomizationSettingAvailable";
BA_ "SignalType" SG_ 1493 RemInVehRmndrCstStAvl "ENM";
BA_ "SignalLongName" SG_ 1493 RemInVehRmndrCstStAvl "RemoteInVehicleReminderCustomizationSettingAvailable";
BA_ "SignalType" SG_ 1493 PsvUnlckCstStAvl "ENM";
BA_ "SignalLongName" SG_ 1493 PsvUnlckCstStAvl "PassiveUnlockingCustomizationSettingAvailable";
BA_ "SignalType" SG_ 1493 PlltnCtrlCstStAvl "ENM";
BA_ "SignalLongName" SG_ 1493 PlltnCtrlCstStAvl "Pollution Control Customization Setting Available";
BA_ "SignalType" SG_ 1493 OpDrAtLOCstStAvl "ENM";
BA_ "SignalLongName" SG_ 1493 OpDrAtLOCstStAvl "OpenDoorAntiLockOutCustomizationSettingAvailable";
BA_ "SignalType" SG_ 1493 LDCLCstStAvl "ENM";
BA_ "SignalLongName" SG_ 1493 LDCLCstStAvl "LastDoorClosedLockingCustomizationSettingAvailable";
BA_ "SignalType" SG_ 1493 RnSnsCstStAvl "ENM";
BA_ "SignalLongName" SG_ 1493 RnSnsCstStAvl "RainSenseCustomizationSettingAvailable";
BA_ "SignalType" SG_ 1493 RmtWndOpCstStAvl "ENM";
BA_ "SignalLongName" SG_ 1493 RmtWndOpCstStAvl "RemoteWindowOperationCustomizationSettingAvailable";
BA_ "SignalType" SG_ 1493 RmtStrtHtdStCstStAvl "ENM";
BA_ "SignalLongName" SG_ 1493 RmtStrtHtdStCstStAvl "Remote Start Heated Seat Customization Setting Available";
BA_ "SignalType" SG_ 1493 RmtStrtCoolStCstStAvl "ENM";
BA_ "SignalLongName" SG_ 1493 RmtStrtCoolStCstStAvl "Remote Start Cooled Seat Customization Setting Available";
BA_ "SignalType" SG_ 1493 RmtSnrfOpCstSetAval "ENM";
BA_ "SignalLongName" SG_ 1493 RmtSnrfOpCstSetAval "Remote Sunroof Operation Customization Setting Available";
BA_ "SignalType" SG_ 1493 RlkRtUlkDrCstStAvl "ENM";
BA_ "SignalLongName" SG_ 1493 RlkRtUlkDrCstStAvl "RelockRemoteUnlockedDoorCustomizationSettingAvailable";
BA_ "SignalLongName" SG_ 1494 TDOSWCCSV_DspVal "Teen Driver Overspeed Warning Customization Current Setting Value : Display Value";
BA_ "SignalType" SG_ 1494 TDOSWCCSV_CrSetVal "ENM";
BA_ "SignalLongName" SG_ 1494 TDOSWCCSV_CrSetVal "Teen Driver Overspeed Warning Customization Current Setting Value : Current Setting Value";
BA_ "SignalType" SG_ 1494 TDSLCCSV_CrSetVal "ENM";
BA_ "SignalLongName" SG_ 1494 TDSLCCSV_CrSetVal "Teen Driver Speed Limit Customization Current Setting Value : Current Setting Value";
BA_ "SignalLongName" SG_ 1494 TDSLCCSV_DspVal "Teen Driver Speed Limit Customization Current Setting Value : Display Value";
BA_ "SignalType" SG_ 1494 RrStRmndrEnblDsblCstCurrSetVal "ENM";
BA_ "SignalLongName" SG_ 1494 RrStRmndrEnblDsblCstCurrSetVal "Rear Seat Reminder Enable Disable Customization Current Setting Value";
BA_ "SignalType" SG_ 1494 RrDfgStUpCstCrStVal "ENM";
BA_ "SignalLongName" SG_ 1494 RrDfgStUpCstCrStVal "Rear Defog Startup Customization Current Setting Value";
BA_ "SignalType" SG_ 1494 RtUlkLtFbCstCurSetVal "ENM";
BA_ "SignalLongName" SG_ 1494 RtUlkLtFbCstCurSetVal "RemoteUnlockLightingFeedbackCustomizationCurrentSettingValue";
BA_ "SignalType" SG_ 1494 RtLkFdbkCstCurSetVal "ENM";
BA_ "SignalLongName" SG_ 1494 RtLkFdbkCstCurSetVal "RemoteLockingFeedbackCustomizationCurrentSettingValue";
BA_ "SignalType" SG_ 1494 RrZnStUpCstCrStVal "ENM";
BA_ "SignalLongName" SG_ 1494 RrZnStUpCstCrStVal "Rear Zone Startup Customization Current Setting Value";
BA_ "SignalType" SG_ 1494 WlkAwyLckCstCurSetVal "ENM";
BA_ "SignalLongName" SG_ 1494 WlkAwyLckCstCurSetVal "WalkAwayLockingCustomizationCurrentSettingValue";
BA_ "SignalType" SG_ 1494 VehLctrLghtsCstCurSetVal "ENM";
BA_ "SignalLongName" SG_ 1494 VehLctrLghtsCstCurSetVal "VehicleLocatorLightsCustomizationCurrentSettingValue";
BA_ "SignalType" SG_ 1494 SelUlkCstCurSetVal "ENM";
BA_ "SignalLongName" SG_ 1494 SelUlkCstCurSetVal "SelectiveUnlockingCustomizationCurrentSettingValue";
BA_ "SignalType" SG_ 1494 SelUlkCstStAvl "ENM";
BA_ "SignalLongName" SG_ 1494 SelUlkCstStAvl "SelectiveUnlockingCustomizationSettingAvailable";
BA_ "SignalType" SG_ 1494 RtUlkLtFbCstStAvl "ENM";
BA_ "SignalLongName" SG_ 1494 RtUlkLtFbCstStAvl "RemoteUnlockLightingFeedbackCustomizationSettingAvailable";
BA_ "SignalType" SG_ 1494 RtLkFdbkCstStAvl "ENM";
BA_ "SignalLongName" SG_ 1494 RtLkFdbkCstStAvl "RemoteLockingFeedbackCustomizationSettingAvailable";
BA_ "SignalType" SG_ 1494 RrZnStUpCstStAvl "ENM";
BA_ "SignalLongName" SG_ 1494 RrZnStUpCstStAvl "Rear Zone Startup Customization Setting Available";
BA_ "SignalType" SG_ 1494 RrStRmndrEnblDsblCstSetAval "ENM";
BA_ "SignalLongName" SG_ 1494 RrStRmndrEnblDsblCstSetAval "Rear Seat Reminder Enable Disable Customization Setting Available";
BA_ "SignalType" SG_ 1494 RrDfgStUpCstStAvl "ENM";
BA_ "SignalLongName" SG_ 1494 RrDfgStUpCstStAvl "Rear Defog Startup Customization Setting Available";
BA_ "SignalType" SG_ 1494 WlkAwyLckCstStAvl "ENM";
BA_ "SignalLongName" SG_ 1494 WlkAwyLckCstStAvl "WalkAwayLockingCustomizationSettingAvailable";
BA_ "SignalType" SG_ 1494 VehLctrLghtsCstStAvl "ENM";
BA_ "SignalLongName" SG_ 1494 VehLctrLghtsCstStAvl "VehicleLocatorLightsCustomizationSettingAvailable";
BA_ "SignalType" SG_ 1494 TnDrvSpdLmtCstStAvl "ENM";
BA_ "SignalLongName" SG_ 1494 TnDrvSpdLmtCstStAvl "Teen Driver Speed Limit Customization Setting Available";
BA_ "SignalType" SG_ 1494 TnDrvOvSpdWrnCstStAvl "ENM";
BA_ "SignalLongName" SG_ 1494 TnDrvOvSpdWrnCstStAvl "Teen Driver Overspeed Warning Customization Setting Available";
BA_ "SignalType" SG_ 1495 IHVSLF_HtdCushBckLvl2 "ENM";
BA_ "SignalLongName" SG_ 1495 IHVSLF_HtdCushBckLvl2 "Indication Heated Vented Seat Left Front : Heated Cushion and Back Level 2";
BA_ "SignalType" SG_ 1495 IHVSLF_HtdCushBckLvl1 "ENM";
BA_ "SignalLongName" SG_ 1495 IHVSLF_HtdCushBckLvl1 "Indication Heated Vented Seat Left Front : Heated Cushion and Back Level 1";
BA_ "SignalType" SG_ 1495 IHVSLF_HtdCushBckAuto "ENM";
BA_ "SignalLongName" SG_ 1495 IHVSLF_HtdCushBckAuto "Indication Heated Vented Seat Left Front : Heated Cushion and Back Auto";
BA_ "SignalType" SG_ 1495 IHVSLF_HtdBckMd "ENM";
BA_ "SignalLongName" SG_ 1495 IHVSLF_HtdBckMd "Indication Heated Vented Seat Left Front : Heated Back Mode";
BA_ "SignalType" SG_ 1495 IHVSLF_HtdBckLvl3 "ENM";
BA_ "SignalLongName" SG_ 1495 IHVSLF_HtdBckLvl3 "Indication Heated Vented Seat Left Front : Heated Back Level 3";
BA_ "SignalType" SG_ 1495 IHVSLF_HtdBckLvl2 "ENM";
BA_ "SignalLongName" SG_ 1495 IHVSLF_HtdBckLvl2 "Indication Heated Vented Seat Left Front : Heated Back Level 2";
BA_ "SignalType" SG_ 1495 IHVSLF_HtdBckLvl1 "ENM";
BA_ "SignalLongName" SG_ 1495 IHVSLF_HtdBckLvl1 "Indication Heated Vented Seat Left Front : Heated Back Level 1";
BA_ "SignalType" SG_ 1495 IHVSLF_HtdBckAuto "ENM";
BA_ "SignalLongName" SG_ 1495 IHVSLF_HtdBckAuto "Indication Heated Vented Seat Left Front : Heated Back Auto";
BA_ "SignalType" SG_ 1495 IHVSRF_HtdBckAuto "ENM";
BA_ "SignalLongName" SG_ 1495 IHVSRF_HtdBckAuto "Indication Heated Vented Seat Right Front : Heated Back Auto";
BA_ "SignalType" SG_ 1495 IHVSLF_VntMd "ENM";
BA_ "SignalLongName" SG_ 1495 IHVSLF_VntMd "Indication Heated Vented Seat Left Front : Vented Mode";
BA_ "SignalType" SG_ 1495 IHVSLF_VntLvl3 "ENM";
BA_ "SignalLongName" SG_ 1495 IHVSLF_VntLvl3 "Indication Heated Vented Seat Left Front : Vented Level 3";
BA_ "SignalType" SG_ 1495 IHVSLF_VntLvl2 "ENM";
BA_ "SignalLongName" SG_ 1495 IHVSLF_VntLvl2 "Indication Heated Vented Seat Left Front : Vented Level 2";
BA_ "SignalType" SG_ 1495 IHVSLF_VntLvl1 "ENM";
BA_ "SignalLongName" SG_ 1495 IHVSLF_VntLvl1 "Indication Heated Vented Seat Left Front : Vented Level 1";
BA_ "SignalType" SG_ 1495 IHVSLF_VntAuto "ENM";
BA_ "SignalLongName" SG_ 1495 IHVSLF_VntAuto "Indication Heated Vented Seat Left Front : Vented Auto";
BA_ "SignalType" SG_ 1495 IHVSLF_HtdCushBckMd "ENM";
BA_ "SignalLongName" SG_ 1495 IHVSLF_HtdCushBckMd "Indication Heated Vented Seat Left Front : Heated Cushion and Back Mode";
BA_ "SignalType" SG_ 1495 IHVSLF_HtdCushBckLvl3 "ENM";
BA_ "SignalLongName" SG_ 1495 IHVSLF_HtdCushBckLvl3 "Indication Heated Vented Seat Left Front : Heated Cushion and Back Level 3";
BA_ "SignalType" SG_ 1495 IHVSRF_HtdCushBckLvl3 "ENM";
BA_ "SignalLongName" SG_ 1495 IHVSRF_HtdCushBckLvl3 "Indication Heated Vented Seat Right Front : Heated Cushion and Back Level 3";
BA_ "SignalType" SG_ 1495 IHVSRF_HtdCushBckLvl2 "ENM";
BA_ "SignalLongName" SG_ 1495 IHVSRF_HtdCushBckLvl2 "Indication Heated Vented Seat Right Front : Heated Cushion and Back Level 2";
BA_ "SignalType" SG_ 1495 IHVSRF_HtdCushBckLvl1 "ENM";
BA_ "SignalLongName" SG_ 1495 IHVSRF_HtdCushBckLvl1 "Indication Heated Vented Seat Right Front : Heated Cushion and Back Level 1";
BA_ "SignalType" SG_ 1495 IHVSRF_HtdCushBckAuto "ENM";
BA_ "SignalLongName" SG_ 1495 IHVSRF_HtdCushBckAuto "Indication Heated Vented Seat Right Front : Heated Cushion and Back Auto";
BA_ "SignalType" SG_ 1495 IHVSRF_HtdBckMd "ENM";
BA_ "SignalLongName" SG_ 1495 IHVSRF_HtdBckMd "Indication Heated Vented Seat Right Front : Heated Back Mode";
BA_ "SignalType" SG_ 1495 IHVSRF_HtdBckLvl3 "ENM";
BA_ "SignalLongName" SG_ 1495 IHVSRF_HtdBckLvl3 "Indication Heated Vented Seat Right Front : Heated Back Level 3";
BA_ "SignalType" SG_ 1495 IHVSRF_HtdBckLvl2 "ENM";
BA_ "SignalLongName" SG_ 1495 IHVSRF_HtdBckLvl2 "Indication Heated Vented Seat Right Front : Heated Back Level 2";
BA_ "SignalType" SG_ 1495 IHVSRF_HtdBckLvl1 "ENM";
BA_ "SignalLongName" SG_ 1495 IHVSRF_HtdBckLvl1 "Indication Heated Vented Seat Right Front : Heated Back Level 1";
BA_ "SignalType" SG_ 1495 IntDimSeldClrTypStVal "ENM";
BA_ "SignalLongName" SG_ 1495 IntDimSeldClrTypStVal "Interior Dimming Selected Color Type Setting Value";
BA_ "SignalType" SG_ 1495 IHVSRF_VntMd "ENM";
BA_ "SignalLongName" SG_ 1495 IHVSRF_VntMd "Indication Heated Vented Seat Right Front : Vented Mode";
BA_ "SignalType" SG_ 1495 IHVSRF_VntLvl3 "ENM";
BA_ "SignalLongName" SG_ 1495 IHVSRF_VntLvl3 "Indication Heated Vented Seat Right Front : Vented Level 3";
BA_ "SignalType" SG_ 1495 IHVSRF_VntLvl2 "ENM";
BA_ "SignalLongName" SG_ 1495 IHVSRF_VntLvl2 "Indication Heated Vented Seat Right Front : Vented Level 2";
BA_ "SignalType" SG_ 1495 IHVSRF_VntLvl1 "ENM";
BA_ "SignalLongName" SG_ 1495 IHVSRF_VntLvl1 "Indication Heated Vented Seat Right Front : Vented Level 1";
BA_ "SignalType" SG_ 1495 IHVSRF_VntAuto "ENM";
BA_ "SignalLongName" SG_ 1495 IHVSRF_VntAuto "Indication Heated Vented Seat Right Front : Vented Auto";
BA_ "SignalType" SG_ 1495 IHVSRF_HtdCushBckMd "ENM";
BA_ "SignalLongName" SG_ 1495 IHVSRF_HtdCushBckMd "Indication Heated Vented Seat Right Front : Heated Cushion and Back Mode";
BA_ "SignalType" SG_ 1495 AutUnlckCstCurSetVal "ENM";
BA_ "SignalLongName" SG_ 1495 AutUnlckCstCurSetVal "AutomaticUnlockingCustomizationCurrentSettingValue";
BA_ "SignalType" SG_ 1495 IntDimSeldAnmTypStVal "ENM";
BA_ "SignalLongName" SG_ 1495 IntDimSeldAnmTypStVal "Interior Dimming Selected Animation Type Setting Value";
BA_ "SignalType" SG_ 1495 ExtLghtCstCurSetVal "ENM";
BA_ "SignalLongName" SG_ 1495 ExtLghtCstCurSetVal "Exit Lighting CustomizationCurrentSettingValue";
BA_ "SignalType" SG_ 1495 DaytimeTlLghtsCstCurSetVal "ENM";
BA_ "SignalLongName" SG_ 1495 DaytimeTlLghtsCstCurSetVal "DaytimeTailLightsCustomizationCurrentSettingValue";
BA_ "SignalType" SG_ 1495 CurbVwFtrActvReq "ENM";
BA_ "SignalLongName" SG_ 1495 CurbVwFtrActvReq "Curb View Feature Active Request";
BA_ "SignalType" SG_ 1495 IonzrCtrlCstCrStVal "ENM";
BA_ "SignalLongName" SG_ 1495 IonzrCtrlCstCrStVal "Ionizer Control Customization Current Setting Value";
BA_ "SignalType" SG_ 1495 HFRCCstCurSetVal "ENM";
BA_ "SignalLongName" SG_ 1495 HFRCCstCurSetVal "HandsFreeRearClosureCustomizationCurrentSettingValue";
BA_ "SignalType" SG_ 1495 IonzrCtrlCstStAvl "ENM";
BA_ "SignalLongName" SG_ 1495 IonzrCtrlCstStAvl "Ionizer Control Customization Setting Available";
BA_ "SignalType" SG_ 1495 HFRCCstStAvl "ENM";
BA_ "SignalLongName" SG_ 1495 HFRCCstStAvl "HandsFreeRearClosureCustomizationSettingAvailable";
BA_ "SignalType" SG_ 1495 ExtLghtCstStAvl "ENM";
BA_ "SignalLongName" SG_ 1495 ExtLghtCstStAvl "Exit Lighting CustomizationSettingAvailable";
BA_ "SignalType" SG_ 1495 DaytimeTlLghtsCstStAvl "ENM";
BA_ "SignalLongName" SG_ 1495 DaytimeTlLghtsCstStAvl "DaytimeTailLightsCustomizationSettingAvailable";
BA_ "SignalType" SG_ 1495 CrsCntCncRq "ENM";
BA_ "SignalLongName" SG_ 1495 CrsCntCncRq "Cruise Control Cancel Request";
BA_ "SignalType" SG_ 1495 AutUnlckCstStAvl "ENM";
BA_ "SignalLongName" SG_ 1495 AutUnlckCstStAvl "AutomaticUnlockingCustomizationSettingAvailable";
BA_ "SignalLongName" SG_ 1177 PCOSN_NtfnEvntSyncCnt "Post Collision OnStar Notification : Notification Event Sync Counter";
BA_ "SignalType" SG_ 1177 PCOSN_NtfnDrvrStBltSts "ENM";
BA_ "SignalLongName" SG_ 1177 PCOSN_NtfnDrvrStBltSts "Post Collision OnStar Notification : Notification Driver Seat Belt Status";
BA_ "SignalType" SG_ 1177 PCOSN_NtfnImpDeltVelTxSts "ENM";
BA_ "SignalLongName" SG_ 1177 PCOSN_NtfnImpDeltVelTxSts "Post Collision OnStar Notification : Notification Impact Delta Velocity Transmit Status";
BA_ "SignalType" SG_ 1177 PCOSN_NtfnFrstPsngrStOccpSts "ENM";
BA_ "SignalLongName" SG_ 1177 PCOSN_NtfnFrstPsngrStOccpSts "Post Collision OnStar Notification : Notification Front Passenger Seat Occupancy Status";
BA_ "SignalType" SG_ 1177 PCOSN_NtfnFrstPsngrStBltSts "ENM";
BA_ "SignalLongName" SG_ 1177 PCOSN_NtfnFrstPsngrStBltSts "Post Collision OnStar Notification : Notification Front Passenger Seat Belt Status";
BA_ "SignalLongName" SG_ 1177 PCOSN_NtfnImpMaxLatDeltVel "Post Collision OnStar Notification : Notification Impact Maximum Lateral Delta Velocity";
BA_ "SignalLongName" SG_ 1177 PCOSN_NtfnImpMaxLongDeltVel "Post Collision OnStar Notification : Notification Impact Maximum Longitudinal Delta Velocity";
BA_ "SignalType" SG_ 1177 PCOSN_NtfnSecRowLtStOccpSts "ENM";
BA_ "SignalLongName" SG_ 1177 PCOSN_NtfnSecRowLtStOccpSts "Post Collision OnStar Notification : Notification Second Row Left Seat Occupancy Status";
BA_ "SignalType" SG_ 1177 PCOSN_NtfnSecRowLtStBltSts "ENM";
BA_ "SignalLongName" SG_ 1177 PCOSN_NtfnSecRowLtStBltSts "Post Collision OnStar Notification : Notification Second Row Left Seat Belt Status";
BA_ "SignalType" SG_ 1177 PCOSN_NtfnSecRowCntrStOccpSts "ENM";
BA_ "SignalLongName" SG_ 1177 PCOSN_NtfnSecRowCntrStOccpSts "Post Collision OnStar Notification : Notification Second Row Center Seat Occupancy Status";
BA_ "SignalType" SG_ 1177 PCOSN_NtfnSecRowCntrStBltSts "ENM";
BA_ "SignalLongName" SG_ 1177 PCOSN_NtfnSecRowCntrStBltSts "Post Collision OnStar Notification : Notification Second Row Center Seat Belt Status";
BA_ "SignalType" SG_ 1177 PCOSN_NtfnThrdRowCntrStOccpSts "ENM";
BA_ "SignalLongName" SG_ 1177 PCOSN_NtfnThrdRowCntrStOccpSts "Post Collision OnStar Notification : Notification Third Row Center Seat Occupancy Status";
BA_ "SignalType" SG_ 1177 PCOSN_NtfnThrdRowCntrStBltSts "ENM";
BA_ "SignalLongName" SG_ 1177 PCOSN_NtfnThrdRowCntrStBltSts "Post Collision OnStar Notification : Notification Third Row Center Seat Belt Status";
BA_ "SignalType" SG_ 1177 PCOSN_NtfnSecRowRtStOccpSts "ENM";
BA_ "SignalLongName" SG_ 1177 PCOSN_NtfnSecRowRtStOccpSts "Post Collision OnStar Notification : Notification Second Row Right Seat Occupancy Status";
BA_ "SignalType" SG_ 1177 PCOSN_NtfnSecRowRtStBltSts "ENM";
BA_ "SignalLongName" SG_ 1177 PCOSN_NtfnSecRowRtStBltSts "Post Collision OnStar Notification : Notification Second Row Right Seat Belt Status";
BA_ "SignalType" SG_ 1177 PCOSN_NtfnThrdRowRtStOccpSts "ENM";
BA_ "SignalLongName" SG_ 1177 PCOSN_NtfnThrdRowRtStOccpSts "Post Collision OnStar Notification : Notification Third Row Right Seat Occupancy Status";
BA_ "SignalType" SG_ 1177 PCOSN_NtfnThrdRowRtStBltSts "ENM";
BA_ "SignalLongName" SG_ 1177 PCOSN_NtfnThrdRowRtStBltSts "Post Collision OnStar Notification : Notification Third Row Right Seat Belt Status";
BA_ "SignalType" SG_ 1177 PCOSN_NtfnThrdRowLtStOccpSts "ENM";
BA_ "SignalLongName" SG_ 1177 PCOSN_NtfnThrdRowLtStOccpSts "Post Collision OnStar Notification : Notification Third Row Left Seat Occupancy Status";
BA_ "SignalType" SG_ 1177 PCOSN_NtfnThrdRowLtStBltSts "ENM";
BA_ "SignalLongName" SG_ 1177 PCOSN_NtfnThrdRowLtStBltSts "Post Collision OnStar Notification : Notification Third Row Left Seat Belt Status";
BA_ "SignalType" SG_ 1177 PCOSN_NtfnFrstRowCntrStOccpSts "ENM";
BA_ "SignalLongName" SG_ 1177 PCOSN_NtfnFrstRowCntrStOccpSts "Post Collision OnStar Notification : Notification First Row Center Seat Occupancy Status";
BA_ "SignalType" SG_ 1177 PCOSN_NtfnFrstRowCntrStBtSts "ENM";
BA_ "SignalLongName" SG_ 1177 PCOSN_NtfnFrstRowCntrStBtSts "Post Collision OnStar Notification : Notification First Row Center Seatbelt Status";
BA_ "SignalType" SG_ 1177 PCOSN_NtfnDrvrStOccpSts "ENM";
BA_ "SignalLongName" SG_ 1177 PCOSN_NtfnDrvrStOccpSts "Post Collision OnStar Notification : Notification Driver Seat Occupancy Status";
BA_ "SignalType" SG_ 1500 DM1Unavailable "ENM";
BA_ "SignalLongName" SG_ 1500 DM1Unavailable "Drive Mode Information : Drive Mode 1 Unavailable";
BA_ "SignalType" SG_ 1500 DM1Status "ENM";
BA_ "SignalLongName" SG_ 1500 DM1Status "Drive Mode Information : Drive Mode 1 Status";
BA_ "SignalType" SG_ 1500 DM1Pending "ENM";
BA_ "SignalLongName" SG_ 1500 DM1Pending "Drive Mode Information : Drive Mode 1 Pending";
BA_ "SignalType" SG_ 1500 DM1Name "ENM";
BA_ "SignalLongName" SG_ 1500 DM1Name "Drive Mode Information : Drive Mode 1 Name";
BA_ "SignalType" SG_ 1500 DM2Unavailable "ENM";
BA_ "SignalLongName" SG_ 1500 DM2Unavailable "Drive Mode Information : Drive Mode 2 Unavailable";
BA_ "SignalType" SG_ 1500 DM2Status "ENM";
BA_ "SignalLongName" SG_ 1500 DM2Status "Drive Mode Information : Drive Mode 2 Status";
BA_ "SignalType" SG_ 1500 DM2Pending "ENM";
BA_ "SignalLongName" SG_ 1500 DM2Pending "Drive Mode Information : Drive Mode 2 Pending";
BA_ "SignalType" SG_ 1500 DM2Name "ENM";
BA_ "SignalLongName" SG_ 1500 DM2Name "Drive Mode Information : Drive Mode 2 Name";
BA_ "SignalType" SG_ 1500 DM3Unavailable "ENM";
BA_ "SignalLongName" SG_ 1500 DM3Unavailable "Drive Mode Information : Drive Mode 3 Unavailable";
BA_ "SignalType" SG_ 1500 DM3Status "ENM";
BA_ "SignalLongName" SG_ 1500 DM3Status "Drive Mode Information : Drive Mode 3 Status";
BA_ "SignalType" SG_ 1500 DM3Pending "ENM";
BA_ "SignalLongName" SG_ 1500 DM3Pending "Drive Mode Information : Drive Mode 3 Pending";
BA_ "SignalType" SG_ 1500 DM3Name "ENM";
BA_ "SignalLongName" SG_ 1500 DM3Name "Drive Mode Information : Drive Mode 3 Name";
BA_ "SignalType" SG_ 1500 DM4Unavailable "ENM";
BA_ "SignalLongName" SG_ 1500 DM4Unavailable "Drive Mode Information : Drive Mode 4 Unavailable";
BA_ "SignalType" SG_ 1500 DM4Status "ENM";
BA_ "SignalLongName" SG_ 1500 DM4Status "Drive Mode Information : Drive Mode 4 Status";
BA_ "SignalType" SG_ 1500 DM4Pending "ENM";
BA_ "SignalLongName" SG_ 1500 DM4Pending "Drive Mode Information : Drive Mode 4 Pending";
BA_ "SignalType" SG_ 1500 DM4Name "ENM";
BA_ "SignalLongName" SG_ 1500 DM4Name "Drive Mode Information : Drive Mode 4 Name";
BA_ "SignalType" SG_ 1500 DM5Unavailable "ENM";
BA_ "SignalLongName" SG_ 1500 DM5Unavailable "Drive Mode Information : Drive Mode 5 Unavailable";
BA_ "SignalType" SG_ 1500 DM5Status "ENM";
BA_ "SignalLongName" SG_ 1500 DM5Status "Drive Mode Information : Drive Mode 5 Status";
BA_ "SignalType" SG_ 1500 DM5Pending "ENM";
BA_ "SignalLongName" SG_ 1500 DM5Pending "Drive Mode Information : Drive Mode 5 Pending";
BA_ "SignalType" SG_ 1500 DM5Name "ENM";
BA_ "SignalLongName" SG_ 1500 DM5Name "Drive Mode Information : Drive Mode 5 Name";
BA_ "SignalType" SG_ 1500 DM6Unavailable "ENM";
BA_ "SignalLongName" SG_ 1500 DM6Unavailable "Drive Mode Information : Drive Mode 6 Unavailable";
BA_ "SignalType" SG_ 1500 DM6Status "ENM";
BA_ "SignalLongName" SG_ 1500 DM6Status "Drive Mode Information : Drive Mode 6 Status";
BA_ "SignalType" SG_ 1500 DM6Pending "ENM";
BA_ "SignalLongName" SG_ 1500 DM6Pending "Drive Mode Information : Drive Mode 6 Pending";
BA_ "SignalType" SG_ 1500 DM6Name "ENM";
BA_ "SignalLongName" SG_ 1500 DM6Name "Drive Mode Information : Drive Mode 6 Name";
BA_ "SignalType" SG_ 1500 DM7Unavailable "ENM";
BA_ "SignalLongName" SG_ 1500 DM7Unavailable "Drive Mode Information : Drive Mode 7 Unavailable";
BA_ "SignalType" SG_ 1500 DM7Status "ENM";
BA_ "SignalLongName" SG_ 1500 DM7Status "Drive Mode Information : Drive Mode 7 Status";
BA_ "SignalType" SG_ 1500 DM7Pending "ENM";
BA_ "SignalLongName" SG_ 1500 DM7Pending "Drive Mode Information : Drive Mode 7 Pending";
BA_ "SignalType" SG_ 1500 DM7Name "ENM";
BA_ "SignalLongName" SG_ 1500 DM7Name "Drive Mode Information : Drive Mode 7 Name";
BA_ "SignalType" SG_ 1500 DM8Unavailable "ENM";
BA_ "SignalLongName" SG_ 1500 DM8Unavailable "Drive Mode Information : Drive Mode 8 Unavailable";
BA_ "SignalType" SG_ 1500 DM8Status "ENM";
BA_ "SignalLongName" SG_ 1500 DM8Status "Drive Mode Information : Drive Mode 8 Status";
BA_ "SignalType" SG_ 1500 DM8Pending "ENM";
BA_ "SignalLongName" SG_ 1500 DM8Pending "Drive Mode Information : Drive Mode 8 Pending";
BA_ "SignalType" SG_ 1500 DM8Name "ENM";
BA_ "SignalLongName" SG_ 1500 DM8Name "Drive Mode Information : Drive Mode 8 Name";
BA_ "SignalLongName" SG_ 1464 BatSOCStrtUp "RVC 12V Battery State of Charge at Start Up";
BA_ "SignalType" SG_ 1464 BatLoStrtVehIndOn "ENM";
BA_ "SignalLongName" SG_ 1464 BatLoStrtVehIndOn "Battery Low Start Vehicle Indication On";
BA_ "SignalLongName" SG_ 1464 BatVlt "Battery Voltage";
BA_ "SignalLongName" SG_ 1464 BattCrntFltrd "Battery Current Filtered";
BA_ "SignalType" SG_ 1464 BatVlt_Inv "ENM";
BA_ "SignalLongName" SG_ 1464 BatVlt_Inv "RVC 12V Battery Voltage Invalid";
BA_ "SignalLongName" SG_ 1464 RVC12VBatSOC "RVC 12V Battery State of Charge";
BA_ "SignalType" SG_ 1464 LdShedRdcdFtrsIndOn "ENM";
BA_ "SignalLongName" SG_ 1464 LdShedRdcdFtrsIndOn "Load Shed Reduced Features Indication On";
BA_ "SignalType" SG_ 1464 BattVltIRq "ENM";
BA_ "SignalLongName" SG_ 1464 BattVltIRq "Battery Voltage Indication Request";
BA_ "SignalType" SG_ 1464 RVCBatSOCOver "ENM";
BA_ "SignalLongName" SG_ 1464 RVCBatSOCOver "RVC State of Charge Override";
BA_ "SignalType" SG_ 1464 RVC12VBatSOC_Inv "ENM";
BA_ "SignalLongName" SG_ 1464 RVC12VBatSOC_Inv "RVC 12V Battery Stateof Charge Invalidity";
BA_ "SignalType" SG_ 1464 ServBatChrgSysIndOn "ENM";
BA_ "SignalLongName" SG_ 1464 ServBatChrgSysIndOn "Service Battery Charging System Indication On";
BA_ "SignalType" SG_ 1112 ACCCSV_Aux3Colr "ENM";
BA_ "SignalLongName" SG_ 1112 ACCCSV_Aux3Colr "Ambient Control Customization Current Setting Value Extended : Ambient Control Customization Current Setting Value Auxiliary 3 Color";
BA_ "SignalType" SG_ 1112 ACCCSV_Aux2Colr "ENM";
BA_ "SignalLongName" SG_ 1112 ACCCSV_Aux2Colr "Ambient Control Customization Current Setting Value Extended : Ambient Control Customization Current Setting Value Auxiliary 2 Color";
BA_ "SignalType" SG_ 1112 ACCCSV_Aux2Anm "ENM";
BA_ "SignalLongName" SG_ 1112 ACCCSV_Aux2Anm "Ambient Control Customization Current Setting Value Extended : Ambient Control Customization Current Setting Value Auxiliary 2 Animation";
BA_ "SignalType" SG_ 1112 ACCCSV_Aux2Brghtns "ENM";
BA_ "SignalLongName" SG_ 1112 ACCCSV_Aux2Brghtns "Ambient Control Customization Current Setting Value Extended : Ambient Control Customization Current Setting Value Auxiliary 2 Brightness";
BA_ "SignalType" SG_ 1112 ACCCSV_Aux3Anm "ENM";
BA_ "SignalLongName" SG_ 1112 ACCCSV_Aux3Anm "Ambient Control Customization Current Setting Value Extended : Ambient Control Customization Current Setting Value Auxiliary 3 Animation";
BA_ "SignalType" SG_ 1112 FrtSnshdActlPstn "ENM";
BA_ "SignalLongName" SG_ 1112 FrtSnshdActlPstn "Front Sunshade Actual Position";
BA_ "SignalType" SG_ 1112 ACCCSV_Aux3Brghtns "ENM";
BA_ "SignalLongName" SG_ 1112 ACCCSV_Aux3Brghtns "Ambient Control Customization Current Setting Value Extended : Ambient Control Customization Current Setting Value Auxiliary 3 Brightness";
BA_ "SignalLongName" SG_ 1112 WndPstnLR "Window Position Left Rear Information : Window Position Left Rear";
BA_ "SignalType" SG_ 1112 WndPstnLF_Inv "ENM";
BA_ "SignalLongName" SG_ 1112 WndPstnLF_Inv "Window Position Left Front Information : Window Position Left Front Invalid";
BA_ "SignalLongName" SG_ 1112 WndPstnLF "Window Position Left Front Information : Window Position Left Front";
BA_ "SignalLongName" SG_ 1112 WndPstnRF "Window Position Right Front Information : Window Position Right Front";
BA_ "SignalType" SG_ 1112 WndPstnLR_Inv "ENM";
BA_ "SignalLongName" SG_ 1112 WndPstnLR_Inv "Window Position Left Rear Information : Window Position Left Rear Invalid";
BA_ "SignalLongName" SG_ 1112 WndPstnRR "Window Position Right Rear Information : Window Position Right Rear";
BA_ "SignalType" SG_ 1112 WndPstnRF_Inv "ENM";
BA_ "SignalLongName" SG_ 1112 WndPstnRF_Inv "Window Position Right Front Information : Window Position Right Front Invalid";
BA_ "SignalType" SG_ 1112 WndPstnRR_Inv "ENM";
BA_ "SignalLongName" SG_ 1112 WndPstnRR_Inv "Window Position Right Rear Information : Window Position Right Rear Invalid";
BA_ "SignalLongName" SG_ 1968 HiVltgBatBatTypCodGtd "High Voltage Battery Manufacturing Information Gated : High Voltage Battery Battery Type Code Gated";
BA_ "SignalLongName" SG_ 1968 HiVltgBatMfrCodGtd "High Voltage Battery Manufacturing Information Gated : High Voltage Battery Manufacturer Code Gated";
BA_ "SignalLongName" SG_ 1968 HiVltgBatProdTypCodGtd "High Voltage Battery Manufacturing Information Gated : High Voltage Battery Product Type Code Gated";
BA_ "SignalLongName" SG_ 1968 HiVltgBatSpecCodGtd "High Voltage Battery Manufacturing Information Gated : High Voltage Battery Specification Code Gated";
BA_ "SignalType" SG_ 1968 VehMonSrvrRtryFreq_Inv "ENM";
BA_ "SignalLongName" SG_ 1968 VehMonSrvrRtryFreq_Inv "VDM Server Retries Frequency Information : Vehicle Monitor Server Retries Frequency Invalid";
BA_ "SignalLongName" SG_ 1968 VehMonSrvrRtryFreq "VDM Server Retries Frequency Information : Vehicle Monitor Server Retries Frequency";
BA_ "SignalLongName" SG_ 1098 HiVltgBatSrlNumGtd "High Voltage Battery Serial Number Gated";
BA_ "SignalType" SG_ 1098 VehMonDatRcrdMaxBytes_Inv "ENM";
BA_ "SignalLongName" SG_ 1098 VehMonDatRcrdMaxBytes_Inv "VDM Data Record Maximum Bytes Information : Vehicle Monitor Data Record Maximum Bytes Invalid";
BA_ "SignalLongName" SG_ 1098 VehMonDatRcrdMaxBytes "VDM Data Record Maximum Bytes Information : Vehicle Monitor Data Record Maximum Bytes";
BA_ "SignalLongName" SG_ 1969 HiVltgBatTrcbltyInfoCodGtd "High Voltage Battery Traceability Information Code Gated";
BA_ "SignalType" SG_ 1969 VehMonFreqLvl3AftDatRcrdsRqrd_In "ENM";
BA_ "SignalLongName" SG_ 1969 VehMonFreqLvl3AftDatRcrdsRqrd_In "VDM Frequency of Level 3 After Data Records Information : Vehicle Monitor Frequency of Level 3 After Data Records Required Invalid";
BA_ "SignalLongName" SG_ 1969 VehMonFreqLvl3AftDatRcrdsRqrd "VDM Frequency of Level 3 After Data Records Information : Vehicle Monitor Frequency of Level 3 After Data Records Required";
BA_ "SignalLongName" SG_ 1097 HiVltgBatProdDyCodGtd "High Voltage Battery Production Date Code Gated : High Voltage Battery Production Day Code Gated";
BA_ "SignalLongName" SG_ 1097 HiVltgBatProdMthCodGtd "High Voltage Battery Production Date Code Gated : High Voltage Battery Production Month Code Gated";
BA_ "SignalLongName" SG_ 1097 HiVltgBatProdYrCodGtd "High Voltage Battery Production Date Code Gated : High Voltage Battery Production Year Code Gated";
BA_ "SignalLongName" SG_ 1097 HiVltgBatSecUseCodGtd "High Voltage Battery Secondary Use Code Gated";
BA_ "SignalLongName" SG_ 1097 HiVltgBatCodLgth "High Voltage Battery Code Length";
BA_ "SignalLongName" SG_ 1097 VehMonFreqLvl3BfrDatRcrdsRqrd "VDM Frequency of Level 3 Before Data Records Information : Vehicle Monitor Frequency of Level 3 Before Data Records Required";
BA_ "SignalLongName" SG_ 1097 VehMonDatStrgeMaxDys "VDM Data Storage Maximum Days Information : Vehicle Monitor Data Storage Maximum Days";
BA_ "SignalType" SG_ 1097 VehMonLossPwrTmRqrd_Inv "ENM";
BA_ "SignalLongName" SG_ 1097 VehMonLossPwrTmRqrd_Inv "VDM Loss of Power Time Required Information : Vehicle Monitor Loss of Power Time Required Invalid";
BA_ "SignalType" SG_ 1097 VehMonFreqLvl3BfrDatRcrdsRqrd_In "ENM";
BA_ "SignalLongName" SG_ 1097 VehMonFreqLvl3BfrDatRcrdsRqrd_In "VDM Frequency of Level 3 Before Data Records Information : Vehicle Monitor Frequency of Level 3 Before Data Records Required Invalid";
BA_ "SignalType" SG_ 1097 VehMonDatStrgeMaxDys_Inv "ENM";
BA_ "SignalLongName" SG_ 1097 VehMonDatStrgeMaxDys_Inv "VDM Data Storage Maximum Days Information : Vehicle Monitor Data Storage Maximum Days Invalid";
BA_ "SignalLongName" SG_ 1097 VehMonLossPwrTmRqrd "VDM Loss of Power Time Required Information : Vehicle Monitor Loss of Power Time Required";
BA_ "SignalLongName" SG_ 1970 VehMonSrvrRtryCnt "VDM Server Retries Count Information : Vehicle Monitor Server Retries Count";
BA_ "SignalType" SG_ 1970 VehMonNonLvl3DatFreq_Inv "ENM";
BA_ "SignalLongName" SG_ 1970 VehMonNonLvl3DatFreq_Inv "VDM Non Level 3 Data Frequency Information : Vehicle Monitor Non Level 3 Data Frequency Invalid";
BA_ "SignalLongName" SG_ 1970 VehMonNonLvl3DatFreq "VDM Non Level 3 Data Frequency Information : Vehicle Monitor Non Level 3 Data Frequency";
BA_ "SignalLongName" SG_ 1970 HiVltgBatQnty "High Voltage Battery Quantity";
BA_ "SignalType" SG_ 1970 VehMonLvl3DatFreq_Inv "ENM";
BA_ "SignalLongName" SG_ 1970 VehMonLvl3DatFreq_Inv "VDM Level 3 Data Frequency Information : Vehicle Monitor Level 3 Data Frequency Invalid";
BA_ "SignalLongName" SG_ 1970 VehMonLvl3DatFreq "VDM Level 3 Data Frequency Information : Vehicle Monitor Level 3 Data Frequency";
BA_ "SignalType" SG_ 1970 VehMonSrvrRtryCnt_Inv "ENM";
BA_ "SignalLongName" SG_ 1970 VehMonSrvrRtryCnt_Inv "VDM Server Retries Count Information : Vehicle Monitor Server Retries Count Invalid";
BA_ "SignalType" SG_ 1970 VehMonSrvrConctSeltn_Inv "ENM";
BA_ "SignalLongName" SG_ 1970 VehMonSrvrConctSeltn_Inv "VDM Server Connection Selection Information : Vehicle Monitor Server Connection Selection Invalid";
BA_ "SignalType" SG_ 1970 VehMonSrvrConctSeltn "ENM";
BA_ "SignalLongName" SG_ 1970 VehMonSrvrConctSeltn "VDM Server Connection Selection Information : Vehicle Monitor Server Connection Selection";
BA_ "SignalLongName" SG_ 663 WkupCadenceMult "Off Power Mode Load Management Battery Information : Wakeup Cadence Multiplier";
BA_ "SignalLongName" SG_ 663 SyncTmrVal "Off Power Mode Load Management Battery Information : Synchronized Timer Value";
BA_ "SignalType" SG_ 663 SyncTmrVal_Inv "ENM";
BA_ "SignalLongName" SG_ 663 SyncTmrVal_Inv "Off Power Mode Load Management Battery Information : Synchronized Timer Value Invalid";
BA_ "SignalType" SG_ 663 FtrMinPrtyAllwd_Inv "ENM";
BA_ "SignalLongName" SG_ 663 FtrMinPrtyAllwd_Inv "Off Power Mode Load Management Battery Information : Feature Minimum Priority Allowed Invalid";
BA_ "SignalLongName" SG_ 663 FtrMinPrtyAllwd "Off Power Mode Load Management Battery Information : Feature Minimum Priority Allowed";
BA_ "SignalType" SG_ 663 WkupCadenceMult_Inv "ENM";
BA_ "SignalLongName" SG_ 663 WkupCadenceMult_Inv "Off Power Mode Load Management Battery Information : Wakeup Cadence Multiplier Invalid";
VAL_ 1186 TrlrTireLtMdlPres_Inv 0 "FALSE" 1 "TRUE" ;
VAL_ 1186 TrlrTireLRTemp_Inv 0 "FALSE" 1 "TRUE" ;
VAL_ 1186 TrlrTireLtMdlTemp_Inv 0 "FALSE" 1 "TRUE" ;
VAL_ 1186 TrlrTirePresSysFaild 0 "FALSE" 1 "TRUE" ;
VAL_ 1186 TrlrTirePresFtrEnbld 0 "FALSE" 1 "TRUE" ;
VAL_ 1186 TrlrTireRFPresSts 0 "Unknown" 1 "Normal" 2 "Low Pressure" 3 "Malfunction" 4 "Learning in Progress" 5 "Learn Tire" 6 "Tire Learning Complete" 7 "High Pressure" 8 "High Temperature" ;
VAL_ 1186 TrlrTireRFPresSts_Inv 0 "FALSE" 1 "TRUE" ;
VAL_ 1889 WlkAwyLckCstAvlFlg1 0 "FALSE" 1 "TRUE" ;
VAL_ 1889 VehLctrLghtsCstAvlFlg7 0 "FALSE" 1 "TRUE" ;
VAL_ 1889 VehLctrLghtsCstAvlFlg6 0 "FALSE" 1 "TRUE" ;
VAL_ 1889 VehLctrLghtsCstAvlFlg5 0 "FALSE" 1 "TRUE" ;
VAL_ 1889 VehLctrLghtsCstAvlFlg4 0 "FALSE" 1 "TRUE" ;
VAL_ 1889 VehLctrLghtsCstAvlFlg3 0 "FALSE" 1 "TRUE" ;
VAL_ 1889 VehLctrLghtsCstAvlFlg2 0 "FALSE" 1 "TRUE" ;
VAL_ 1889 VehLctrLghtsCstAvlFlg1 0 "FALSE" 1 "TRUE" ;
VAL_ 1889 AmbtLgtGblPrxmtyEnCstAvlFlg2 0 "FALSE" 1 "TRUE" ;
VAL_ 1889 AmbtLgtGblPrxmtyEnCstAvlFlg1 0 "FALSE" 1 "TRUE" ;
VAL_ 1889 WlkAwyLckCstAvlFlg7 0 "FALSE" 1 "TRUE" ;
VAL_ 1889 WlkAwyLckCstAvlFlg6 0 "FALSE" 1 "TRUE" ;
VAL_ 1889 WlkAwyLckCstAvlFlg5 0 "FALSE" 1 "TRUE" ;
VAL_ 1889 WlkAwyLckCstAvlFlg4 0 "FALSE" 1 "TRUE" ;
VAL_ 1889 WlkAwyLckCstAvlFlg3 0 "FALSE" 1 "TRUE" ;
VAL_ 1889 WlkAwyLckCstAvlFlg2 0 "FALSE" 1 "TRUE" ;
VAL_ 1889 Aux1AmbtColrCtlCstAvlFlg33 0 "FALSE" 1 "TRUE" ;
VAL_ 1889 Aux1AmbtColrCtlCstAvlFlg32 0 "FALSE" 1 "TRUE" ;
VAL_ 1889 AmbtLgtGblPrxmtyEnCstSetAval 0 "FALSE" 1 "TRUE" ;
VAL_ 1889 AmbtLgtGblPrxmtyEnCstAvlFlg7 0 "FALSE" 1 "TRUE" ;
VAL_ 1889 AmbtLgtGblPrxmtyEnCstAvlFlg6 0 "FALSE" 1 "TRUE" ;
VAL_ 1889 AmbtLgtGblPrxmtyEnCstAvlFlg5 0 "FALSE" 1 "TRUE" ;
VAL_ 1889 AmbtLgtGblPrxmtyEnCstAvlFlg4 0 "FALSE" 1 "TRUE" ;
VAL_ 1889 AmbtLgtGblPrxmtyEnCstAvlFlg3 0 "FALSE" 1 "TRUE" ;
VAL_ 1889 Aux1AmbtColrCtlCstAvlFlg41 0 "FALSE" 1 "TRUE" ;
VAL_ 1889 Aux1AmbtColrCtlCstAvlFlg40 0 "FALSE" 1 "TRUE" ;
VAL_ 1889 Aux1AmbtColrCtlCstAvlFlg39 0 "FALSE" 1 "TRUE" ;
VAL_ 1889 Aux1AmbtColrCtlCstAvlFlg38 0 "FALSE" 1 "TRUE" ;
VAL_ 1889 Aux1AmbtColrCtlCstAvlFlg37 0 "FALSE" 1 "TRUE" ;
VAL_ 1889 Aux1AmbtColrCtlCstAvlFlg36 0 "FALSE" 1 "TRUE" ;
VAL_ 1889 Aux1AmbtColrCtlCstAvlFlg35 0 "FALSE" 1 "TRUE" ;
VAL_ 1889 Aux1AmbtColrCtlCstAvlFlg34 0 "FALSE" 1 "TRUE" ;
VAL_ 1889 Aux1AmbtColrCtlCstAvlFlg49 0 "FALSE" 1 "TRUE" ;
VAL_ 1889 Aux1AmbtColrCtlCstAvlFlg48 0 "FALSE" 1 "TRUE" ;
VAL_ 1889 Aux1AmbtColrCtlCstAvlFlg47 0 "FALSE" 1 "TRUE" ;
VAL_ 1889 Aux1AmbtColrCtlCstAvlFlg46 0 "FALSE" 1 "TRUE" ;
VAL_ 1889 Aux1AmbtColrCtlCstAvlFlg45 0 "FALSE" 1 "TRUE" ;
VAL_ 1889 Aux1AmbtColrCtlCstAvlFlg44 0 "FALSE" 1 "TRUE" ;
VAL_ 1889 Aux1AmbtColrCtlCstAvlFlg43 0 "FALSE" 1 "TRUE" ;
VAL_ 1889 Aux1AmbtColrCtlCstAvlFlg42 0 "FALSE" 1 "TRUE" ;
VAL_ 1889 Aux1AmbtColrCtlCstAvlFlg57 0 "FALSE" 1 "TRUE" ;
VAL_ 1889 Aux1AmbtColrCtlCstAvlFlg56 0 "FALSE" 1 "TRUE" ;
VAL_ 1889 Aux1AmbtColrCtlCstAvlFlg55 0 "FALSE" 1 "TRUE" ;
VAL_ 1889 Aux1AmbtColrCtlCstAvlFlg54 0 "FALSE" 1 "TRUE" ;
VAL_ 1889 Aux1AmbtColrCtlCstAvlFlg53 0 "FALSE" 1 "TRUE" ;
VAL_ 1889 Aux1AmbtColrCtlCstAvlFlg52 0 "FALSE" 1 "TRUE" ;
VAL_ 1889 Aux1AmbtColrCtlCstAvlFlg51 0 "FALSE" 1 "TRUE" ;
VAL_ 1889 Aux1AmbtColrCtlCstAvlFlg50 0 "FALSE" 1 "TRUE" ;
VAL_ 1889 Aux1AmbtColrCtlCstAvlFlg65 0 "FALSE" 1 "TRUE" ;
VAL_ 1889 Aux1AmbtColrCtlCstAvlFlg64 0 "FALSE" 1 "TRUE" ;
VAL_ 1889 Aux1AmbtColrCtlCstAvlFlg63 0 "FALSE" 1 "TRUE" ;
VAL_ 1889 Aux1AmbtColrCtlCstAvlFlg62 0 "FALSE" 1 "TRUE" ;
VAL_ 1889 Aux1AmbtColrCtlCstAvlFlg61 0 "FALSE" 1 "TRUE" ;
VAL_ 1889 Aux1AmbtColrCtlCstAvlFlg60 0 "FALSE" 1 "TRUE" ;
VAL_ 1889 Aux1AmbtColrCtlCstAvlFlg59 0 "FALSE" 1 "TRUE" ;
VAL_ 1889 Aux1AmbtColrCtlCstAvlFlg58 0 "FALSE" 1 "TRUE" ;
VAL_ 1889 Aux1AmbtColrCtlCstAvlFlg73 0 "FALSE" 1 "TRUE" ;
VAL_ 1889 Aux1AmbtColrCtlCstAvlFlg72 0 "FALSE" 1 "TRUE" ;
VAL_ 1889 Aux1AmbtColrCtlCstAvlFlg71 0 "FALSE" 1 "TRUE" ;
VAL_ 1889 Aux1AmbtColrCtlCstAvlFlg70 0 "FALSE" 1 "TRUE" ;
VAL_ 1889 Aux1AmbtColrCtlCstAvlFlg69 0 "FALSE" 1 "TRUE" ;
VAL_ 1889 Aux1AmbtColrCtlCstAvlFlg68 0 "FALSE" 1 "TRUE" ;
VAL_ 1889 Aux1AmbtColrCtlCstAvlFlg67 0 "FALSE" 1 "TRUE" ;
VAL_ 1889 Aux1AmbtColrCtlCstAvlFlg66 0 "FALSE" 1 "TRUE" ;
VAL_ 1881 TrlrTireRFPres_Inv 0 "FALSE" 1 "TRUE" ;
VAL_ 1881 TrlrTireRRPres_Inv 0 "FALSE" 1 "TRUE" ;
VAL_ 1881 TrlrTireRtMdlPres_Inv 0 "FALSE" 1 "TRUE" ;
VAL_ 1881 TrlrTireRFTemp_Inv 0 "FALSE" 1 "TRUE" ;
VAL_ 1881 TrlrTireRRTemp_Inv 0 "FALSE" 1 "TRUE" ;
VAL_ 1881 TrlrTireRtMdlTemp_Inv 0 "FALSE" 1 "TRUE" ;
VAL_ 1881 TrlrTireRRPresSts 0 "Unknown" 1 "Normal" 2 "Low Pressure" 3 "Malfunction" 4 "Learning in Progress" 5 "Learn Tire" 6 "Tire Learning Complete" 7 "High Pressure" 8 "High Temperature" ;
VAL_ 1881 TrlrTireRRPresSts_Inv 0 "FALSE" 1 "TRUE" ;
VAL_ 1881 Aux1AmbtColrCtlCstAvlFlg86 0 "FALSE" 1 "TRUE" ;
VAL_ 1881 Aux1AmbtColrCtlCstAvlFlg85 0 "FALSE" 1 "TRUE" ;
VAL_ 1881 Aux1AmbtColrCtlCstAvlFlg84 0 "FALSE" 1 "TRUE" ;
VAL_ 1881 TrlrTireRtMdlPresSts 0 "Unknown" 1 "Normal" 2 "Low Pressure" 3 "Malfunction" 4 "Learning in Progress" 5 "Learn Tire" 6 "Tire Learning Complete" 7 "High Pressure" 8 "High Temperature" ;
VAL_ 1881 TrlrTireRtMdlPresSts_Inv 0 "FALSE" 1 "TRUE" ;
VAL_ 1184 VCCLS_CrgLmpHtchAval 0 "Not Available" 1 "Available" ;
VAL_ 1184 VCCLS_CrgLmpCurrSeltnVal 0 "Unknown" 1 "On" 2 "Off" ;
VAL_ 1184 VCCLS_CrgLmpAval 0 "Not Available" 1 "Available" ;
VAL_ 1184 VCCLS_CrgBedLmpCurrSeltnVal 0 "Unknown" 1 "On" 2 "Off" ;
VAL_ 1184 VCCLS_CrgBedLmpAval 0 "Not Available" 1 "Available" ;
VAL_ 1184 VCCLS_AllCrgLmpUsrCtlAllwd 0 "Allowed" 1 "Not Allowed" ;
VAL_ 1184 VCDLS_DomeDftCurrSeltnVal 0 "Unknown" 1 "On" 2 "Off" ;
VAL_ 1184 VCDLS_DomeDftAval 0 "Not Available" 1 "Available" ;
VAL_ 1184 VCCLS_CrgMirLmpCurrSeltnVal 0 "Unknown" 1 "On" 2 "Off" ;
VAL_ 1184 VCCLS_CrgMirLmpAval 0 "Not Available" 1 "Available" ;
VAL_ 1184 VCCLS_CrgLmpHtchCurrSeltnVal 0 "Unknown" 1 "On" 2 "Off" ;
VAL_ 1184 VCCSLS_CtlAval 0 "Not Available" 1 "Available" ;
VAL_ 1184 VCAHBS_UsrCtlAllwd 0 "Allowed" 1 "Not Allowed" ;
VAL_ 1184 VCAHBS_CurrSeltnVal 0 "Unknown" 1 "On" 2 "Off" ;
VAL_ 1184 VCAHBS_CtlAval 0 "Not Available" 1 "Available" ;
VAL_ 1184 VCDLS_DomeLgtCurrSeltnVal 0 "Unknown" 1 "On" 2 "Off" ;
VAL_ 1184 VCDLS_DomeLgtAval 0 "Not Available" 1 "Available" ;
VAL_ 1184 VCFLRS_CtlAval 0 "Not Available" 1 "Available" ;
VAL_ 1184 VCFLFS_UsrCtlAllwd 0 "Allowed" 1 "Not Allowed" ;
VAL_ 1184 VCFLFS_CurrSeltnVal 0 "Unknown" 1 "On" 2 "Off" ;
VAL_ 1184 VCFLFS_CtlAval 0 "Not Available" 1 "Available" ;
VAL_ 1184 VCCSLS_MsmtchIndOn 0 "FALSE" 1 "TRUE" ;
VAL_ 1184 VCCSLS_CurrSeltnVal 0 "Unknown" 1 "On" 2 "Off" ;
VAL_ 1184 VCPWLS_CurrSeltnVal 0 "Unknown" 1 "On" 2 "Off" ;
VAL_ 1184 VCPWLS_CtlAval 0 "Not Available" 1 "Available" ;
VAL_ 1184 VCFLRS_UsrCtlAllwd 0 "Allowed" 1 "Not Allowed" ;
VAL_ 1184 VCFLRS_CurrSeltnVal 0 "Unknown" 1 "On" 2 "Off" ;
VAL_ 1184 CbnAirClnFltrtnCstCurrSetVal 0 "Setting Unknown" 1 "Off" 2 "On" ;
VAL_ 1184 AutoNckScrfCstCurrSetVal 0 "Setting Unknown" 1 "Off" 2 "On" 3 "Sync to Heated Seats" ;
VAL_ 1184 AutoAirOtltAmgCstCurrSetVal 0 "Setting Unknown" 1 "Off" 2 "On" ;
VAL_ 1184 FrtClsrAccssVirtCtlAval 0 "Not Available" 1 "Available" ;
VAL_ 1184 FrtClsrAccssVirtCtlAllwd 0 "Not Allowed" 1 "Allowed" ;
VAL_ 1184 DlvryModeWrnIndReq 0 "No Indication" 1 "On" 2 "Off" 3 "Fault" 4 "Keyoff" ;
VAL_ 1412 IHVSLR_HtdCushBckLvl2 0 "FALSE" 1 "TRUE" ;
VAL_ 1412 IHVSLR_HtdCushBckLvl1 0 "FALSE" 1 "TRUE" ;
VAL_ 1412 IHVSLR_HtdCushBckAuto 0 "FALSE" 1 "TRUE" ;
VAL_ 1412 IHVSLR_HtdBckMd 0 "FALSE" 1 "TRUE" ;
VAL_ 1412 IHVSLR_HtdBckLvl3 0 "FALSE" 1 "TRUE" ;
VAL_ 1412 IHVSLR_HtdBckLvl2 0 "FALSE" 1 "TRUE" ;
VAL_ 1412 IHVSLR_HtdBckLvl1 0 "FALSE" 1 "TRUE" ;
VAL_ 1412 IHVSLR_HtdBckAuto 0 "FALSE" 1 "TRUE" ;
VAL_ 1412 IHVSRR_HtdBckAuto 0 "FALSE" 1 "TRUE" ;
VAL_ 1412 IHVSLR_VntMd 0 "FALSE" 1 "TRUE" ;
VAL_ 1412 IHVSLR_VntLvl3 0 "FALSE" 1 "TRUE" ;
VAL_ 1412 IHVSLR_VntLvl2 0 "FALSE" 1 "TRUE" ;
VAL_ 1412 IHVSLR_VntLvl1 0 "FALSE" 1 "TRUE" ;
VAL_ 1412 IHVSLR_VntAuto 0 "FALSE" 1 "TRUE" ;
VAL_ 1412 IHVSLR_HtdCushBckMd 0 "FALSE" 1 "TRUE" ;
VAL_ 1412 IHVSLR_HtdCushBckLvl3 0 "FALSE" 1 "TRUE" ;
VAL_ 1412 IHVSRR_HtdCushBckLvl3 0 "FALSE" 1 "TRUE" ;
VAL_ 1412 IHVSRR_HtdCushBckLvl2 0 "FALSE" 1 "TRUE" ;
VAL_ 1412 IHVSRR_HtdCushBckLvl1 0 "FALSE" 1 "TRUE" ;
VAL_ 1412 IHVSRR_HtdCushBckAuto 0 "FALSE" 1 "TRUE" ;
VAL_ 1412 IHVSRR_HtdBckMd 0 "FALSE" 1 "TRUE" ;
VAL_ 1412 IHVSRR_HtdBckLvl3 0 "FALSE" 1 "TRUE" ;
VAL_ 1412 IHVSRR_HtdBckLvl2 0 "FALSE" 1 "TRUE" ;
VAL_ 1412 IHVSRR_HtdBckLvl1 0 "FALSE" 1 "TRUE" ;
VAL_ 1412 IHVSRR_VntMd 0 "FALSE" 1 "TRUE" ;
VAL_ 1412 IHVSRR_VntLvl3 0 "FALSE" 1 "TRUE" ;
VAL_ 1412 IHVSRR_VntLvl2 0 "FALSE" 1 "TRUE" ;
VAL_ 1412 IHVSRR_VntLvl1 0 "FALSE" 1 "TRUE" ;
VAL_ 1412 IHVSRR_VntAuto 0 "FALSE" 1 "TRUE" ;
VAL_ 1412 IHVSRR_HtdCushBckMd 0 "FALSE" 1 "TRUE" ;
VAL_ 1412 IndAirDstFL 0 "Off" 1 "Auto" 2 "Floor" 3 "Floor And Vent" 4 "Vent" 5 "Vent And Windshield" 6 "Windshield" 7 "Floor And Windshield" 8 "Floor And Vent And Windshield" 9 "Max Defrost" ;
VAL_ 1412 DrHndlLFAuthReqd 0 "FALSE" 1 "TRUE" ;
VAL_ 1412 AirDflctrIndReq 0 "Off" 1 "Service" 2 "Stuck" ;
VAL_ 1412 IndAirDstFR 0 "Off" 1 "Auto" 2 "Floor" 3 "Floor And Vent" 4 "Vent" 5 "Vent And Windshield" 6 "Windshield" 7 "Floor And Windshield" 8 "Floor And Vent And Windshield" 9 "Max Defrost" ;
VAL_ 1412 HVACUsrCtlIntrctnDispReqd 0 "FALSE" 1 "TRUE" ;
VAL_ 1412 FrtClsrRelAuthReqd 0 "FALSE" 1 "TRUE" ;
VAL_ 1412 DrHndlRRAuthReqd 0 "FALSE" 1 "TRUE" ;
VAL_ 1412 DrHndlRFAuthReqd 0 "FALSE" 1 "TRUE" ;
VAL_ 1412 DrHndlLRAuthReqd 0 "FALSE" 1 "TRUE" ;
VAL_ 1413 IndAirDstRL 0 "Off" 1 "Auto" 2 "Floor" 3 "Floor And Vent" 4 "Vent" 5 "Vent And Roof" 6 "Roof" 7 "Roof And Floor" 8 "Floor And Vent And Roof" ;
VAL_ 1413 IndAirDstRR 0 "Off" 1 "Auto" 2 "Floor" 3 "Floor And Vent" 4 "Vent" 5 "Vent And Roof" 6 "Roof" 7 "Roof And Floor" 8 "Floor And Vent And Roof" ;
VAL_ 1413 IndBlwStngStRr 0 "Off" 1 "Auto" 2 "Manual" ;
VAL_ 1413 IndBlwStngStFrt 0 "Off" 1 "Auto" 2 "Manual" ;
VAL_ 1413 IndHtdFrtWshldSet 0 "HFWS_OFF" 1 "HFWS_ON" ;
VAL_ 1413 IndFrtHVAC_On 0 "FALSE" 1 "TRUE" ;
VAL_ 1413 IndRecircStng 0 "Off" 1 "Fresh Air" 2 "Recirc" ;
VAL_ 1413 IndCompStng 0 "OFF" 1 "COMP_OFF" 2 "COMP_ON" 3 "COMP_ECON" ;
VAL_ 1413 IndSYNC_Rr 0 "FALSE" 1 "TRUE" ;
VAL_ 1413 IndSYNC_All 0 "FALSE" 1 "TRUE" ;
VAL_ 1413 IndRrWndDfgStng 0 "Rear Defog OFF" 1 "Rear Defog ON" ;
VAL_ 1413 IndRrHVAC_On 0 "FALSE" 1 "TRUE" ;
VAL_ 1413 IndRrHVAC_Lckd 0 "FALSE" 1 "TRUE" ;
VAL_ 1414 IndTmpStngStRL 0 "Off" 1 "Auto" 2 "Auto Lo" 3 "Auto Hi" 4 "Manual" ;
VAL_ 1414 IndTmpStngStFR 0 "Off" 1 "Auto" 2 "Auto Lo" 3 "Auto Hi" 4 "Manual" ;
VAL_ 1414 IndTmpStngStFL 0 "Off" 1 "Auto" 2 "Auto Lo" 3 "Auto Hi" 4 "Manual" ;
VAL_ 1414 PwrRrClsrCstCurrSetVal 0 "Setting_Unknown" 1 "Off" 2 "On" 3 "On_Custom_Height" 4 "RESERVED_4" 5 "RESERVED_5" 6 "RESERVED_6" 7 "RESERVED_7" ;
VAL_ 1414 PFASndSeltnCstCurrSetVal 0 "Setting_Unknown" 1 "Pedestrian Alert Sound 1" 2 "Pedestrian Alert Sound 2" 3 "Pedestrian Alert Sound 3" 4 "RESERVED_4" 5 "RESERVED_5" 6 "RESERVED_6" 7 "RESERVED_7" ;
VAL_ 1414 IndTmpStngStRR 0 "Off" 1 "Auto" 2 "Auto Lo" 3 "Auto Hi" 4 "Manual" ;
VAL_ 1414 ManlPrkLmpChmEvtSt 0 "NO ACTION" 1 "ACTIVE" 2 "CANCEL CHIME" ;
VAL_ 1414 LDCLDlydLkChmEvSt 0 "NO_ACTION" 1 "ACTIVE" 2 "CANCEL_CHIME" ;
VAL_ 1414 KeyInRmdrChmEvntSt 0 "NO_ACTION" 1 "ACTIVE" 2 "CANCEL_CHIME" ;
VAL_ 1414 PwrRrClsrNtfnChmEvntStat 0 "No_Action" 1 "Active" 2 "Cancel_Chime" ;
VAL_ 1414 PwrRrClsrNormOpChmEvntStat 0 "No_Action" 1 "Active" 2 "Cancel_Chime" ;
VAL_ 1414 OneSidedPrkLmpActvnChmEvtSt 0 "NO_ACTION" 1 "ACTIVE" 2 "CANCEL_CHIME" ;
VAL_ 1414 NoRtDetWrngChmEvSt 0 "NO_ACTION" 1 "ACTIVE" 2 "CANCEL_CHIME" ;
VAL_ 1414 RetainedACCpwrStatus 0 "FALSE" 1 "TRUE" ;
VAL_ 1414 PMMiRAPStatus 0 "FALSE" 1 "TRUE" ;
VAL_ 1414 ShfttoPrkChmEvntSt 0 "NO_ACTION" 1 "ACTIVE" 2 "CANCEL_CHIME" ;
VAL_ 1414 RemLtInVhWrngChmEvSt 0 "NO_ACTION" 1 "ACTIVE" 2 "CANCEL_CHIME" ;
VAL_ 1414 PwrRrClsrObstclChmEvntStat 0 "No_Action" 1 "Active" 2 "Cancel_Chime" ;
VAL_ 1414 PFASndSeltnCstSetAval 0 "FALSE" 1 "TRUE" ;
VAL_ 1414 PFASndSeltnCstAvlFlg7 0 "FALSE" 1 "TRUE" ;
VAL_ 1414 PFASndSeltnCstAvlFlg6 0 "FALSE" 1 "TRUE" ;
VAL_ 1414 PFASndSeltnCstAvlFlg5 0 "FALSE" 1 "TRUE" ;
VAL_ 1414 PFASndSeltnCstAvlFlg4 0 "FALSE" 1 "TRUE" ;
VAL_ 1414 PFASndSeltnCstAvlFlg3 0 "FALSE" 1 "TRUE" ;
VAL_ 1414 PFASndSeltnCstAvlFlg2 0 "FALSE" 1 "TRUE" ;
VAL_ 1414 PFASndSeltnCstAvlFlg1 0 "FALSE" 1 "TRUE" ;
VAL_ 1414 PwrRrClsrCstSetAval 0 "FALSE" 1 "TRUE" ;
VAL_ 1414 PwrRrClsrCstAvlFlg7 0 "FALSE" 1 "TRUE" ;
VAL_ 1414 PwrRrClsrCstAvlFlg6 0 "FALSE" 1 "TRUE" ;
VAL_ 1414 PwrRrClsrCstAvlFlg5 0 "FALSE" 1 "TRUE" ;
VAL_ 1414 PwrRrClsrCstAvlFlg4 0 "FALSE" 1 "TRUE" ;
VAL_ 1414 PwrRrClsrCstAvlFlg3 0 "FALSE" 1 "TRUE" ;
VAL_ 1414 PwrRrClsrCstAvlFlg2 0 "FALSE" 1 "TRUE" ;
VAL_ 1414 PwrRrClsrCstAvlFlg1 0 "FALSE" 1 "TRUE" ;
VAL_ 1414 StBltShfIntlkCstAvlFlg7 0 "FALSE" 1 "TRUE" ;
VAL_ 1414 StBltShfIntlkCstAvlFlg6 0 "FALSE" 1 "TRUE" ;
VAL_ 1414 StBltShfIntlkCstAvlFlg5 0 "FALSE" 1 "TRUE" ;
VAL_ 1414 StBltShfIntlkCstAvlFlg4 0 "FALSE" 1 "TRUE" ;
VAL_ 1414 StBltShfIntlkCstAvlFlg3 0 "FALSE" 1 "TRUE" ;
VAL_ 1414 StBltShfIntlkCstAvlFlg2 0 "FALSE" 1 "TRUE" ;
VAL_ 1414 StBltShfIntlkCstAvlFlg1 0 "FALSE" 1 "TRUE" ;
VAL_ 1414 RrClsrRelAuthReqd 0 "FALSE" 1 "TRUE" ;
VAL_ 1272 IndInzrStat 0 "OFF" 1 "Ionizer ON" 2 "Ionizer OFF" 3 "Ionizer LO" 4 "Ionizer HI" ;
VAL_ 1272 ConThftAlrmTrg 0 "NO_DATA" 1 "DRIVER DOOR AJAR" 2 "CODRIVER DOOR AJAR" 3 "LEFT REAR DOOR AJAR" 4 "RIGHT REAR DOOR AJAR" 5 "GLASS BREAKAGE" 6 "HOOD AJAR" 7 "INTRUSION" 8 "INCLINATION" 9 "REAR CLOSURE AJAR" 10 "LIFTGLASS AJAR" 11 "TARGA AJAR" 12 "TONNEAU AJAR" 13 "VEHICLE POWER MODE" 14 "CHARGE CORD ALERT" 15 "WHEEL TAMPER" 16 "PANIC ALARM" 17 "MODULE RESET" 18 "ENHANCED SERVICES ALARM" 19 "Trailer Theft" 20 "Convertible Top" ;
VAL_ 1272 ClmCtlBatSvrIndOn 0 "FALSE" 1 "TRUE" ;
VAL_ 1272 AutoLgtsInActvIndOn 0 "FALSE" 1 "TRUE" ;
VAL_ 1272 AutoLgtsActvIndOn 0 "FALSE" 1 "TRUE" ;
VAL_ 1272 ACCmpsrOprtng 0 "FALSE" 1 "TRUE" ;
VAL_ 1272 HtdStrgWhlInd_HVAC_FP_F 0 "Off" 1 "Low" 2 "Med" 3 "High" ;
VAL_ 1272 HtdFrntWSSt 0 "UNKNOWN" 1 "OFF" 2 "ON" ;
VAL_ 1272 ConThftSrvcIO 0 "FALSE" 1 "TRUE" ;
VAL_ 1272 ConThftAttmpdIO 0 "FALSE" 1 "TRUE" ;
VAL_ 1272 CnvtBkWndNotNormzIO 0 "FALSE" 1 "TRUE" ;
VAL_ 1272 CmpSftTopMotBfrOpTrnkIO 0 "FALSE" 1 "TRUE" ;
VAL_ 1272 CmbdDrHndlActvRF 0 "INACTIVE" 1 "ACTIVE" ;
VAL_ 1272 CmbdDrHndlActvLF 0 "INACTIVE" 1 "ACTIVE" ;
VAL_ 1272 DrIntHndlActnStatLF 0 "INACTIVE" 1 "ACTIVE" ;
VAL_ 1272 DrExtHndlActnStatRR 0 "INACTIVE" 1 "ACTIVE" ;
VAL_ 1272 DrExtHndlActnStatRF 0 "INACTIVE" 1 "ACTIVE" ;
VAL_ 1272 DrExtHndlActnStatLR 0 "INACTIVE" 1 "ACTIVE" ;
VAL_ 1272 DrExtHndlActnStatLF 0 "INACTIVE" 1 "ACTIVE" ;
VAL_ 1272 DlydAccTmrActv 0 "FALSE" 1 "TRUE" ;
VAL_ 1272 CrgLghtEnbldIO 0 "FALSE" 1 "TRUE" ;
VAL_ 1272 CrgLghtDsbldIO 0 "FALSE" 1 "TRUE" ;
VAL_ 1272 FrtClmAppFltDtnActv 0 "FALSE" 1 "TRUE" ;
VAL_ 1272 FobProgMdStatCmplt 0 "FALSE" 1 "TRUE" ;
VAL_ 1272 FobPrevLrndIndOn 0 "FALSE" 1 "TRUE" ;
VAL_ 1272 FobPogLimRchdIndOn 0 "FALSE" 1 "TRUE" ;
VAL_ 1272 EntrFobProgIndOn 0 "FALSE" 1 "TRUE" ;
VAL_ 1272 DrIntHndlActnStatRR 0 "INACTIVE" 1 "ACTIVE" ;
VAL_ 1272 DrIntHndlActnStatRF 0 "INACTIVE" 1 "ACTIVE" ;
VAL_ 1272 DrIntHndlActnStatLR 0 "INACTIVE" 1 "ACTIVE" ;
VAL_ 1272 HtdFrtWshldUnvIndOn 0 "FALSE" 1 "TRUE" ;
VAL_ 1272 HiBmIO 0 "FALSE" 1 "TRUE" ;
VAL_ 1272 HazSwAtvIO 0 "FALSE" 1 "TRUE" ;
VAL_ 1272 HVAC_StngsCtrlAvlbl 0 "FALSE" 1 "TRUE" ;
VAL_ 1272 FrtSnshdNormzRqrdIO 0 "FALSE" 1 "TRUE" ;
VAL_ 1272 FrtCmptServIndOn 0 "FALSE" 1 "TRUE" ;
VAL_ 1272 IntrSnsDsbld 0 "FALSE" 1 "TRUE" ;
VAL_ 1272 InrTlgtOpnIndOn 0 "FALSE" 1 "TRUE" ;
VAL_ 1272 IndTmpUnts 0 "Celcius" 1 "Fahrenheit" ;
VAL_ 1272 IndIntrAirQltyDispActv 0 "FALSE" 1 "TRUE" ;
VAL_ 1272 KeyInWrnIO 0 "FALSE" 1 "TRUE" ;
VAL_ 1794 IAQI_IntrAirQltyOvrallStat 0 "NoDisplay" 1 "AQIstate1" 2 "AQIstate2" 3 "AQIstate3" 4 "AQIstate4" 5 "AQIstate5" 6 "AQIstate6" 7 "NoDataAvailable" 8 "ServiceSensor" 9 "Unknown" ;
VAL_ 1794 IntrDimPlcSrvlnceModeActv 0 "FALSE" 1 "TRUE" ;
VAL_ 1794 IAQI_IntrAirQltyPrtclteStat 0 "NoDisplay" 1 "AQIstate1" 2 "AQIstate2" 3 "AQIstate3" 4 "AQIstate4" 5 "AQIstate5" 6 "AQIstate6" 7 "NoDataAvailable" 8 "ServiceSensor" 9 "Unknown" ;
VAL_ 1271 TDRCADD_LKAstAlrtsEvnts 0 "FALSE" 1 "TRUE" ;
VAL_ 1271 TDRCADD_LDWEvnts 0 "FALSE" 1 "TRUE" ;
VAL_ 1271 TDRCADD_FCMBrEvts 0 "FALSE" 1 "TRUE" ;
VAL_ 1271 TDRCADD_FCImntAlrts 0 "FALSE" 1 "TRUE" ;
VAL_ 1271 TDRCADD_FCHdwyAlrt 0 "FALSE" 1 "TRUE" ;
VAL_ 1271 TDRCADD_DrwDrvAlrt 0 "FALSE" 1 "TRUE" ;
VAL_ 1271 TDRCADD_DistDrvn 0 "FALSE" 1 "TRUE" ;
VAL_ 1271 TDRCADD_ABSAtvEvt 0 "FALSE" 1 "TRUE" ;
VAL_ 1271 TDRCADD_WOTEvnts 0 "FALSE" 1 "TRUE" ;
VAL_ 1271 TDRCADD_UnbckldDistDrvn 0 "FALSE" 1 "TRUE" ;
VAL_ 1271 TDRCADD_TrCtrlEvnts 0 "FALSE" 1 "TRUE" ;
VAL_ 1271 TDRCADD_StCtrlEvnts 0 "FALSE" 1 "TRUE" ;
VAL_ 1271 TDRCADD_RCMBrEvts 0 "FALSE" 1 "TRUE" ;
VAL_ 1271 TDRCADD_OvrSpdDistDrvn 0 "FALSE" 1 "TRUE" ;
VAL_ 1271 TDRCADD_OvSpdEvnt 0 "FALSE" 1 "TRUE" ;
VAL_ 1271 TDRCADD_MaxSpd 0 "FALSE" 1 "TRUE" ;
VAL_ 1271 RemCtrlFobNumForProg 0 "No Fob" 1 "Remote Control Fob #1" 2 "Remote Control Fob #2" 3 "Remote Control Fob #3" 4 "Remote Control Fob #4" 5 "Remote Control Fob #5" 6 "Remote Control Fob #6" 7 "Remote Control Fob #7" 8 "Remote Control Fob #8" 9 "Reserved_1" 10 "Reserved_2" 11 "Reserved_3" 12 "Reserved_4" 13 "Reserved_5" 14 "Reserved_6" 15 "Reserved_7" ;
VAL_ 1271 LstKyFbFnctnReq 0 "No Request" 1 "Remote Door Unlock Request" 2 "Remote Door Lock Request" 3 "Remote Start Request" 4 "Remote Stop Request" 5 "Remote Rear Closure Release Request" 6 "Remote Power Rear Closure Start Request" 7 "Remote Power Rear Closure Stop Request" 8 "Remote Fuel Operated Heater Request Off" 9 "RFA Mirror Unfold Request" 10 "RFA Mirror Fold Request" 11 "RFA Window Open Request" 12 "RFA Windows Close Request" 13 "Remote Fuel Operated Heater Request On" 14 "Remote Power Top Open" 15 "Remote Power Top Close" 16 "Remote Power Top Pause" 17 "Remote Power Top Stop" 18 "Remote Panic Alarm" 19 "Remote Locator Alarm" 20 "Remote Front Closure Release Request" 21 "Remote Charge Off" 22 "Remote Power Driver Door Motion Request Start" 23 "Remote Power Driver Door Motion Request Stop" 24 "Remote Power Bulkhead Door Motion Request Start" 25 "Remote Power Bulkhead Door Motion Request Stop" 26 "Reserved 26" 27 "Reserved 27" 28 "Remote Charge ON" 29 "Remote Power Front Compartment Start Request" 30 "Remote Power Front Compartment Stop Request" ;
VAL_ 1271 SnrfPstnSts 0 "Fully Closed" 1 "Vent" 2 "Partially Open" 3 "Fully Open" 4 "Comfort Open" ;
VAL_ 1271 TeenDrvRsp 0 "No_Action" 1 "Teen PIN Verified" 2 "Teen PIN Updated" 3 "Teen PIN Mismatch" 4 "Teen Key Set Complete" 5 "Teen Key Clear Complete" 6 "Key Not Present" 7 "Key Detected As Teen Key" 8 "Key Detected As NOT Teen Key" 9 "PIN Locked" ;
VAL_ 1271 NghtSchmAtv 0 "FALSE" 1 "TRUE" ;
VAL_ 1271 TireLkDtnEnblSts 0 "Unknown" 1 "Enabled" 2 "Disabled" ;
VAL_ 1271 RrClsrLckSts 0 "Unknown" 1 "Unlocked" 2 "Locked" ;
VAL_ 1271 StrtModeElecSeltnIndReq 0 "No Indication" 1 "Initializing" 2 "Normal" 3 "EV Mode" 4 "Charge Plus" ;
VAL_ 1271 RrDrUnlckIO 0 "FALSE" 1 "TRUE" ;
VAL_ 1271 RnSnsOffIO 0 "FALSE" 1 "TRUE" ;
VAL_ 1271 RnSnsActIO 0 "FALSE" 1 "TRUE" ;
VAL_ 1271 RmtPRNDLDispFltIndOn 0 "FALSE" 1 "TRUE" ;
VAL_ 1271 RmtCtlFobBatLoIndOn 0 "FALSE" 1 "TRUE" ;
VAL_ 1271 PwrLftgtUnvIndOn 0 "FALSE" 1 "TRUE" ;
VAL_ 1271 PwrLftgtOffIndOn 0 "FALSE" 1 "TRUE" ;
VAL_ 1271 PrkLmpIO 0 "FALSE" 1 "TRUE" ;
VAL_ 1271 ShftrLckdBcklDrvrStBltIndOn 0 "FALSE" 1 "TRUE" ;
VAL_ 1271 ServPwrLftgtIndOn 0 "FALSE" 1 "TRUE" ;
VAL_ 1271 ServKylsStSysIO 0 "FALSE" 1 "TRUE" ;
VAL_ 1271 ServHtdStrgWhlIndOn 0 "FALSE" 1 "TRUE" ;
VAL_ 1271 ServHdlmpsIndOn 0 "FALSE" 1 "TRUE" ;
VAL_ 1271 ServDrLtchSysIO 0 "FALSE" 1 "TRUE" ;
VAL_ 1271 RrStRmndrIndOn 0 "FALSE" 1 "TRUE" ;
VAL_ 1271 RrSnshdNormzRqrdIO 0 "FALSE" 1 "TRUE" ;
VAL_ 1271 MechShftrLckdHldBrkToOvrrdIndOn 0 "FALSE" 1 "TRUE" ;
VAL_ 1271 HdOpnShftrLckdOvrrdCmpltIndOn 0 "FALSE" 1 "TRUE" ;
VAL_ 1271 TeenDrvFtrAvl 0 "FALSE" 1 "TRUE" ;
VAL_ 1271 StNtLtchdThrdRowIO 0 "FALSE" 1 "TRUE" ;
VAL_ 1271 SnrfNormzRqrdIO 0 "FALSE" 1 "TRUE" ;
VAL_ 1271 ShftrUnlckdBrktoShfIndOn 0 "FALSE" 1 "TRUE" ;
VAL_ 1271 ShftrLckdBcklPsngrStBltIndOn 0 "FALSE" 1 "TRUE" ;
VAL_ 1795 MidgateAjrIndOn 0 "FALSE" 1 "TRUE" ;
VAL_ 1795 MidgateAjr 0 "FALSE" 1 "TRUE" ;
VAL_ 1270 TirePrsStatLRInr 0 "Unknown" 1 "Nominal" 2 "Low - Service Now" 3 "Low" 4 "Low - Extended Mobility" 5 "High" ;
VAL_ 1270 TirePrsLRInr_Inv 0 "FALSE" 1 "TRUE" ;
VAL_ 1270 TirePrsStatRRInr 0 "Unknown" 1 "Nominal" 2 "Low - Service Now" 3 "Low" 4 "Low - Extended Mobility" 5 "High" ;
VAL_ 1270 TirePrsRRInr_Inv 0 "FALSE" 1 "TRUE" ;
VAL_ 1270 TnDrvDRLOffUnbIO 0 "FALSE" 1 "TRUE" ;
VAL_ 1270 TnDrvALCOffUnbIO 0 "FALSE" 1 "TRUE" ;
VAL_ 1270 TlmtcsImmbAtv 0 "FALSE" 1 "TRUE" ;
VAL_ 1270 TirePrsLrnActIO 0 "FALSE" 1 "TRUE" ;
VAL_ 1270 TnDrvRptCrdAval 0 "FALSE" 1 "TRUE" ;
VAL_ 1270 TnDrvPINStrd 0 "FALSE" 1 "TRUE" ;
VAL_ 1270 TnDrvOvrSpdIO 0 "FALSE" 1 "TRUE" ;
VAL_ 1269 ValetMdResponse 0 "No Action" 1 "Valet Active - PIN Updated" 2 "Valet Active - PIN Invalid" 3 "Valet Inactive - PIN Valid" ;
VAL_ 1269 VTDDrvIndReq 0 "OFF" 1 "ON" 2 "0.5_Hz" 3 "1_Hz" 4 "2_Hz" 5 "4_Hz" 6 "RESERVED" ;
VAL_ 1269 TrnspModeActvIndOn 0 "FALSE" 1 "TRUE" ;
VAL_ 1269 TrlrLtngSeqStat 0 "Sequence_Off" 1 "Sequence_On" ;
VAL_ 1269 TrPrsMntrSysFld 0 "FALSE" 1 "TRUE" ;
VAL_ 1269 TPMTrLrnMdCmplt 0 "FALSE" 1 "TRUE" ;
VAL_ 1269 TrPrsMntrTrLdStat 0 "Unkown" 1 "Light Load" 2 "Best Economy Load" 3 "Max Load" ;
VAL_ 1269 ValetModeActive 0 "FALSE" 1 "TRUE" ;
VAL_ 1269 WndNormzRF 0 "FALSE" 1 "TRUE" ;
VAL_ 1269 WndNormzLR 0 "FALSE" 1 "TRUE" ;
VAL_ 1269 WndNormzLF 0 "FALSE" 1 "TRUE" ;
VAL_ 1269 VTDDrvMsgIO 0 "FALSE" 1 "TRUE" ;
VAL_ 1269 TxLrnFldIO 0 "FALSE" 1 "TRUE" ;
VAL_ 1269 TxBkUpLctIO 0 "FALSE" 1 "TRUE" ;
VAL_ 1269 TurnWprIntIO 0 "FALSE" 1 "TRUE" ;
VAL_ 1269 TrnspModeInactiveIndOn 0 "FALSE" 1 "TRUE" ;
VAL_ 1269 InfoAnm1Req 0 "No Request" 1 "Cancel" 2 "Start" ;
VAL_ 1269 BlkhdDrAjr 0 "FALSE" 1 "TRUE" ;
VAL_ 1269 WndNtNrmzdIORR 0 "FALSE" 1 "TRUE" ;
VAL_ 1269 WndNtNrmzdIOLR 0 "FALSE" 1 "TRUE" ;
VAL_ 1269 WndNtNrmzdIODrv 0 "FALSE" 1 "TRUE" ;
VAL_ 1269 WndNtNrmzdIOCoDrv 0 "FALSE" 1 "TRUE" ;
VAL_ 1269 WndNormzRR 0 "FALSE" 1 "TRUE" ;
VAL_ 1492 ACCCSV_Aux1Colr 0 "Setting Unknown" 1 "Off" 2 "Color Type 1" 3 "Color Type 2" 4 "Color Type 3" 5 "Color Type 4" 6 "Color Type 5" 7 "Color Type 6" 8 "Color Type 7" 9 "Color Type 8" 10 "Color Type 9" 11 "Color Type 10" 12 "Color Type 11" 13 "Color Type 12" 14 "Color Type 13" 15 "Color Type 14" 16 "Color Type 15" 17 "Color Type 16" 18 "Color Type 17" 19 "Color Type 18" 20 "Color Type 19" 21 "Color Type 20" 22 "Color Type 21" 23 "Color Type 22" 24 "Color Type 23" 25 "Color Type 24" 26 "Color Type 25" 27 "Color Type 26" 28 "Color Type 27" 29 "Color Type 28" 30 "Color Type 29" 31 "Color Type 30" 32 "Color Type 31" 33 "Color Type 32" 34 "Color Type 33" 35 "Color Type 34" 36 "Color Type 35" 37 "Color Type 36" 38 "Color Type 37" 39 "Color Type 38" 40 "Color Type 39" 41 "Color Type 40" 42 "Color Type 41" 43 "Color Type 42" 44 "Color Type 43" 45 "Color Type 44" 46 "Color Type 45" 47 "Color Type 46" 48 "Color Type 47" 49 "Color Type 48" 50 "Color Type 49" 51 "Color Type 50" 52 "Color Type 51" 53 "Color Type 52" 54 "Color Type 53" 55 "Color Type 54" 56 "Color Type 55" 57 "Color Type 56" 58 "Color Type 57" 59 "Color Type 58" 60 "Color Type 59" 61 "Color Type 60" 62 "Color Type 61" 63 "Color Type 62" 64 "Color Type 63" 65 "Color Type 64" 66 "Color Type 65" 67 "Color Type 66" 68 "Color Type 67" 69 "Color Type 68" 70 "Color Type 69" 71 "Color Type 70" 72 "Color Type 71" 73 "Color Type 72" 74 "Color Type 73" 75 "Color Type 74" 76 "Color Type 75" 77 "Color Type 76" 78 "Color Type 77" 79 "Color Type 78" 80 "Color Type 79" 81 "Color Type 80" 82 "Color Type 81" 83 "Color Type 82" 84 "Color Type 83" 85 "Color Type 84" 86 "Color Type 85" 87 "Color Type 86" 88 "Color Type 87" 89 "Color Type 88" 90 "Color Type 89" 91 "Color Type 90" 92 "Color Type 91" 93 "Color Type 92" 94 "Color Type 93" 95 "Color Type 94" 96 "Color Type 95" 97 "Color Type 96" 98 "Color Type 97" 99 "Color Type 98" 100 "Color Type 99" 101 "Color Type 100" 102 "Color Type 101" 103 "Color Type 102" 104 "Color Type 103" 105 "Color Type 104" 106 "Color Type 105" 107 "Color Type 106" 108 "Color Type 107" 109 "Color Type 108" 110 "Color Type 109" 111 "Color Type 110" 112 "Color Type 111" 113 "Color Type 112" 114 "Color Type 113" 115 "Color Type 114" 116 "Color Type 115" 117 "Color Type 116" 118 "Color Type 117" 119 "Color Type 118" 120 "Color Type 119" 121 "Color Type 120" 122 "Color Type 121" 123 "Color Type 122" 124 "Color Type 123" 125 "Color Type 124" 126 "Color Type 125" 127 "Color Type 126" ;
VAL_ 1492 ACCCSV_Aux1Brghtns 0 "Setting Unknown" 1 "BrightnessLevel 1" 2 "BrightnessLevel 2" 3 "BrightnessLevel 3" 4 "BrightnessLevel 4" 5 "ReservedLevel 5" 6 "ReservedLevel 6" 7 "ReservedLevel 7" ;
VAL_ 1492 ACCCSV_Aux1Anm 0 "Setting Unknown" 1 "Off" 2 "Animation Type 1" 3 "Animation Type 2" 4 "Animation Type 3" 5 "Animation Type 4" 6 "Animation Type 5" 7 "Animation Type 6" 8 "Animation Type 7" 9 "Animation Type 8" 10 "Animation Type 9" 11 "Animation Type 10" 12 "Animation Type 11" 13 "Animation Type 12" 14 "Animation Type 13" 15 "Animation Type 14" ;
VAL_ 1492 ACCCSV_IntrAnm 0 "Setting Unknown" 1 "Off" 2 "Animation Type 1" 3 "Animation Type 2" 4 "Animation Type 3" 5 "Animation Type 4" 6 "Animation Type 5" 7 "Animation Type 6" 8 "Animation Type 7" 9 "Animation Type 8" 10 "Animation Type 9" 11 "Animation Type 10" 12 "Animation Type 11" 13 "Animation Type 12" 14 "Animation Type 13" 15 "Animation Type 14" ;
VAL_ 1492 ACCCSV_IntrColr 0 "Setting Unknown" 1 "Off" 2 "Color Type 1" 3 "Color Type 2" 4 "Color Type 3" 5 "Color Type 4" 6 "Color Type 5" 7 "Color Type 6" 8 "Color Type 7" 9 "Color Type 8" 10 "Color Type 9" 11 "Color Type 10" 12 "Color Type 11" 13 "Color Type 12" 14 "Color Type 13" 15 "Color Type 14" 16 "Color Type 15" 17 "Color Type 16" 18 "Color Type 17" 19 "Color Type 18" 20 "Color Type 19" 21 "Color Type 20" 22 "Color Type 21" 23 "Color Type 22" 24 "Color Type 23" 25 "Color Type 24" 26 "Color Type 25" 27 "Color Type 26" 28 "Color Type 27" 29 "Color Type 28" 30 "Color Type 29" 31 "Color Type 30" 32 "Color Type 31" 33 "Color Type 32" 34 "Color Type 33" 35 "Color Type 34" 36 "Color Type 35" 37 "Color Type 36" 38 "Color Type 37" 39 "Color Type 38" 40 "Color Type 39" 41 "Color Type 40" 42 "Color Type 41" 43 "Color Type 42" 44 "Color Type 43" 45 "Color Type 44" 46 "Color Type 45" 47 "Color Type 46" 48 "Color Type 47" 49 "Color Type 48" 50 "Color Type 49" 51 "Color Type 50" 52 "Color Type 51" 53 "Color Type 52" 54 "Color Type 53" 55 "Color Type 54" 56 "Color Type 55" 57 "Color Type 56" 58 "Color Type 57" 59 "Color Type 58" 60 "Color Type 59" 61 "Color Type 60" 62 "Color Type 61" 63 "Color Type 62" 64 "Color Type 63" 65 "Color Type 64" 66 "Color Type 65" 67 "Color Type 66" 68 "Color Type 67" 69 "Color Type 68" 70 "Color Type 69" 71 "Color Type 70" 72 "Color Type 71" 73 "Color Type 72" 74 "Color Type 73" 75 "Color Type 74" 76 "Color Type 75" 77 "Color Type 76" 78 "Color Type 77" 79 "Color Type 78" 80 "Color Type 79" 81 "Color Type 80" 82 "Color Type 81" 83 "Color Type 82" 84 "Color Type 83" 85 "Color Type 84" 86 "Color Type 85" 87 "Color Type 86" 88 "Color Type 87" 89 "Color Type 88" 90 "Color Type 89" 91 "Color Type 90" 92 "Color Type 91" 93 "Color Type 92" 94 "Color Type 93" 95 "Color Type 94" 96 "Color Type 95" 97 "Color Type 96" 98 "Color Type 97" 99 "Color Type 98" 100 "Color Type 99" 101 "Color Type 100" 102 "Color Type 101" 103 "Color Type 102" 104 "Color Type 103" 105 "Color Type 104" 106 "Color Type 105" 107 "Color Type 106" 108 "Color Type 107" 109 "Color Type 108" 110 "Color Type 109" 111 "Color Type 110" 112 "Color Type 111" 113 "Color Type 112" 114 "Color Type 113" 115 "Color Type 114" 116 "Color Type 115" 117 "Color Type 116" 118 "Color Type 117" 119 "Color Type 118" 120 "Color Type 119" 121 "Color Type 120" 122 "Color Type 121" 123 "Color Type 122" 124 "Color Type 123" 125 "Color Type 124" 126 "Color Type 125" 127 "Color Type 126" ;
VAL_ 1492 ACCCSV_IntrBrghtns 0 "Setting Unknown" 1 "BrightnessLevel 1" 2 "BrightnessLevel 2" 3 "BrightnessLevel 3" 4 "BrightnessLevel 4" 5 "ReservedLevel 5" 6 "ReservedLevel 6" 7 "ReservedLevel 7" ;
VAL_ 1492 AutDrvLckCstCurSetVal 0 "SETTING_UNKNOWN" 1 "OFF" 2 "ON" 3 "RESERVED_3" 4 "RESERVED_4" 5 "RESERVED_5" 6 "RESERVED_6" 7 "RESERVED_7" ;
VAL_ 1492 AirQltySnsCstCrStVal 0 "SETTING_UNKNOWN" 1 "OFF" 2 "LOW_SENSITIVITY" 3 "HI_SENSITIVITY" 4 "RESERVED_1" 5 "RESERVED_2" 6 "RESERVED_3" 7 "RESERVED_4" ;
VAL_ 1492 AutoAirDstCstCrStVal 0 "SETTING_UNKNOWN" 1 "DIFFUSE_AIRFLOW" 2 "NORMAL" 3 "DIRECT_AIRFLOW" 4 "OSCILLATING_AIRFLOW" 5 "RESERVED_1" 6 "RESERVED_2" 7 "RESERVED_3" ;
VAL_ 1492 AutMirFldCstCurSetVal 0 "SETTING_UNKNOWN" 1 "Off" 2 "On" 3 "RESERVED_3" 4 "RESERVED_4" 5 "RESERVED_5" 6 "RESERVED_6" 7 "RESERVED_7" ;
VAL_ 1492 AutoFanCstCrStVal 0 "SETTING_UNKNOWN" 1 "LOW" 2 "NORMAL" 3 "HIGH" 4 "RESERVED_1" 5 "RESERVED_2" 6 "RESERVED_3" 7 "RESERVED_4" ;
VAL_ 1492 AutoDfgCstCrStVal 0 "SETTING_UNKNOWN" 1 "OFF" 2 "ON" 3 "RESERVED_1" 4 "RESERVED_2" 5 "RESERVED_3" 6 "RESERVED_4" 7 "RESERVED_5" ;
VAL_ 1492 AutoCoolStCstCrStVal 0 "SETTING_UNKNOWN" 1 "OFF" 2 "ON" 3 "RESERVED_1" 4 "RESERVED_2" 5 "RESERVED_3" 6 "RESERVED_4" 7 "RESERVED_5" ;
VAL_ 1492 AirQltySnsCstStAvl 0 "FALSE" 1 "TRUE" ;
VAL_ 1492 AutoRrWpCstCurSetVal 0 "SETTING_UNKNOWN" 1 "OFF" 2 "ON" 3 "RESERVED_3" 4 "RESERVED_4" 5 "RESERVED_5" 6 "RESERVED_6" 7 "RESERVED_7" ;
VAL_ 1492 AutoHtdStCstCrStVal 0 "SETTING_UNKNOWN" 1 "OFF" 2 "ON" 3 "RESERVED_1" 4 "RESERVED_2" 5 "RESERVED_3" 6 "RESERVED_4" 7 "RESERVED_5" ;
VAL_ 1492 AutoRrWpCstStAvl 0 "FALSE" 1 "TRUE" ;
VAL_ 1492 AutoHtdStCstStAvl 0 "FALSE" 1 "TRUE" ;
VAL_ 1492 AutoFanCstStAvl 0 "FALSE" 1 "TRUE" ;
VAL_ 1492 AutoDfgCstStAvl 0 "FALSE" 1 "TRUE" ;
VAL_ 1492 AutoCoolStCstStAvl 0 "FALSE" 1 "TRUE" ;
VAL_ 1492 AutoAirDstCstStAvl 0 "FALSE" 1 "TRUE" ;
VAL_ 1492 AutMirFldCstStAvl 0 "FALSE" 1 "TRUE" ;
VAL_ 1492 AutDrvLckCstStAvl 0 "FALSE" 1 "TRUE" ;
VAL_ 1493 PlltnCtrlCstCrStVal 0 "SETTING_UNKNOWN" 1 "OFF" 2 "ON" 3 "RESERVED_1" 4 "RESERVED_2" 5 "RESERVED_3" 6 "RESERVED_4" 7 "RESERVED_5" ;
VAL_ 1493 OpDrAtLOCstCurSetVal 0 "SETTING_UNKNOWN" 1 "OFF" 2 "ON" 3 "RESERVED_3" 4 "RESERVED_4" 5 "RESERVED_5" 6 "RESERVED_6" 7 "RESERVED_7" ;
VAL_ 1493 LDCLCstCurSetVal 0 "SETTING_UNKNOWN" 1 "OFF" 2 "ON" 3 "RESERVED_3" 4 "RESERVED_4" 5 "RESERVED_5" 6 "RESERVED_6" 7 "RESERVED_7" ;
VAL_ 1493 RemLftVehRmndrCstCurSetVal 0 "SETTING_UNKNOWN" 1 "OFF" 2 "ON" 3 "RESERVED_3" 4 "RESERVED_4" 5 "RESERVED_5" 6 "RESERVED_6" 7 "RESERVED_7" ;
VAL_ 1493 RemInVehRmndrCstCurSetVal 0 "SETTING_UNKNOWN" 1 "OFF" 2 "ON" 3 "RESERVED_3" 4 "RESERVED_4" 5 "RESERVED_5" 6 "RESERVED_6" 7 "RESERVED_7" ;
VAL_ 1493 PsvUnlckCstCurSetVal 0 "SETTING_UNKNOWN" 1 "DRIVER_DOOR" 2 "ALL_DOORS" 3 "OFF" 4 "RESERVED_4" 5 "RESERVED_5" 6 "RESERVED_6" 7 "RESERVED_7" ;
VAL_ 1493 RlkRtUlkDrCstCrSetVal 0 "SETTING_UNKNOWN" 1 "OFF" 2 "ON" 3 "RESERVED_3" 4 "RESERVED_4" 5 "RESERVED_5" 6 "RESERVED_6" 7 "RESERVED_7" ;
VAL_ 1493 RevTltMirCstCurSetVal 0 "SETTING_UNKNOWN" 1 "OFF" 2 "DRIVER" 3 "PASSENGER" 4 "DRIVER_AND_PASSENGER" 5 "RESERVED_5" 6 "RESERVED_6" 7 "RESERVED_7" ;
VAL_ 1493 RmtStrtHtdStCstCrStVal 0 "SETTING_UNKNOWN" 1 "OFF" 2 "ON" 3 "RESERVED_1" 4 "RESERVED_2" 5 "RESERVED_3" 6 "RESERVED_4" 7 "RESERVED_5" ;
VAL_ 1493 RmtStrtCoolStCstCrStVal 0 "SETTING_UNKNOWN" 1 "OFF" 2 "ON" 3 "RESERVED_1" 4 "RESERVED_2" 5 "RESERVED_3" 6 "RESERVED_4" 7 "RESERVED_5" ;
VAL_ 1493 RmtSnrfOpCstCurrSetVal 0 "Setting_Unknown" 1 "Off" 2 "On" 3 "Reserved_3" 4 "Reserved_4" 5 "Reserved_5" 6 "Reserved_6" 7 "Reserved_7" ;
VAL_ 1493 RrAirHandlingDrActrPwrReq 0 "No Action" 1 "Power Off" 2 "Power On" ;
VAL_ 1493 RnSnsCstCurSetVal 0 "SETTING_UNKNOWN" 1 "OFF" 2 "ON" 3 "RESERVED_3" 4 "RESERVED_4" 5 "RESERVED_5" 6 "RESERVED_6" 7 "RESERVED_7" ;
VAL_ 1493 RmtWndOpCstCurSetVal 0 "SETTING_UNKNOWN" 1 "OFF" 2 "ON" 3 "RESERVED_3" 4 "RESERVED_4" 5 "RESERVED_5" 6 "RESERVED_6" 7 "RESERVED_7" ;
VAL_ 1493 RevTltMirCstStAvl 0 "FALSE" 1 "TRUE" ;
VAL_ 1493 RemLftVehRmndrCstStAvl 0 "FALSE" 1 "TRUE" ;
VAL_ 1493 RemInVehRmndrCstStAvl 0 "FALSE" 1 "TRUE" ;
VAL_ 1493 PsvUnlckCstStAvl 0 "FALSE" 1 "TRUE" ;
VAL_ 1493 PlltnCtrlCstStAvl 0 "FALSE" 1 "TRUE" ;
VAL_ 1493 OpDrAtLOCstStAvl 0 "FALSE" 1 "TRUE" ;
VAL_ 1493 LDCLCstStAvl 0 "FALSE" 1 "TRUE" ;
VAL_ 1493 RnSnsCstStAvl 0 "FALSE" 1 "TRUE" ;
VAL_ 1493 RmtWndOpCstStAvl 0 "FALSE" 1 "TRUE" ;
VAL_ 1493 RmtStrtHtdStCstStAvl 0 "FALSE" 1 "TRUE" ;
VAL_ 1493 RmtStrtCoolStCstStAvl 0 "FALSE" 1 "TRUE" ;
VAL_ 1493 RmtSnrfOpCstSetAval 0 "FALSE" 1 "TRUE" ;
VAL_ 1493 RlkRtUlkDrCstStAvl 0 "FALSE" 1 "TRUE" ;
VAL_ 1494 TDOSWCCSV_CrSetVal 0 "SETTING_UNKNOWN" 1 "OFF" 2 "ON" 3 "RESERVED_3" 4 "RESERVED_4" 5 "RESERVED_5" 6 "RESERVED_6" 7 "RESERVED_7" ;
VAL_ 1494 TDSLCCSV_CrSetVal 0 "SETTING_UNKNOWN" 1 "OFF" 2 "ON" 3 "RESERVED_3" 4 "RESERVED_4" 5 "RESERVED_5" 6 "RESERVED_6" 7 "RESERVED_7" ;
VAL_ 1494 RrStRmndrEnblDsblCstCurrSetVal 0 "Setting_Unknown" 1 "Off" 2 "On" 3 "(Reserved_3" 4 "Reserved_4" 5 "Reserved_5" 6 "Reserved_6" 7 "Reserved_7)" ;
VAL_ 1494 RrDfgStUpCstCrStVal 0 "SETTING_UNKNOWN" 1 "MANUAL" 2 "AUTOMATIC" 3 "RESERVED_1" 4 "RESERVED_2" 5 "RESERVED_3" 6 "RESERVED_4" 7 "RESERVED_5" ;
VAL_ 1494 RtUlkLtFbCstCurSetVal 0 "SETTING_UNKNOWN" 1 "OFF" 2 "FLASH_LIGHTS_ON" 3 "RESERVED_3" 4 "RESERVED_4" 5 "RESERVED_5" 6 "RESERVED_6" 7 "RESERVED_7" ;
VAL_ 1494 RtLkFdbkCstCurSetVal 0 "SETTING_UNKNOWN" 1 "HORN_AND_LIGHTS_OFF" 2 "HORN_AND_LIGHTS_ON" 3 "FLASH_LIGHTS_ONLY" 4 "HORN_CHIRP_ONLY" 5 "RESERVED_5" 6 "RESERVED_6" 7 "RESERVED_7" ;
VAL_ 1494 RrZnStUpCstCrStVal 0 "SETTING_UNKNOWN" 1 "REAR_OFF" 2 "REAR_MIMIC_FRONT" 3 "REAR_LAST_KNOWN" 4 "RESERVED_1" 5 "RESERVED_2" 6 "RESERVED_3" 7 "RESERVED_4" ;
VAL_ 1494 WlkAwyLckCstCurSetVal 0 "SETTING_UNKNOWN" 1 "OFF" 2 "ON" 3 "ON_WITH_CHIRP" 4 "RESERVED_4" 5 "RESERVED_5" 6 "RESERVED_6" 7 "RESERVED_7" ;
VAL_ 1494 VehLctrLghtsCstCurSetVal 0 "SETTING_UNKNOWN" 1 "OFF" 2 "ON" 3 "On Without Animation" 4 "RESERVED_4" 5 "RESERVED_5" 6 "RESERVED_6" 7 "RESERVED_7" ;
VAL_ 1494 SelUlkCstCurSetVal 0 "SETTING_UNKNOWN" 1 "DRIVER_DOOR_ONLY" 2 "ALL_DOORS" 3 "RESERVED_3" 4 "RESERVED_4" 5 "RESERVED_5" 6 "RESERVED_6" 7 "RESERVED_7" ;
VAL_ 1494 SelUlkCstStAvl 0 "FALSE" 1 "TRUE" ;
VAL_ 1494 RtUlkLtFbCstStAvl 0 "FALSE" 1 "TRUE" ;
VAL_ 1494 RtLkFdbkCstStAvl 0 "FALSE" 1 "TRUE" ;
VAL_ 1494 RrZnStUpCstStAvl 0 "FALSE" 1 "TRUE" ;
VAL_ 1494 RrStRmndrEnblDsblCstSetAval 0 "FALSE" 1 "TRUE" ;
VAL_ 1494 RrDfgStUpCstStAvl 0 "FALSE" 1 "TRUE" ;
VAL_ 1494 WlkAwyLckCstStAvl 0 "FALSE" 1 "TRUE" ;
VAL_ 1494 VehLctrLghtsCstStAvl 0 "FALSE" 1 "TRUE" ;
VAL_ 1494 TnDrvSpdLmtCstStAvl 0 "FALSE" 1 "TRUE" ;
VAL_ 1494 TnDrvOvSpdWrnCstStAvl 0 "FALSE" 1 "TRUE" ;
VAL_ 1495 IHVSLF_HtdCushBckLvl2 0 "FALSE" 1 "TRUE" ;
VAL_ 1495 IHVSLF_HtdCushBckLvl1 0 "FALSE" 1 "TRUE" ;
VAL_ 1495 IHVSLF_HtdCushBckAuto 0 "FALSE" 1 "TRUE" ;
VAL_ 1495 IHVSLF_HtdBckMd 0 "FALSE" 1 "TRUE" ;
VAL_ 1495 IHVSLF_HtdBckLvl3 0 "FALSE" 1 "TRUE" ;
VAL_ 1495 IHVSLF_HtdBckLvl2 0 "FALSE" 1 "TRUE" ;
VAL_ 1495 IHVSLF_HtdBckLvl1 0 "FALSE" 1 "TRUE" ;
VAL_ 1495 IHVSLF_HtdBckAuto 0 "FALSE" 1 "TRUE" ;
VAL_ 1495 IHVSRF_HtdBckAuto 0 "FALSE" 1 "TRUE" ;
VAL_ 1495 IHVSLF_VntMd 0 "FALSE" 1 "TRUE" ;
VAL_ 1495 IHVSLF_VntLvl3 0 "FALSE" 1 "TRUE" ;
VAL_ 1495 IHVSLF_VntLvl2 0 "FALSE" 1 "TRUE" ;
VAL_ 1495 IHVSLF_VntLvl1 0 "FALSE" 1 "TRUE" ;
VAL_ 1495 IHVSLF_VntAuto 0 "FALSE" 1 "TRUE" ;
VAL_ 1495 IHVSLF_HtdCushBckMd 0 "FALSE" 1 "TRUE" ;
VAL_ 1495 IHVSLF_HtdCushBckLvl3 0 "FALSE" 1 "TRUE" ;
VAL_ 1495 IHVSRF_HtdCushBckLvl3 0 "FALSE" 1 "TRUE" ;
VAL_ 1495 IHVSRF_HtdCushBckLvl2 0 "FALSE" 1 "TRUE" ;
VAL_ 1495 IHVSRF_HtdCushBckLvl1 0 "FALSE" 1 "TRUE" ;
VAL_ 1495 IHVSRF_HtdCushBckAuto 0 "FALSE" 1 "TRUE" ;
VAL_ 1495 IHVSRF_HtdBckMd 0 "FALSE" 1 "TRUE" ;
VAL_ 1495 IHVSRF_HtdBckLvl3 0 "FALSE" 1 "TRUE" ;
VAL_ 1495 IHVSRF_HtdBckLvl2 0 "FALSE" 1 "TRUE" ;
VAL_ 1495 IHVSRF_HtdBckLvl1 0 "FALSE" 1 "TRUE" ;
VAL_ 1495 IntDimSeldClrTypStVal 0 "No Action" 1 "Off" 2 "Color Type 1" 3 "Color Type 2" 4 "Color Type 3" 5 "Color Type 4" 6 "Color Type 5" 7 "Color Type 6" 8 "Color Type 7" 9 "Color Type 8" 10 "Color Type 9" 11 "Color Type 10" 12 "Color Type 11" 13 "Color Type 12" 14 "Color Type 13" 15 "Color Type 14" 16 "Color Type 15" 17 "Color Type 16" 18 "Color Type 17" 19 "Color Type 18" 20 "Color Type 19" 21 "Color Type 20" 22 "Color Type 21" 23 "Color Type 22" 24 "Color Type 23" 25 "Color Type 24" 26 "Color Type 25" 27 "Color Type 26" 28 "Color Type 27" 29 "Color Type 28" 30 "Color Type 29" 31 "Color Type 30" ;
VAL_ 1495 IHVSRF_VntMd 0 "FALSE" 1 "TRUE" ;
VAL_ 1495 IHVSRF_VntLvl3 0 "FALSE" 1 "TRUE" ;
VAL_ 1495 IHVSRF_VntLvl2 0 "FALSE" 1 "TRUE" ;
VAL_ 1495 IHVSRF_VntLvl1 0 "FALSE" 1 "TRUE" ;
VAL_ 1495 IHVSRF_VntAuto 0 "FALSE" 1 "TRUE" ;
VAL_ 1495 IHVSRF_HtdCushBckMd 0 "FALSE" 1 "TRUE" ;
VAL_ 1495 AutUnlckCstCurSetVal 0 "NO_ACTION" 1 "OFF" 2 "ALL_DOORS" 3 "DRIVER_DOOR" 4 "RESERVED_4" 5 "RESERVED_5" 6 "RESERVED_6" 7 "RESERVED_7" ;
VAL_ 1495 IntDimSeldAnmTypStVal 0 "No Action" 1 "Off" 2 "Animation Type 1" 3 "Animation Type 2" 4 "Animation Type 3" 5 "Animation Type 4" 6 "Animation Type 5" 7 "Animation Type 6" 8 "Animation Type 7" 9 "Animation Type 8" 10 "Animation Type 9" 11 "Animation Type 10" 12 "Animation Type 11" 13 "Animation Type 12" 14 "Animation Type 13" 15 "Animation Type 14" ;
VAL_ 1495 ExtLghtCstCurSetVal 0 "SETTING_UNKNOWN" 1 "OFF" 2 "THIRTY_SECONDS_DEFAULT" 3 "ONE_MINUTE" 4 "TWO_MINUTES" 5 "RESERVED_5" 6 "RESERVED_6" 7 "RESERVED_7" ;
VAL_ 1495 DaytimeTlLghtsCstCurSetVal 0 "SETTING_UNKNOWN" 1 "OFF" 2 "ON" 3 "RESERVED_3" 4 "RESERVED_4" 5 "RESERVED_5" 6 "RESERVED_6" 7 "RESERVED_7" ;
VAL_ 1495 CurbVwFtrActvReq 0 "On" 1 "Off" 2 "Failed" ;
VAL_ 1495 IonzrCtrlCstCrStVal 0 "SETTING_UNKNOWN" 1 "OFF" 2 "ON" 3 "RESERVED_1" 4 "RESERVED_2" 5 "RESERVED_3" 6 "RESERVED_4" 7 "RESERVED_5" ;
VAL_ 1495 HFRCCstCurSetVal 0 "SETTING_UNKNOWN" 1 "OFF" 2 "OPEN_AND_CLOSE" 3 "OPEN_ONLY" 4 "RESERVED_4" 5 "RESERVED_5" 6 "RESERVED_6" 7 "RESERVED_7" ;
VAL_ 1495 IonzrCtrlCstStAvl 0 "FALSE" 1 "TRUE" ;
VAL_ 1495 HFRCCstStAvl 0 "FALSE" 1 "TRUE" ;
VAL_ 1495 ExtLghtCstStAvl 0 "FALSE" 1 "TRUE" ;
VAL_ 1495 DaytimeTlLghtsCstStAvl 0 "FALSE" 1 "TRUE" ;
VAL_ 1495 CrsCntCncRq 0 "Do Not Cancel" 1 "Cancel" ;
VAL_ 1495 AutUnlckCstStAvl 0 "FALSE" 1 "TRUE" ;
VAL_ 1177 PCOSN_NtfnDrvrStBltSts 0 "Unknown" 1 "UnFastened" 2 "Fastened" 3 "Data Not Available" ;
VAL_ 1177 PCOSN_NtfnImpDeltVelTxSts 0 "Not Available" 1 "Pending" 2 "Complete" ;
VAL_ 1177 PCOSN_NtfnFrstPsngrStOccpSts 0 "UNKNOWN" 1 "EMPTY" 2 "OCCUPIED" 3 "DATA NOT AVAILABLE" ;
VAL_ 1177 PCOSN_NtfnFrstPsngrStBltSts 0 "Unknown" 1 "UnFastened" 2 "Fastened" 3 "Data Not Available" ;
VAL_ 1177 PCOSN_NtfnSecRowLtStOccpSts 0 "Unknown" 1 "Empty" 2 "Occupied" 3 "Data Not Available" ;
VAL_ 1177 PCOSN_NtfnSecRowLtStBltSts 0 "Unknown" 1 "UnFastened" 2 "Fastened" 3 "Data Not Available" ;
VAL_ 1177 PCOSN_NtfnSecRowCntrStOccpSts 0 "Unknown" 1 "Empty" 2 "Occupied" 3 "Data Not Available" ;
VAL_ 1177 PCOSN_NtfnSecRowCntrStBltSts 0 "Unknown" 1 "UnFastened" 2 "Fastened" 3 "Data Not Available" ;
VAL_ 1177 PCOSN_NtfnThrdRowCntrStOccpSts 0 "Unknown" 1 "Empty" 2 "Occupied" 3 "Data Not Available" ;
VAL_ 1177 PCOSN_NtfnThrdRowCntrStBltSts 0 "Unknown" 1 "UnFastened" 2 "Fastened" 3 "Data Not Available" ;
VAL_ 1177 PCOSN_NtfnSecRowRtStOccpSts 0 "Unknown" 1 "Empty" 2 "Occupied" 3 "Data Not Available" ;
VAL_ 1177 PCOSN_NtfnSecRowRtStBltSts 0 "Unknown" 1 "UnFastened" 2 "Fastened" 3 "Data Not Available" ;
VAL_ 1177 PCOSN_NtfnThrdRowRtStOccpSts 0 "Unknown" 1 "Empty" 2 "Occupied" 3 "Data Not Available" ;
VAL_ 1177 PCOSN_NtfnThrdRowRtStBltSts 0 "Unknown" 1 "UnFastened" 2 "Fastened" 3 "Data Not Available" ;
VAL_ 1177 PCOSN_NtfnThrdRowLtStOccpSts 0 "Unknown" 1 "Empty" 2 "Occupied" 3 "Data Not Available" ;
VAL_ 1177 PCOSN_NtfnThrdRowLtStBltSts 0 "Unknown" 1 "UnFastened" 2 "Fastened" 3 "Data Not Available" ;
VAL_ 1177 PCOSN_NtfnFrstRowCntrStOccpSts 0 "Unknown" 1 "Empty" 2 "Occupied" 3 "Data Not Available" ;
VAL_ 1177 PCOSN_NtfnFrstRowCntrStBtSts 0 "Unknown" 1 "UnFastened" 2 "Fastened" 3 "Data Not Available" ;
VAL_ 1177 PCOSN_NtfnDrvrStOccpSts 0 "Unknown" 1 "Empty" 2 "Occupied" 3 "Data Not Available" ;
VAL_ 1500 DM1Unavailable 0 "FALSE" 1 "TRUE" ;
VAL_ 1500 DM1Status 0 "Inactive" 1 "Active" ;
VAL_ 1500 DM1Pending 0 "FALSE" 1 "TRUE" ;
VAL_ 1500 DM1Name 0 "None" 1 "Tour" 2 "Sport" 3 "Track" 4 "Winter" 5 "Off Road" 6 "Tow/Haul" 7 "Hold" 8 "Mountain" 9 "Personal" 10 "Custom" 11 "AWD" 12 "Economy" 13 "Automatic" 14 "EV" 15 "Grade Braking" 16 "Exhaust Brake" 17 "Active Rev Match" 18 "2WD" 19 "Comfort" 20 "Start/Stop Disable" 21 "Crawl" 22 "Charge Plus" 23 "Baja" 24 "Max Power" 25 "Boat Ramp" ;
VAL_ 1500 DM2Unavailable 0 "FALSE" 1 "TRUE" ;
VAL_ 1500 DM2Status 0 "Inactive" 1 "Active" ;
VAL_ 1500 DM2Pending 0 "FALSE" 1 "TRUE" ;
VAL_ 1500 DM2Name 0 "None" 1 "Tour" 2 "Sport" 3 "Track" 4 "Winter" 5 "Off Road" 6 "Tow/Haul" 7 "Hold" 8 "Mountain" 9 "Personal" 10 "Custom" 11 "AWD" 12 "Economy" 13 "Automatic" 14 "EV" 15 "Grade Braking" 16 "Exhaust Brake" 17 "Active Rev Match" 18 "2WD" 19 "Comfort" 20 "Start/Stop Disable" 21 "Crawl" 22 "Charge Plus" 23 "Baja" 24 "Max Power" 25 "Boat Ramp" ;
VAL_ 1500 DM3Unavailable 0 "FALSE" 1 "TRUE" ;
VAL_ 1500 DM3Status 0 "Inactive" 1 "Active" ;
VAL_ 1500 DM3Pending 0 "FALSE" 1 "TRUE" ;
VAL_ 1500 DM3Name 0 "None" 1 "Tour" 2 "Sport" 3 "Track" 4 "Winter" 5 "Off Road" 6 "Tow/Haul" 7 "Hold" 8 "Mountain" 9 "Personal" 10 "Custom" 11 "AWD" 12 "Economy" 13 "Automatic" 14 "EV" 15 "Grade Braking" 16 "Exhaust Brake" 17 "Active Rev Match" 18 "2WD" 19 "Comfort" 20 "Start/Stop Disable" 21 "Crawl" 22 "Charge Plus" 23 "Baja" 24 "Max Power" 25 "Boat Ramp" ;
VAL_ 1500 DM4Unavailable 0 "FALSE" 1 "TRUE" ;
VAL_ 1500 DM4Status 0 "Inactive" 1 "Active" ;
VAL_ 1500 DM4Pending 0 "FALSE" 1 "TRUE" ;
VAL_ 1500 DM4Name 0 "None" 1 "Tour" 2 "Sport" 3 "Track" 4 "Winter" 5 "Off Road" 6 "Tow/Haul" 7 "Hold" 8 "Mountain" 9 "Personal" 10 "Custom" 11 "AWD" 12 "Economy" 13 "Automatic" 14 "EV" 15 "Grade Braking" 16 "Exhaust Brake" 17 "Active Rev Match" 18 "2WD" 19 "Comfort" 20 "Start/Stop Disable" 21 "Crawl" 22 "Charge Plus" 23 "Baja" 24 "Max Power" 25 "Boat Ramp" ;
VAL_ 1500 DM5Unavailable 0 "FALSE" 1 "TRUE" ;
VAL_ 1500 DM5Status 0 "Inactive" 1 "Active" ;
VAL_ 1500 DM5Pending 0 "FALSE" 1 "TRUE" ;
VAL_ 1500 DM5Name 0 "None" 1 "Tour" 2 "Sport" 3 "Track" 4 "Winter" 5 "Off Road" 6 "Tow/Haul" 7 "Hold" 8 "Mountain" 9 "Personal" 10 "Custom" 11 "AWD" 12 "Economy" 13 "Automatic" 14 "EV" 15 "Grade Braking" 16 "Exhaust Brake" 17 "Active Rev Match" 18 "2WD" 19 "Comfort" 20 "Start/Stop Disable" 21 "Crawl" 22 "Charge Plus" 23 "Baja" 24 "Max Power" 25 "Boat Ramp" ;
VAL_ 1500 DM6Unavailable 0 "FALSE" 1 "TRUE" ;
VAL_ 1500 DM6Status 0 "Inactive" 1 "Active" ;
VAL_ 1500 DM6Pending 0 "FALSE" 1 "TRUE" ;
VAL_ 1500 DM6Name 0 "None" 1 "Tour" 2 "Sport" 3 "Track" 4 "Winter" 5 "Off Road" 6 "Tow/Haul" 7 "Hold" 8 "Mountain" 9 "Personal" 10 "Custom" 11 "AWD" 12 "Economy" 13 "Automatic" 14 "EV" 15 "Grade Braking" 16 "Exhaust Brake" 17 "Active Rev Match" 18 "2WD" 19 "Comfort" 20 "Start/Stop Disable" 21 "Crawl" 22 "Charge Plus" 23 "Baja" 24 "Max Power" 25 "Boat Ramp" ;
VAL_ 1500 DM7Unavailable 0 "FALSE" 1 "TRUE" ;
VAL_ 1500 DM7Status 0 "Inactive" 1 "Active" ;
VAL_ 1500 DM7Pending 0 "FALSE" 1 "TRUE" ;
VAL_ 1500 DM7Name 0 "None" 1 "Tour" 2 "Sport" 3 "Track" 4 "Winter" 5 "Off Road" 6 "Tow/Haul" 7 "Hold" 8 "Mountain" 9 "Personal" 10 "Custom" 11 "AWD" 12 "Economy" 13 "Automatic" 14 "EV" 15 "Grade Braking" 16 "Exhaust Brake" 17 "Active Rev Match" 18 "2WD" 19 "Comfort" 20 "Start/Stop Disable" 21 "Crawl" 22 "Charge Plus" 23 "Baja" 24 "Max Power" 25 "Boat Ramp" ;
VAL_ 1500 DM8Unavailable 0 "FALSE" 1 "TRUE" ;
VAL_ 1500 DM8Status 0 "Inactive" 1 "Active" ;
VAL_ 1500 DM8Pending 0 "FALSE" 1 "TRUE" ;
VAL_ 1500 DM8Name 0 "None" 1 "Tour" 2 "Sport" 3 "Track" 4 "Winter" 5 "Off Road" 6 "Tow/Haul" 7 "Hold" 8 "Mountain" 9 "Personal" 10 "Custom" 11 "AWD" 12 "Economy" 13 "Automatic" 14 "EV" 15 "Grade Braking" 16 "Exhaust Brake" 17 "Active Rev Match" 18 "2WD" 19 "Comfort" 20 "Start/Stop Disable" 21 "Crawl" 22 "Charge Plus" 23 "Baja" 24 "Max Power" 25 "Boat Ramp" ;
VAL_ 1464 BatLoStrtVehIndOn 0 "FALSE" 1 "TRUE" ;
VAL_ 1464 BatVlt_Inv 0 "FALSE" 1 "TRUE" ;
VAL_ 1464 LdShedRdcdFtrsIndOn 0 "FALSE" 1 "TRUE" ;
VAL_ 1464 BattVltIRq 0 "Battery Voltage OK" 1 "Battery Voltage Low" 2 "Battery Voltage High" 3 "Battery Voltage Very Low" ;
VAL_ 1464 RVCBatSOCOver 0 "None" 1 "Plant Assembly Mode" 2 "Charge Recovery Mode" 3 "Default Mode" ;
VAL_ 1464 RVC12VBatSOC_Inv 0 "FALSE" 1 "TRUE" ;
VAL_ 1464 ServBatChrgSysIndOn 0 "FALSE" 1 "TRUE" ;
VAL_ 1112 ACCCSV_Aux3Colr 0 "Setting Unknown" 1 "Off" 2 "Color Type 1" 3 "Color Type 2" 4 "Color Type 3" 5 "Color Type 4" 6 "Color Type 5" 7 "Color Type 6" 8 "Color Type 7" 9 "Color Type 8" 10 "Color Type 9" 11 "Color Type 10" 12 "Color Type 11" 13 "Color Type 12" 14 "Color Type 13" 15 "Color Type 14" 16 "Color Type 15" 17 "Color Type 16" 18 "Color Type 17" 19 "Color Type 18" 20 "Color Type 19" 21 "Color Type 20" 22 "Color Type 21" 23 "Color Type 22" 24 "Color Type 23" 25 "Color Type 24" 26 "Color Type 25" 27 "Color Type 26" 28 "Color Type 27" 29 "Color Type 28" 30 "Color Type 29" 31 "Color Type 30" 32 "Color Type 31" 33 "Color Type 32" 34 "Color Type 33" 35 "Color Type 34" 36 "Color Type 35" 37 "Color Type 36" 38 "Color Type 37" 39 "Color Type 38" 40 "Color Type 39" 41 "Color Type 40" 42 "Color Type 41" 43 "Color Type 42" 44 "Color Type 43" 45 "Color Type 44" 46 "Color Type 45" 47 "Color Type 46" 48 "Color Type 47" 49 "Color Type 48" 50 "Color Type 49" 51 "Color Type 50" 52 "Color Type 51" 53 "Color Type 52" 54 "Color Type 53" 55 "Color Type 54" 56 "Color Type 55" 57 "Color Type 56" 58 "Color Type 57" 59 "Color Type 58" 60 "Color Type 59" 61 "Color Type 60" 62 "Color Type 61" 63 "Color Type 62" 64 "Color Type 63" 65 "Color Type 64" 66 "Color Type 65" 67 "Color Type 66" 68 "Color Type 67" 69 "Color Type 68" 70 "Color Type 69" 71 "Color Type 70" 72 "Color Type 71" 73 "Color Type 72" 74 "Color Type 73" 75 "Color Type 74" 76 "Color Type 75" 77 "Color Type 76" 78 "Color Type 77" 79 "Color Type 78" 80 "Color Type 79" 81 "Color Type 80" 82 "Color Type 81" 83 "Color Type 82" 84 "Color Type 83" 85 "Color Type 84" 86 "Color Type 85" 87 "Color Type 86" 88 "Color Type 87" 89 "Color Type 88" 90 "Color Type 89" 91 "Color Type 90" 92 "Color Type 91" 93 "Color Type 92" 94 "Color Type 93" 95 "Color Type 94" 96 "Color Type 95" 97 "Color Type 96" 98 "Color Type 97" 99 "Color Type 98" 100 "Color Type 99" 101 "Color Type 100" 102 "Color Type 101" 103 "Color Type 102" 104 "Color Type 103" 105 "Color Type 104" 106 "Color Type 105" 107 "Color Type 106" 108 "Color Type 107" 109 "Color Type 108" 110 "Color Type 109" 111 "Color Type 110" 112 "Color Type 111" 113 "Color Type 112" 114 "Color Type 113" 115 "Color Type 114" 116 "Color Type 115" 117 "Color Type 116" 118 "Color Type 117" 119 "Color Type 118" 120 "Color Type 119" 121 "Color Type 120" 122 "Color Type 121" 123 "Color Type 122" 124 "Color Type 123" 125 "Color Type 124" 126 "Color Type 125" 127 "Color Type 126" ;
VAL_ 1112 ACCCSV_Aux2Colr 0 "Setting Unknown" 1 "Off" 2 "Color Type 1" 3 "Color Type 2" 4 "Color Type 3" 5 "Color Type 4" 6 "Color Type 5" 7 "Color Type 6" 8 "Color Type 7" 9 "Color Type 8" 10 "Color Type 9" 11 "Color Type 10" 12 "Color Type 11" 13 "Color Type 12" 14 "Color Type 13" 15 "Color Type 14" 16 "Color Type 15" 17 "Color Type 16" 18 "Color Type 17" 19 "Color Type 18" 20 "Color Type 19" 21 "Color Type 20" 22 "Color Type 21" 23 "Color Type 22" 24 "Color Type 23" 25 "Color Type 24" 26 "Color Type 25" 27 "Color Type 26" 28 "Color Type 27" 29 "Color Type 28" 30 "Color Type 29" 31 "Color Type 30" 32 "Color Type 31" 33 "Color Type 32" 34 "Color Type 33" 35 "Color Type 34" 36 "Color Type 35" 37 "Color Type 36" 38 "Color Type 37" 39 "Color Type 38" 40 "Color Type 39" 41 "Color Type 40" 42 "Color Type 41" 43 "Color Type 42" 44 "Color Type 43" 45 "Color Type 44" 46 "Color Type 45" 47 "Color Type 46" 48 "Color Type 47" 49 "Color Type 48" 50 "Color Type 49" 51 "Color Type 50" 52 "Color Type 51" 53 "Color Type 52" 54 "Color Type 53" 55 "Color Type 54" 56 "Color Type 55" 57 "Color Type 56" 58 "Color Type 57" 59 "Color Type 58" 60 "Color Type 59" 61 "Color Type 60" 62 "Color Type 61" 63 "Color Type 62" 64 "Color Type 63" 65 "Color Type 64" 66 "Color Type 65" 67 "Color Type 66" 68 "Color Type 67" 69 "Color Type 68" 70 "Color Type 69" 71 "Color Type 70" 72 "Color Type 71" 73 "Color Type 72" 74 "Color Type 73" 75 "Color Type 74" 76 "Color Type 75" 77 "Color Type 76" 78 "Color Type 77" 79 "Color Type 78" 80 "Color Type 79" 81 "Color Type 80" 82 "Color Type 81" 83 "Color Type 82" 84 "Color Type 83" 85 "Color Type 84" 86 "Color Type 85" 87 "Color Type 86" 88 "Color Type 87" 89 "Color Type 88" 90 "Color Type 89" 91 "Color Type 90" 92 "Color Type 91" 93 "Color Type 92" 94 "Color Type 93" 95 "Color Type 94" 96 "Color Type 95" 97 "Color Type 96" 98 "Color Type 97" 99 "Color Type 98" 100 "Color Type 99" 101 "Color Type 100" 102 "Color Type 101" 103 "Color Type 102" 104 "Color Type 103" 105 "Color Type 104" 106 "Color Type 105" 107 "Color Type 106" 108 "Color Type 107" 109 "Color Type 108" 110 "Color Type 109" 111 "Color Type 110" 112 "Color Type 111" 113 "Color Type 112" 114 "Color Type 113" 115 "Color Type 114" 116 "Color Type 115" 117 "Color Type 116" 118 "Color Type 117" 119 "Color Type 118" 120 "Color Type 119" 121 "Color Type 120" 122 "Color Type 121" 123 "Color Type 122" 124 "Color Type 123" 125 "Color Type 124" 126 "Color Type 125" 127 "Color Type 126" ;
VAL_ 1112 ACCCSV_Aux2Anm 0 "Setting Unknown" 1 "Off" 2 "Animation Type 1" 3 "Animation Type 2" 4 "Animation Type 3" 5 "Animation Type 4" 6 "Animation Type 5" 7 "Animation Type 6" 8 "Animation Type 7" 9 "Animation Type 8" 10 "Animation Type 9" 11 "Animation Type 10" 12 "Animation Type 11" 13 "Animation Type 12" 14 "Animation Type 13" 15 "Animation Type 14" ;
VAL_ 1112 ACCCSV_Aux2Brghtns 0 "Setting Unknown" 1 "Brightness Level 1" 2 "Brightness Level 2" 3 "Brightness Level 3" 4 "Brightness Level 4" ;
VAL_ 1112 ACCCSV_Aux3Anm 0 "Setting Unknown" 1 "Off" 2 "Animation Type 1" 3 "Animation Type 2" 4 "Animation Type 3" 5 "Animation Type 4" 6 "Animation Type 5" 7 "Animation Type 6" 8 "Animation Type 7" 9 "Animation Type 8" 10 "Animation Type 9" 11 "Animation Type 10" 12 "Animation Type 11" 13 "Animation Type 12" 14 "Animation Type 13" 15 "Animation Type 14" ;
VAL_ 1112 FrtSnshdActlPstn 0 "0%" 1 "10%" 2 "20%" 3 "30%" 4 "40%" 5 "50%" 6 "60%" 7 "70%" 8 "80%" 9 "90%" 10 "100%" 11 "Between Positions" 12 "Comfort Open" ;
VAL_ 1112 ACCCSV_Aux3Brghtns 0 "Setting Unknown" 1 "Brightness Level 1" 2 "Brightness Level 2" 3 "Brightness Level 3" 4 "Brightness Level 4" ;
VAL_ 1112 WndPstnLF_Inv 0 "FALSE" 1 "TRUE" ;
VAL_ 1112 WndPstnLR_Inv 0 "FALSE" 1 "TRUE" ;
VAL_ 1112 WndPstnRF_Inv 0 "FALSE" 1 "TRUE" ;
VAL_ 1112 WndPstnRR_Inv 0 "FALSE" 1 "TRUE" ;
VAL_ 1968 VehMonSrvrRtryFreq_Inv 0 "FALSE" 1 "TRUE" ;
VAL_ 1098 VehMonDatRcrdMaxBytes_Inv 0 "FALSE" 1 "TRUE" ;
VAL_ 1969 VehMonFreqLvl3AftDatRcrdsRqrd_In 0 "FALSE" 1 "TRUE" ;
VAL_ 1097 VehMonLossPwrTmRqrd_Inv 0 "FALSE" 1 "TRUE" ;
VAL_ 1097 VehMonFreqLvl3BfrDatRcrdsRqrd_In 0 "FALSE" 1 "TRUE" ;
VAL_ 1097 VehMonDatStrgeMaxDys_Inv 0 "FALSE" 1 "TRUE" ;
VAL_ 1970 VehMonNonLvl3DatFreq_Inv 0 "FALSE" 1 "TRUE" ;
VAL_ 1970 VehMonLvl3DatFreq_Inv 0 "FALSE" 1 "TRUE" ;
VAL_ 1970 VehMonSrvrRtryCnt_Inv 0 "FALSE" 1 "TRUE" ;
VAL_ 1970 VehMonSrvrConctSeltn_Inv 0 "FALSE" 1 "TRUE" ;
VAL_ 1970 VehMonSrvrConctSeltn 0 "SOS" 1 "Govt" ;
VAL_ 663 SyncTmrVal_Inv 0 "FALSE" 1 "TRUE" ;
VAL_ 663 FtrMinPrtyAllwd_Inv 0 "FALSE" 1 "TRUE" ;
VAL_ 663 WkupCadenceMult_Inv 0 "FALSE" 1 "TRUE" ;
